VERSION "dbc-export 1 2025.20.8"

NS_ :

BS_:

BU_: ADSP APB APP APS APSB BB BMS CC CMP CMPD CP DAS DI DIF DIR DPB EPAS3P EPAS3S EPASTP EPASTS EPBL EPBR ESP EVSE FC GTW HCML HCMR HVP IBST ICR IDB LS OCS1P PARK PCS PM PMF PMR PNCD PTC RADC RCM RCM2 RCM3 RCU SCCM SCM SCS SDCR TAS TCU TPMS TRCM UI UIS UMC USM VC VCFRONT VCLEFT VCRIGHT VCSEC VEH

BO_ 259 VCRIGHT_doorStatus: 8 VCRIGHT
 SG_ VCRIGHT_doorClosureStatusFront : 0|4@1+ (1,0) [0|15] "" Vector__XXX
 SG_ VCRIGHT_doorClosureStatusRear : 4|4@1+ (1,0) [0|15] "" Vector__XXX
 SG_ VCRIGHT_frontLatchSwitch : 8|1@1+ (1,0) [0|1] "" Vector__XXX
 SG_ VCRIGHT_rearLatchSwitch : 9|1@1+ (1,0) [0|1] "" Vector__XXX
 SG_ VCRIGHT_frontHandlePulled : 10|1@1+ (1,0) [0|1] "" Vector__XXX
 SG_ VCRIGHT_rearHandlePulled : 11|1@1+ (1,0) [0|1] "" Vector__XXX
 SG_ VCRIGHT_frontRelActuatorSwitch : 12|1@1+ (1,0) [0|1] "" Vector__XXX
 SG_ VCRIGHT_rearRelActuatorSwitch : 13|1@1+ (1,0) [0|1] "" Vector__XXX
 SG_ VCRIGHT_frontLatchStatus : 14|4@1+ (1,0) [0|15] "" Vector__XXX
 SG_ VCRIGHT_rearLatchStatus : 18|4@1+ (1,0) [0|15] "" Vector__XXX
 SG_ VCRIGHT_lastDoorReqSourceFront : 22|3@1+ (1,0) [0|7] "" Vector__XXX
 SG_ VCRIGHT_lastDoorReqSourceRear : 25|3@1+ (1,0) [0|7] "" Vector__XXX
 SG_ VCRIGHT_reservedForBackCompat : 28|2@1+ (1,0) [0|3] "" Vector__XXX
 SG_ VCRIGHT_frontHandlePulledPersist : 30|1@1+ (1,0) [0|1] "" Vector__XXX
 SG_ VCRIGHT_frontIntSwitchPressed : 31|1@1+ (1,0) [0|1] "" Vector__XXX
 SG_ VCRIGHT_rearIntSwitchPressed : 32|1@1+ (1,0) [0|1] "" Vector__XXX
 SG_ VCRIGHT_mirrorTiltXPosition : 33|8@1+ (0.02,0) [0|5] "V" Vector__XXX
 SG_ VCRIGHT_mirrorTiltYPosition : 41|8@1+ (0.02,0) [0|5] "V" Vector__XXX
 SG_ VCRIGHT_mirrorState : 49|3@1+ (1,0) [0|7] "" Vector__XXX
 SG_ VCRIGHT_mirrorFoldState : 52|3@1+ (1,0) [0|7] "" Vector__XXX
 SG_ VCRIGHT_mirrorDipped : 55|1@1+ (1,0) [0|1] "" Vector__XXX
 SG_ VCRIGHT_trunkLatchStatus : 56|4@1+ (1,0) [0|15] "" Vector__XXX
 SG_ VCRIGHT_mirrorRecallState : 60|3@1+ (1,0) [0|7] "" Vector__XXX
 SG_ VCRIGHT_rearHandlePulledPersist : 63|1@1+ (1,0) [0|1] "" Vector__XXX

BO_ 2010 VCRIGHT_doorStatus2: 8 VCRIGHT
 SG_ VCRIGHT_doorStatus2Index M : 0|1@1+ (1,0) [0|1] "" Vector__XXX
 SG_ VCRIGHT_frontLatchRelDuty m1 : 8|8@1+ (1,0) [0|255] "%" Vector__XXX
 SG_ VCRIGHT_BPillarCameraHeaterState m1 : 16|3@1+ (1,0) [0|7] "" Vector__XXX
 SG_ VCRIGHT_doorLatchAjarSwitchVolta m1 : 24|8@1+ (0.02,0) [0|5] "V" Vector__XXX
 SG_ VCRIGHT_doorLatchAjarSwitch_0001 m1 : 32|8@1+ (0.02,0) [0|5] "V" Vector__XXX
 SG_ VCRIGHT_BPillarCameraHeaterCurre m1 : 40|6@1+ (0.02,0) [0|1.24] "A" Vector__XXX
 SG_ VCRIGHT_mirrorTiltXOffset m1 : 48|8@1- (0.02,0) [-2.5|2.5] "V" Vector__XXX
 SG_ VCRIGHT_mirrorTiltYOffset m1 : 56|8@1- (0.02,0) [-2.5|2.5] "V" Vector__XXX

BO_ 915 VCRIGHT_epbmDebug: 8 VCRIGHT
 SG_ VCRIGHT_epbmDebugIndex M : 0|1@1+ (1,0) [0|1] "" Vector__XXX
 SG_ VCRIGHT_epbmCaliperState m0 : 1|3@1+ (1,0) [0|7] "" Vector__XXX
 SG_ VCRIGHT_epbmMotorEnabled m0 : 4|1@1+ (1,0) [0|1] "" Vector__XXX
 SG_ VCRIGHT_epbMotorCurrent m0 : 5|11@1+ (0.01,0) [0|20.47] "A" Vector__XXX
 SG_ VCRIGHT_epbmApplyVoltage m0 : 16|11@1+ (0.01,0) [0|20.47] "A" Vector__XXX
 SG_ VCRIGHT_epbmReleaseVoltage m0 : 27|11@1+ (0.01,0) [0|20.47] "A" Vector__XXX
 SG_ VCRIGHT_summonFaultReason m0 : 40|5@1+ (1,0) [0|31] "" Vector__XXX
 SG_ VCRIGHT_epbSummonState m0 : 45|3@1+ (1,0) [0|7] "" Vector__XXX
 SG_ VCRIGHT_epbmSummonState m0 : 48|3@1+ (1,0) [0|7] "" Vector__XXX
 SG_ VCRIGHT_epbUnitStatus m0 : 51|5@1+ (1,0) [0|31] "" Vector__XXX
 SG_ VCRIGHT_epbmFaultStatus m0 : 56|2@1+ (1,0) [0|3] "" Vector__XXX
 SG_ VCRIGHT_epbFaultStatus m0 : 58|2@1+ (1,0) [0|3] "" Vector__XXX
 SG_ VCRIGHT_epbmSystemStatus m0 : 60|4@1+ (1,0) [0|15] "" Vector__XXX

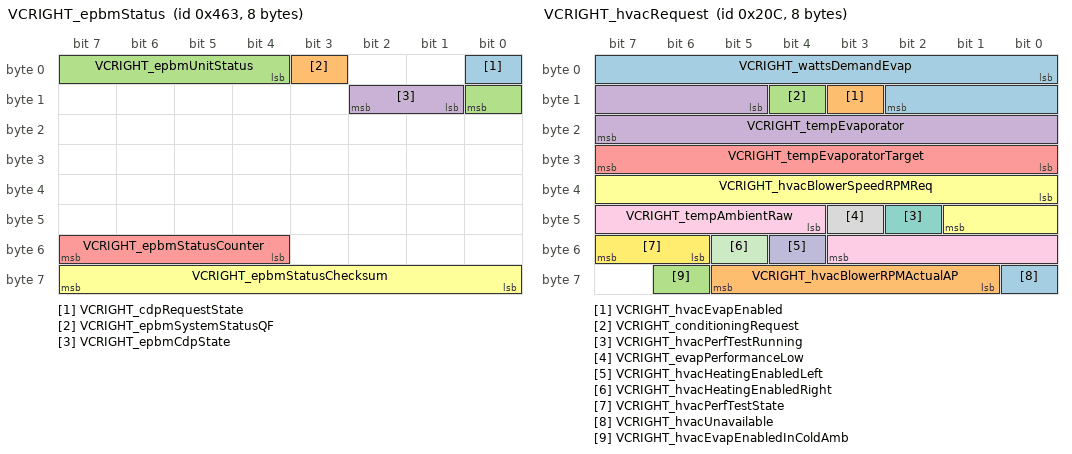
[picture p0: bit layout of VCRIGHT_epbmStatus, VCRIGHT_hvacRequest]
BO_ 1123 VCRIGHT_epbmStatus: 8 VCRIGHT
 SG_ VCRIGHT_cdpRequestState : 0|1@1+ (1,0) [0|1] "" Vector__XXX
 SG_ VCRIGHT_epbmSystemStatusQF : 3|1@1+ (1,0) [0|1] "" Vector__XXX
 SG_ VCRIGHT_epbmUnitStatus : 4|5@1+ (1,0) [0|31] "" Vector__XXX
 SG_ VCRIGHT_epbmCdpState : 9|2@1+ (1,0) [0|3] "" Vector__XXX
 SG_ VCRIGHT_epbmStatusCounter : 52|4@1+ (1,0) [0|15] "" Vector__XXX
 SG_ VCRIGHT_epbmStatusChecksum : 56|8@1+ (1,0) [0|255] "" Vector__XXX

BO_ 524 VCRIGHT_hvacRequest: 8 VCRIGHT
 SG_ VCRIGHT_wattsDemandEvap : 0|11@1+ (5,0) [0|10000] "W" Vector__XXX
 SG_ VCRIGHT_hvacEvapEnabled : 11|1@1+ (1,0) [0|1] "" Vector__XXX
 SG_ VCRIGHT_conditioningRequest : 12|1@1+ (1,0) [0|1] "" Vector__XXX
 SG_ VCRIGHT_tempEvaporator : 13|11@1+ (0.1,-40) [-40|105] "degC" Vector__XXX
 SG_ VCRIGHT_tempEvaporatorTarget : 24|8@1+ (0.2,0) [0|50] "degC" Vector__XXX
 SG_ VCRIGHT_hvacBlowerSpeedRPMReq : 32|10@1+ (5,0) [0|5115] "RPM" Vector__XXX
 SG_ VCRIGHT_hvacPerfTestRunning : 42|1@1+ (1,0) [0|1] "" Vector__XXX
 SG_ VCRIGHT_evapPerformanceLow : 43|1@1+ (1,0) [0|1] "" Vector__XXX
 SG_ VCRIGHT_tempAmbientRaw : 44|8@1+ (0.5,-40) [-40|80] "degC" Vector__XXX
 SG_ VCRIGHT_hvacHeatingEnabledLeft : 52|1@1+ (1,0) [0|1] "" Vector__XXX
 SG_ VCRIGHT_hvacHeatingEnabledRight : 53|1@1+ (1,0) [0|1] "" Vector__XXX
 SG_ VCRIGHT_hvacPerfTestState : 54|2@1+ (1,0) [0|3] "" Vector__XXX
 SG_ VCRIGHT_hvacUnavailable : 56|1@1+ (1,0) [0|1] "" Vector__XXX
 SG_ VCRIGHT_hvacBlowerRPMActualAP : 57|5@1+ (200,0) [0|4200] "rpm" Vector__XXX
 SG_ VCRIGHT_hvacEvapEnabledInColdAmb : 62|1@1+ (1,0) [0|1] "" Vector__XXX

BO_ 579 VCRIGHT_hvacStatus: 8 VCRIGHT
 SG_ VCRIGHT_hvacStatusIndex M : 0|3@1+ (1,0) [0|7] "" Vector__XXX
 SG_ VCRIGHT_childModeHVACState m0 : 20|2@1+ (1,0) [0|3] "" Vector__XXX
 SG_ VCRIGHT_dogModeState m0 : 22|4@1+ (1,0) [0|15] "" Vector__XXX
 SG_ VCRIGHT_hvacCabinTempEstValid m0 : 26|1@1+ (1,0) [0|1] "" Vector__XXX
 SG_ VCRIGHT_COPNotRunningReasonFilte m0 : 27|3@1+ (1,0) [0|7] "" Vector__XXX
 SG_ VCRIGHT_hvacCabinTempEst m0 : 30|11@1+ (0.1,-40) [-40|164] "degC" Vector__XXX
 SG_ VCRIGHT_hvacAirDistributionMode m0 : 41|3@1+ (1,0) [0|7] "" Vector__XXX
 SG_ VCRIGHT_hvacBlowerSegment m0 : 44|4@1+ (1,0) [0|15] "" Vector__XXX
 SG_ VCRIGHT_hvacRecirc m0 : 48|2@1+ (1,0) [0|3] "" Vector__XXX
 SG_ VCRIGHT_hvacACRunning m0 : 50|1@1+ (1,0) [0|1] "" Vector__XXX
 SG_ VCRIGHT_hvacPowerState m0 : 51|3@1+ (1,0) [0|7] "" Vector__XXX
 SG_ VCRIGHT_hvacVentStatus m0 : 54|2@1+ (1,0) [0|3] "" Vector__XXX
 SG_ VCRIGHT_hvacSecondRowState m0 : 56|3@1+ (1,0) [0|7] "" Vector__XXX
 SG_ VCRIGHT_hvacSystemNominal m0 : 59|1@1+ (1,0) [0|1] "" Vector__XXX
 SG_ VCRIGHT_hvacModelInitStatus m0 : 60|4@1+ (1,0) [0|15] "" Vector__XXX
 SG_ VCRIGHT_hvacMassflowRefrigSysRig m1 : 3|7@1+ (1,0) [0|125] "g/s" Vector__XXX
 SG_ VCRIGHT_hvacRecircDoorPercent m1 : 10|6@1+ (1.6,0) [0|100] "%" Vector__XXX
 SG_ VCRIGHT_tempDuctLeft m1 : 16|8@1+ (0.5,-22) [-22|105] "degC" Vector__XXX
 SG_ VCRIGHT_hvacMassflowRefrigSystem m1 : 24|8@1+ (1,0) [0|250] "g/s" Vector__XXX
 SG_ VCRIGHT_tempDuctRight m1 : 32|8@1+ (0.5,-22) [-22|105] "degC" Vector__XXX
 SG_ VCRIGHT_hvacMassflowRefrigSysLef m1 : 40|7@1+ (1,0) [0|125] "g/s" Vector__XXX
 SG_ VCRIGHT_hvacDuctTargetLeft m1 : 48|8@1+ (0.5,-40) [-40|80] "degC" Vector__XXX
 SG_ VCRIGHT_hvacDuctTargetRight m1 : 56|8@1+ (0.5,-40) [-40|80] "degC" Vector__XXX
 SG_ VCRIGHT_enableTripleCameraFanPow m2 : 9|1@1+ (1,0) [0|1] "" Vector__XXX
 SG_ VCRIGHT_tempDuctRightUpper m2 : 10|8@1+ (0.5,-22) [-22|105] "degC" Vector__XXX
 SG_ VCRIGHT_hpSplitTempsEnabled m2 : 18|1@1+ (1,0) [0|1] "" Vector__XXX
 SG_ VCRIGHT_hvacEvapInletTempEstimat m2 : 19|10@1+ (0.13,-40) [-40|90] "degC" Vector__XXX
 SG_ VCRIGHT_tempMonitorNotNominal m2 : 29|1@1+ (1,0) [0|1] "" Vector__XXX
 SG_ VCRIGHT_hvacCabinAtTempTarget m2 : 30|1@1+ (1,0) [0|1] "" Vector__XXX
 SG_ VCRIGHT_hvacReqSecondRow m2 : 31|1@1+ (1,0) [0|1] "" Vector__XXX
 SG_ VCRIGHT_hvacAirflowReason m2 : 32|5@1+ (1,0) [0|31] "" Vector__XXX
 SG_ VCRIGHT_autoHvacBlowerShouldLimi m2 : 37|1@1+ (1,0) [0|1] "" Vector__XXX
 SG_ VCRIGHT_solarLoadOnVehicle m2 : 40|8@1+ (4,0) [0|1020] "W/m2" Vector__XXX
 SG_ VCRIGHT_refrigDistCommanded m2 : 48|1@1+ (1,0) [0|1] "" Vector__XXX
 SG_ VCRIGHT_hvacFrontRightSeatFanSta m2 : 49|2@1+ (1,0) [0|3] "" Vector__XXX
 SG_ VCRIGHT_hvacFrontLeftSeatFanStat m2 : 51|2@1+ (1,0) [0|3] "" Vector__XXX
 SG_ VCRIGHT_hvacFrontRightSeatHeatSt m3 : 4|2@1+ (1,0) [0|3] "" Vector__XXX
 SG_ VCRIGHT_hvacSeatFrontLeftTempTar m3 : 6|8@1+ (0.5,-40) [-40|80] "degC" Vector__XXX
 SG_ VCRIGHT_hvacManualToAutoNotify m3 : 14|3@1+ (1,0) [0|7] "" Vector__XXX
 SG_ VCRIGHT_hvacRequestsFullAuto m3 : 17|3@1+ (1,0) [0|7] "" Vector__XXX
 SG_ VCRIGHT_passengerPresentHvacCycl m3 : 21|1@1+ (1,0) [0|1] "" Vector__XXX
 SG_ VCRIGHT_hvacRequestsAutoIntake m3 : 22|1@1+ (1,0) [0|1] "" Vector__XXX
 SG_ VCRIGHT_steeringWheelHeatStatus m3 : 24|2@1+ (1,0) [0|3] "" Vector__XXX
 SG_ VCRIGHT_autoDefogStatus m3 : 26|2@1+ (1,0) [0|3] "" Vector__XXX
 SG_ VCRIGHT_solarElevation m3 : 31|9@1- (0.5,0) [-127.5|127.5] "deg" Vector__XXX
 SG_ VCRIGHT_minsToSunrise m3 : 40|8@1+ (10,0) [0|2540] "min" Vector__XXX
 SG_ VCRIGHT_minsToSunset m3 : 48|8@1+ (10,0) [0|2540] "min" Vector__XXX
 SG_ VCRIGHT_hvacLimitedReasonRight m3 : 56|3@1+ (1,0) [0|7] "" Vector__XXX
 SG_ VCRIGHT_hvacLimitedReasonLeft m3 : 59|3@1+ (1,0) [0|7] "" Vector__XXX
 SG_ VCRIGHT_hvacOverheatProtActive m3 : 63|1@1+ (1,0) [0|1] "" Vector__XXX
 SG_ VCRIGHT_tempDuctLeftUpper m4 : 10|8@1+ (0.5,-22) [-22|105] "degC" Vector__XXX
 SG_ VCRIGHT_hvacFrontLeftSeatHeatSta m4 : 18|2@1+ (1,0) [0|3] "" Vector__XXX
 SG_ VCRIGHT_hvacQdotLeft m4 : 20|14@1+ (1,-8191) [-8191|8191] "W" Vector__XXX
 SG_ VCRIGHT_hvacQdotRight m4 : 34|14@1+ (1,-8191) [-8191|8191] "W" Vector__XXX
 SG_ VCRIGHT_tempDuctLeftLower m4 : 48|8@1+ (0.5,-22) [-22|105] "degC" Vector__XXX
 SG_ VCRIGHT_tempDuctRightLower m4 : 56|8@1+ (0.5,-22) [-22|105] "degC" Vector__XXX
 SG_ VCRIGHT_modeledCabinPressure m5 : 24|8@1+ (1,0) [0|255] "Pa" Vector__XXX
 SG_ VCRIGHT_blowerTorqueIndex m5 : 32|7@1+ (1,0) [0|127] "%" Vector__XXX
 SG_ VCRIGHT_autoSwingLeftPosX m5 : 39|8@1+ (0.4,0) [0|100] "%" Vector__XXX
 SG_ VCRIGHT_autoSwingRightPositionX m5 : 48|8@1+ (0.4,0) [0|100] "%" Vector__XXX
 SG_ VCRIGHT_autoSwingAvailable m5 : 56|1@1+ (1,0) [0|1] "" Vector__XXX

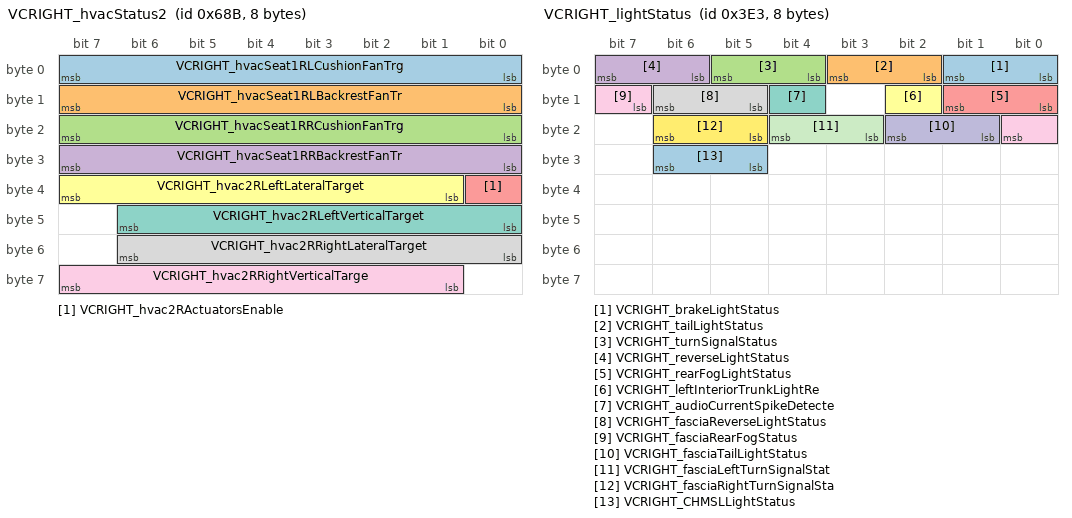
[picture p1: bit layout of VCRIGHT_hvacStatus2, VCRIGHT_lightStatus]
BO_ 1675 VCRIGHT_hvacStatus2: 8 VCRIGHT
 SG_ VCRIGHT_hvacSeat1RLCushionFanTrg : 0|8@1+ (0.5,0) [0|100] "%" Vector__XXX
 SG_ VCRIGHT_hvacSeat1RLBackrestFanTr : 8|8@1+ (0.5,0) [0|100] "%" Vector__XXX
 SG_ VCRIGHT_hvacSeat1RRCushionFanTrg : 16|8@1+ (0.5,0) [0|100] "%" Vector__XXX
 SG_ VCRIGHT_hvacSeat1RRBackrestFanTr : 24|8@1+ (0.5,0) [0|100] "%" Vector__XXX
 SG_ VCRIGHT_hvac2RActuatorsEnable : 32|1@1+ (1,0) [0|1] "" Vector__XXX
 SG_ VCRIGHT_hvac2RLeftLateralTarget : 33|7@1+ (1,0) [0|100] "%" Vector__XXX
 SG_ VCRIGHT_hvac2RLeftVerticalTarget : 40|7@1+ (1,0) [0|100] "%" Vector__XXX
 SG_ VCRIGHT_hvac2RRightLateralTarget : 48|7@1+ (1,0) [0|100] "%" Vector__XXX
 SG_ VCRIGHT_hvac2RRightVerticalTarge : 57|7@1+ (1,0) [0|100] "%" Vector__XXX

BO_ 774 VCRIGHT_info: 8 VCRIGHT
 SG_ VCRIGHT_infoIndex M : 0|8@1+ (1,0) [0|255] "" Vector__XXX
 SG_ VCRIGHT_infoBuildType m10 : 8|3@1+ (1,0) [0|7] "" Vector__XXX
 SG_ VCRIGHT_infoBuildConfigId m10 : 16|16@1+ (1,0) [0|65535] "" Vector__XXX
 SG_ VCRIGHT_infoHardwareId m10 : 32|16@1+ (1,0) [0|65535] "" Vector__XXX
 SG_ VCRIGHT_infoComponentId m10 : 48|16@1+ (1,0) [0|65535] "" Vector__XXX
 SG_ VCRIGHT_infoPcbaId m11 : 8|8@1+ (1,0) [0|255] "" Vector__XXX
 SG_ VCRIGHT_infoAssemblyId m11 : 16|8@1+ (1,0) [0|255] "" Vector__XXX
 SG_ VCRIGHT_infoUsageId m11 : 24|16@1+ (1,0) [0|65535] "" Vector__XXX
 SG_ VCRIGHT_infoSubUsageId m11 : 40|16@1+ (1,0) [0|65535] "" Vector__XXX
 SG_ VCRIGHT_infoAppCrc m13 : 8|32@1+ (1,0) [0|4294967295] "" Vector__XXX
 SG_ VCRIGHT_infoAppGitHash m17 : 8|56@1+ (1,0) [0|7.20575940379e+16] "" Vector__XXX
 SG_ VCRIGHT_infoBootGitHash m18 : 8|56@1+ (1,0) [0|7.20575940379e+16] "" Vector__XXX
 SG_ VCRIGHT_infoPlatformType m19 : 8|8@1+ (1,0) [0|255] "" Vector__XXX
 SG_ VCRIGHT_infoBootUdsProtoVersion m20 : 8|16@1+ (1,0) [0|65535] "" Vector__XXX
 SG_ VCRIGHT_infoBootCrc m20 : 24|32@1+ (1,0) [0|4294967295] "" Vector__XXX

BO_ 995 VCRIGHT_lightStatus: 8 VCRIGHT
 SG_ VCRIGHT_brakeLightStatus : 0|2@1+ (1,0) [0|3] "" Vector__XXX
 SG_ VCRIGHT_tailLightStatus : 2|2@1+ (1,0) [0|3] "" Vector__XXX
 SG_ VCRIGHT_turnSignalStatus : 4|2@1+ (1,0) [0|3] "" Vector__XXX
 SG_ VCRIGHT_reverseLightStatus : 6|2@1+ (1,0) [0|3] "" Vector__XXX
 SG_ VCRIGHT_rearFogLightStatus : 8|2@1+ (1,0) [0|3] "" Vector__XXX
 SG_ VCRIGHT_leftInteriorTrunkLightRe : 10|1@1+ (1,0) [0|1] "" Vector__XXX
 SG_ VCRIGHT_audioCurrentSpikeDetecte : 12|1@1+ (1,0) [0|1] "" Vector__XXX
 SG_ VCRIGHT_fasciaReverseLightStatus : 13|2@1+ (1,0) [0|3] "" Vector__XXX
 SG_ VCRIGHT_fasciaRearFogStatus : 15|2@1+ (1,0) [0|3] "" Vector__XXX
 SG_ VCRIGHT_fasciaTailLightStatus : 17|2@1+ (1,0) [0|3] "" Vector__XXX
 SG_ VCRIGHT_fasciaLeftTurnSignalStat : 19|2@1+ (1,0) [0|3] "" Vector__XXX
 SG_ VCRIGHT_fasciaRightTurnSignalSta : 21|2@1+ (1,0) [0|3] "" Vector__XXX
 SG_ VCRIGHT_CHMSLLightStatus : 29|2@1+ (1,0) [0|3] "" Vector__XXX

BO_ 1803 VCRIGHT_logging0point1Hz: 8 VCRIGHT
 SG_ VCRIGHT_logging0point1HzIndex M : 0|4@1+ (1,0) [0|15] "" Vector__XXX
 SG_ VCRIGHT_cabinAirFilterLifeRemain m2 : 8|7@1+ (1,0) [0|127] "%" Vector__XXX
 SG_ VCRIGHT_HEPAAirFilterLifeRemaini m2 : 16|7@1+ (1,0) [0|127] "%" Vector__XXX
 SG_ VCRIGHT_leftPTCCompromisedRod m2 : 24|3@1+ (1,0) [0|7] "" Vector__XXX
 SG_ VCRIGHT_rightPTCCompromisedRod m2 : 27|3@1+ (1,0) [0|7] "" Vector__XXX
 SG_ VCRIGHT_hepaFilterHealthScore m2 : 32|7@1+ (1,0) [0|127] "%" Vector__XXX
 SG_ VCRIGHT_cabinFilterHealthScore m2 : 40|7@1+ (1,0) [0|127] "%" Vector__XXX
 SG_ VCRIGHT_cabinTempBreathLevelFOff m2 : 47|8@1+ (0.5,-40) [-40|80] "degC" Vector__XXX
 SG_ VCRIGHT_airDistributionModeAdjus m2 : 55|9@1+ (0.001,1) [1|1.5] "-" Vector__XXX
 SG_ VCRIGHT_hvacLHBleedEndStop m3 : 8|8@1+ (0.02,0) [0|5] "V" Vector__XXX
 SG_ VCRIGHT_hvacRHBleedEndStop m3 : 16|8@1+ (0.02,0) [0|5] "V" Vector__XXX
 SG_ VCRIGHT_hvacLHVaneEndStop m3 : 24|8@1+ (0.02,0) [0|5] "V" Vector__XXX
 SG_ VCRIGHT_hvacRHVaneEndStop m3 : 32|8@1+ (0.02,0) [0|5] "V" Vector__XXX
 SG_ VCRIGHT_hvacUpperModeEndStop m3 : 40|8@1+ (0.02,0) [0|5] "V" Vector__XXX
 SG_ VCRIGHT_hvacLowerModeEndStop m3 : 48|8@1+ (0.02,0) [0|5] "V" Vector__XXX
 SG_ VCRIGHT_hvacIntakeEndStop m3 : 56|8@1+ (0.02,0) [0|5] "V" Vector__XXX
 SG_ VCRIGHT_hvacLHBleedZeroStop m4 : 8|8@1+ (0.02,0) [0|5] "V" Vector__XXX
 SG_ VCRIGHT_hvacRHBleedZeroStop m4 : 16|8@1+ (0.02,0) [0|5] "V" Vector__XXX
 SG_ VCRIGHT_hvacLHVaneZeroStop m4 : 24|8@1+ (0.02,0) [0|5] "V" Vector__XXX
 SG_ VCRIGHT_hvacRHVaneZeroStop m4 : 32|8@1+ (0.02,0) [0|5] "V" Vector__XXX
 SG_ VCRIGHT_hvacUpperModeZeroStop m4 : 40|8@1+ (0.02,0) [0|5] "V" Vector__XXX
 SG_ VCRIGHT_hvacLowerModeZeroStop m4 : 48|8@1+ (0.02,0) [0|5] "V" Vector__XXX
 SG_ VCRIGHT_hvacIntakeZeroStop m4 : 56|8@1+ (0.02,0) [0|5] "V" Vector__XXX
 SG_ VCRIGHT_ambientTempLimp m6 : 8|8@1+ (0.5,-40) [-40|80] "degC" Vector__XXX
 SG_ VCRIGHT_cabinProbeTempLimp m6 : 16|8@1+ (0.5,-40) [-40|80] "degC" Vector__XXX
 SG_ VCRIGHT_thsTempLimp m6 : 24|8@1+ (0.5,-40) [-40|80] "degC" Vector__XXX
 SG_ VCRIGHT_thsCabinWaterMassLimp m6 : 32|8@1+ (0.5,0) [0|124] "g/kg" Vector__XXX
 SG_ VCRIGHT_thsSolarIrradianceLimp m6 : 40|8@1+ (5,0) [0|1270] "W/m2" Vector__XXX
 SG_ VCRIGHT_silentWakeRecordCount m6 : 48|5@1+ (1,0) [0|31] "" Vector__XXX
 SG_ VCRIGHT_evapCondensateMass m7 : 8|8@1+ (2,0) [0|500] "g" Vector__XXX
 SG_ VCRIGHT_airwaveRightLateralTotal m7 : 16|16@1+ (6100,0) [0|399763500] "deg" Vector__XXX
 SG_ VCRIGHT_airwaveLeftLateralTotalT m7 : 32|16@1+ (6100,0) [0|399763500] "deg" Vector__XXX

BO_ 611 VCRIGHT_logging10Hz: 8 VCRIGHT
 SG_ VCRIGHT_logging10HzIndex M : 0|3@1+ (1,0) [0|7] "" Vector__XXX
 SG_ VCRIGHT_hvacLHBleedTarget m0 : 8|8@1+ (0.4,0) [0|100] "%" Vector__XXX
 SG_ VCRIGHT_hvacRHBleedTarget m0 : 16|8@1+ (0.4,0) [0|100] "%" Vector__XXX
 SG_ VCRIGHT_hvacLHVaneTarget m0 : 24|8@1+ (0.4,0) [0|100] "%" Vector__XXX
 SG_ VCRIGHT_hvacRHVaneTarget m0 : 32|8@1+ (0.4,0) [0|100] "%" Vector__XXX
 SG_ VCRIGHT_hvacUpperModeTarget m0 : 40|8@1+ (0.4,0) [0|100] "%" Vector__XXX
 SG_ VCRIGHT_hvacLowerModeTarget m0 : 48|8@1+ (0.4,0) [0|100] "%" Vector__XXX
 SG_ VCRIGHT_hvacIntakeTarget m0 : 56|8@1+ (0.4,0) [0|100] "%" Vector__XXX
 SG_ VCRIGHT_hvacLHBleedPosition m1 : 8|8@1+ (0.4,0) [0|100] "%" Vector__XXX
 SG_ VCRIGHT_hvacRHBleedPosition m1 : 16|8@1+ (0.4,0) [0|100] "%" Vector__XXX
 SG_ VCRIGHT_hvacLHVanePosition m1 : 24|8@1+ (0.4,0) [0|100] "%" Vector__XXX
 SG_ VCRIGHT_hvacRHVanePosition m1 : 32|8@1+ (0.4,0) [0|100] "%" Vector__XXX
 SG_ VCRIGHT_hvacUpperModePosition m1 : 40|8@1+ (0.4,0) [0|100] "%" Vector__XXX
 SG_ VCRIGHT_hvacLowerModePosition m1 : 48|8@1+ (0.4,0) [0|100] "%" Vector__XXX
 SG_ VCRIGHT_hvacIntakePosition m1 : 56|8@1+ (0.4,0) [0|100] "%" Vector__XXX
 SG_ VCRIGHT_hvacLHBleedActuatorState m2 : 3|2@1+ (1,0) [0|3] "" Vector__XXX
 SG_ VCRIGHT_hvacRHBleedActuatorState m2 : 5|2@1+ (1,0) [0|3] "" Vector__XXX
 SG_ VCRIGHT_hvacLHVaneActuatorState m2 : 8|2@1+ (1,0) [0|3] "" Vector__XXX
 SG_ VCRIGHT_hvacRHVaneActuatorState m2 : 10|2@1+ (1,0) [0|3] "" Vector__XXX
 SG_ VCRIGHT_hvacUpperModeActState m2 : 12|2@1+ (1,0) [0|3] "" Vector__XXX
 SG_ VCRIGHT_hvacLowerModeActState m2 : 14|2@1+ (1,0) [0|3] "" Vector__XXX
 SG_ VCRIGHT_hvacIntakeActuatorState m2 : 16|2@1+ (1,0) [0|3] "" Vector__XXX
 SG_ VCRIGHT_EvapPulldownBiasActive m2 : 20|1@1+ (1,0) [0|1] "" Vector__XXX
 SG_ VCRIGHT_tempDatLeftEst m2 : 21|9@1+ (0.5,-22) [-22|200] "degC" Vector__XXX
 SG_ VCRIGHT_tempDatRightEst m2 : 30|9@1+ (0.5,-22) [-22|200] "degC" Vector__XXX
 SG_ VCRIGHT_tempDuctLeftEst m2 : 40|8@1+ (0.5,-22) [-22|105] "degC" Vector__XXX
 SG_ VCRIGHT_tempDuctRightEst m2 : 48|8@1+ (0.5,-22) [-22|105] "degC" Vector__XXX
 SG_ VCRIGHT_ptcHeaterBadRodDetection m2 : 56|4@1+ (1,0) [0|15] "" Vector__XXX
 SG_ VCRIGHT_leftVerticalActuatorDuty m4 : 8|6@1- (4,0) [-100|100] "%" Vector__XXX
 SG_ VCRIGHT_leftLateralActuatorDuty m4 : 16|6@1- (4,0) [-100|100] "%" Vector__XXX
 SG_ VCRIGHT_rightVerticalActuatorDut m4 : 24|6@1- (4,0) [-100|100] "%" Vector__XXX
 SG_ VCRIGHT_rightLateralActuatorDuty m4 : 30|6@1- (4,0) [-100|100] "%" Vector__XXX
 SG_ VCRIGHT_frontLeftSeatTempTargetQ m4 : 36|6@1+ (0.75,20) [20|60] "degC" Vector__XXX
 SG_ VCRIGHT_frontRightSeatTempTarget m4 : 42|6@1+ (1,20) [20|60] "degC" Vector__XXX

BO_ 691 VCRIGHT_logging1Hz: 8 VCRIGHT
 SG_ VCRIGHT_logging1HzIndex M : 0|5@1+ (1,0) [0|31] "" Vector__XXX
 SG_ VCRIGHT_tempIncarCabinProbe m0 : 8|8@1+ (0.5,-40) [-40|85] "degC" Vector__XXX
 SG_ VCRIGHT_tempIncarCabinDeep m0 : 16|8@1+ (0.5,-40) [-40|85] "degC" Vector__XXX
 SG_ VCRIGHT_cabinTempInteriorL2 m0 : 24|8@1+ (0.5,-40) [-40|80] "degC" Vector__XXX
 SG_ VCRIGHT_tempIncarCabinMid m0 : 32|8@1+ (0.5,-40) [-40|85] "degC" Vector__XXX
 SG_ VCRIGHT_cabinTempInteriorSunnyL2 m0 : 40|8@1+ (0.6,-40) [-40|100] "degC" Vector__XXX
 SG_ VCRIGHT_cabinTempInteriorL3 m0 : 48|8@1+ (0.5,-40) [-40|80] "degC" Vector__XXX
 SG_ VCRIGHT_cabinTempInteriorSunnyL3 m0 : 56|8@1+ (0.6,-40) [-40|100] "degC" Vector__XXX
 SG_ VCRIGHT_cabinTempGlassRoof m1 : 8|8@1+ (0.5,-40) [-40|80] "degC" Vector__XXX
 SG_ VCRIGHT_cabinTempWindshield m1 : 16|8@1+ (0.5,-40) [-40|80] "degC" Vector__XXX
 SG_ VCRIGHT_cabinTempInterior m1 : 24|8@1+ (0.5,-40) [-40|80] "degC" Vector__XXX
 SG_ VCRIGHT_cabinTempInteriorSunny m1 : 32|8@1+ (0.6,-40) [-40|100] "degC" Vector__XXX
 SG_ VCRIGHT_cabinTempSideGlassLeft m1 : 40|8@1+ (0.5,-40) [-40|80] "degC" Vector__XXX
 SG_ VCRIGHT_cabinTempSideGlassRight m1 : 48|8@1+ (0.5,-40) [-40|80] "degC" Vector__XXX
 SG_ VCRIGHT_cabinTempBreathLevel m1 : 56|8@1+ (0.5,-40) [-40|80] "degC" Vector__XXX
 SG_ VCRIGHT_pcbaTemperature m2 : 5|11@1+ (0.125,-40) [-40|150] "degC" Vector__XXX
 SG_ VCRIGHT_wattsHeaterLeftTotal m2 : 16|10@1+ (5,0) [0|4000] "W" Vector__XXX
 SG_ VCRIGHT_wattsHeaterRightTotal m2 : 26|10@1+ (5,0) [0|4000] "W" Vector__XXX
 SG_ VCRIGHT_qdotLeftFFUnsat m2 : 36|9@1- (10,0) [-1500|1500] "W" Vector__XXX
 SG_ VCRIGHT_qdotRightFFUnsat m2 : 45|9@1- (10,0) [-1500|1500] "W" Vector__XXX
 SG_ VCRIGHT_nvhLevelDb m2 : 54|9@1+ (0.1,30) [30|80] "dB" Vector__XXX
 SG_ VCRIGHT_hvacSetTempActualLeft m3 : 8|8@1+ (0.1,15) [15|28] "degC" Vector__XXX
 SG_ VCRIGHT_hvacSetTempActualRight m3 : 16|8@1+ (0.1,15) [15|28] "degC" Vector__XXX
 SG_ VCRIGHT_hvacAutoTransitionReason m3 : 24|5@1+ (1,0) [0|31] "" Vector__XXX
 SG_ VCRIGHT_hvacMassflowTarget m3 : 29|8@1+ (1,0) [0|200] "g/s" Vector__XXX
 SG_ VCRIGHT_hvacQdotLimitedLeft m3 : 37|1@1+ (1,0) [0|1] "" Vector__XXX
 SG_ VCRIGHT_hvacQdotLimitedRight m3 : 38|1@1+ (1,0) [0|1] "" Vector__XXX
 SG_ VCRIGHT_LHPanelAirflowBlocked m3 : 39|1@1+ (1,0) [0|1] "" Vector__XXX
 SG_ VCRIGHT_RHPanelAirflowBlocked m3 : 40|1@1+ (1,0) [0|1] "" Vector__XXX
 SG_ VCRIGHT_floorAirflowBlocked m3 : 41|1@1+ (1,0) [0|1] "" Vector__XXX
 SG_ VCRIGHT_defrostAirflowBlocked m3 : 42|1@1+ (1,0) [0|1] "" Vector__XXX
 SG_ VCRIGHT_hvacFilterLifeDetectActi m3 : 43|1@1+ (1,0) [0|1] "" Vector__XXX
 SG_ VCRIGHT_hvacLHBleedOperationMode m3 : 44|1@1+ (1,0) [0|1] "" Vector__XXX
 SG_ VCRIGHT_hvacRHBleedOperationMode m3 : 45|1@1+ (1,0) [0|1] "" Vector__XXX
 SG_ VCRIGHT_hvacLHVaneOperationMode m3 : 46|1@1+ (1,0) [0|1] "" Vector__XXX
 SG_ VCRIGHT_hvacRHVaneOperationMode m3 : 47|1@1+ (1,0) [0|1] "" Vector__XXX
 SG_ VCRIGHT_hvacUpperModeOpMode m3 : 48|1@1+ (1,0) [0|1] "" Vector__XXX
 SG_ VCRIGHT_hvacLowerModeOpMode m3 : 49|1@1+ (1,0) [0|1] "" Vector__XXX
 SG_ VCRIGHT_hvacIntakeOperationMode m3 : 50|1@1+ (1,0) [0|1] "" Vector__XXX
 SG_ VCRIGHT_isProbeFeedbackApplied m3 : 52|3@1+ (1,0) [0|7] "" Vector__XXX
 SG_ VCRIGHT_feedbackPullDownScalar m3 : 55|2@1+ (30,70) [70|130] "-" Vector__XXX
 SG_ VCRIGHT_feedForwardPullDownScala m3 : 57|6@1+ (1,70) [70|130] "-" Vector__XXX
 SG_ VCRIGHT_convectionTargetLeft m4 : 5|9@1+ (4,-1000) [-1000|1000] "W/m2" Vector__XXX
 SG_ VCRIGHT_convectionTargetRight m4 : 14|9@1+ (4,-1000) [-1000|1000] "W/m2" Vector__XXX
 SG_ VCRIGHT_convectionDeliveredLeft m4 : 23|9@1+ (4,-1000) [-1000|1000] "W/m2" Vector__XXX
 SG_ VCRIGHT_convectionDeliveredRight m4 : 32|9@1+ (4,-1000) [-1000|1000] "W/m2" Vector__XXX
 SG_ VCRIGHT_solarLoadRightOccupant m4 : 41|7@1+ (2,0) [0|254] "W/m2" Vector__XXX
 SG_ VCRIGHT_solarLoadLeftOccupant m4 : 48|7@1+ (2,0) [0|254] "W/m2" Vector__XXX
 SG_ VCRIGHT_ptcShutOutletMitigationA m4 : 55|1@1+ (1,0) [0|1] "" Vector__XXX
 SG_ VCRIGHT_solarLoadFromThsTemp m4 : 56|8@1+ (8,-1020) [-1020|1016] "W/m2" Vector__XXX
 SG_ VCRIGHT_ptcHeaterTempDuctHigh m5 : 5|1@1+ (1,0) [0|1] "" Vector__XXX
 SG_ VCRIGHT_ptcHeaterTempDuctFault m5 : 6|1@1+ (1,0) [0|1] "" Vector__XXX
 SG_ VCRIGHT_ptcHeaterNoAirflow m5 : 7|1@1+ (1,0) [0|1] "" Vector__XXX
 SG_ VCRIGHT_ptcHeaterHvacActNotReady m5 : 8|1@1+ (1,0) [0|1] "" Vector__XXX
 SG_ VCRIGHT_ptcHeaterNoUiRequest m5 : 9|1@1+ (1,0) [0|1] "" Vector__XXX
 SG_ VCRIGHT_ptcHeaterNoHighVoltage m5 : 10|1@1+ (1,0) [0|1] "" Vector__XXX
 SG_ VCRIGHT_ptcHeaterLAirPathBlocked m5 : 11|1@1+ (1,0) [0|1] "" Vector__XXX
 SG_ VCRIGHT_ptcHeaterRAirPathBlocked m5 : 12|1@1+ (1,0) [0|1] "" Vector__XXX
 SG_ VCRIGHT_ptcHeaterReqAirpathBlock m5 : 13|1@1+ (1,0) [0|1] "" Vector__XXX
 SG_ VCRIGHT_hvacQdotFeedforward m5 : 16|16@1+ (1,-32767) [-32767|32767] "W" Vector__XXX
 SG_ VCRIGHT_evapLoadInFresh m5 : 32|8@1+ (35,0) [0|8000] "W" Vector__XXX
 SG_ VCRIGHT_evapLoadInRecirc m5 : 40|8@1+ (35,0) [0|8000] "W" Vector__XXX
 SG_ VCRIGHT_cabinTempWshldDefog m5 : 48|8@1+ (0.5,-40) [-40|80] "degC" Vector__XXX
 SG_ VCRIGHT_cabinTempWshldDefogTop m5 : 56|8@1+ (0.5,-40) [-40|80] "degC" Vector__XXX
 SG_ VCRIGHT_hvacLHBleedVoltage m6 : 8|8@1+ (0.02,0) [0|5] "V" Vector__XXX
 SG_ VCRIGHT_hvacRHBleedVoltage m6 : 16|8@1+ (0.02,0) [0|5] "V" Vector__XXX
 SG_ VCRIGHT_hvacLHVaneVoltage m6 : 24|8@1+ (0.02,0) [0|5] "V" Vector__XXX
 SG_ VCRIGHT_hvacRHVaneVoltage m6 : 32|8@1+ (0.02,0) [0|5] "V" Vector__XXX
 SG_ VCRIGHT_hvacUpperModeVoltage m6 : 40|8@1+ (0.02,0) [0|5] "V" Vector__XXX
 SG_ VCRIGHT_hvacLowerModeVoltage m6 : 48|8@1+ (0.02,0) [0|5] "V" Vector__XXX
 SG_ VCRIGHT_hvacIntakeVoltage m6 : 56|8@1+ (0.02,0) [0|5] "V" Vector__XXX
 SG_ VCRIGHT_cabinTempBreathLevelFHea m7 : 8|8@1+ (0.5,-40) [-40|80] "degC" Vector__XXX
 SG_ VCRIGHT_cabinTempBreathLevelFCoo m7 : 16|8@1+ (0.5,-40) [-40|80] "degC" Vector__XXX
 SG_ VCRIGHT_cabinTempBreathLeve_0002 m7 : 24|8@1+ (0.5,-40) [-40|80] "degC" Vector__XXX
 SG_ VCRIGHT_cabinTempBreathLevelF5mi m7 : 32|8@1+ (0.5,-40) [-40|80] "degC" Vector__XXX
 SG_ VCRIGHT_cabinTempBreathLeve_0001 m7 : 40|8@1+ (0.5,-40) [-40|80] "degC" Vector__XXX
 SG_ VCRIGHT_cabinTempBreathLevelF10m m7 : 48|8@1+ (0.5,-40) [-40|80] "degC" Vector__XXX
 SG_ VCRIGHT_cabinTempInteriorFHeatin m7 : 56|8@1+ (0.5,-40) [-40|80] "degC" Vector__XXX
 SG_ VCRIGHT_hvacCabOvrheatProtActive m8 : 5|1@1+ (1,0) [0|1] "" Vector__XXX
 SG_ VCRIGHT_hvacCabinPurgeAllowed m8 : 6|1@1+ (1,0) [0|1] "" Vector__XXX
 SG_ VCRIGHT_hvacCabOvrheatProtAllowe m8 : 7|1@1+ (1,0) [0|1] "" Vector__XXX
 SG_ VCRIGHT_filterLifeBlowerTorque m8 : 8|10@1+ (0.006,-1.5) [-1.5|4.5] "Nm" Vector__XXX
 SG_ VCRIGHT_cabinTempFanCurrent m8 : 18|6@1+ (0.001,-0.01) [-0.01|0.05] "A" Vector__XXX
 SG_ VCRIGHT_cabinTempFanOutput m8 : 24|1@1+ (1,0) [0|1] "" Vector__XXX
 SG_ VCRIGHT_cloudinessEstimatedPct m8 : 25|7@1+ (1,0) [0|100] "%" Vector__XXX
 SG_ VCRIGHT_solarLoadOnVehFiltered m8 : 32|8@1+ (4,0) [0|1020] "W/m2" Vector__XXX
 SG_ VCRIGHT_cabinTempProbeEstimate m8 : 40|8@1+ (0.5,-40) [-40|80] "degC" Vector__XXX
 SG_ VCRIGHT_cabinTempThs m8 : 48|8@1+ (0.5,-40) [-40|80] "degC" Vector__XXX
 SG_ VCRIGHT_cabinTempThsBracket m8 : 56|8@1+ (0.5,-40) [-40|80] "degC" Vector__XXX
 SG_ VCRIGHT_leftHeatOvertempProtect m9 : 5|1@1+ (1,0) [0|1] "" Vector__XXX
 SG_ VCRIGHT_rightHeatOvertempProtect m9 : 6|1@1+ (1,0) [0|1] "" Vector__XXX
 SG_ VCRIGHT_CO2ppm m9 : 7|10@1+ (5,0) [0|4000] "-" Vector__XXX
 SG_ VCRIGHT_timeLeftToCabinModelInit m9 : 17|7@1+ (1,0) [0|127] "" Vector__XXX
 SG_ VCRIGHT_hvacEstimateWindshieldRH m9 : 24|8@1+ (1,0) [0|150] "%" Vector__XXX
 SG_ VCRIGHT_hvacFoggingRiskLevel m9 : 32|7@1+ (1,0) [0|100] "%" Vector__XXX
 SG_ VCRIGHT_hvacCabinHumidityLevel m9 : 39|7@1+ (1,0) [0|100] "%" Vector__XXX
 SG_ VCRIGHT_hvacFlashFoggingDetected m9 : 47|1@1+ (1,0) [0|1] "" Vector__XXX
 SG_ VCRIGHT_solarSensitivityInfr m9 : 48|7@1+ (1,0) [0|100] "-" Vector__XXX
 SG_ VCRIGHT_solarSensitivityInfrCorr m9 : 55|7@1+ (1,0) [0|100] "-" Vector__XXX
 SG_ VCRIGHT_lumbarCurrent m10 : 5|4@1+ (0.2,0) [0|3] "A" Vector__XXX
 SG_ VCRIGHT_ocsCurrent m10 : 9|3@1+ (0.01,0) [0|0.07] "A" Vector__XXX
 SG_ VCRIGHT_rcmCurrent m10 : 12|5@1+ (0.1,0) [0|3.1] "A" Vector__XXX
 SG_ VCRIGHT_radioTunerCurrent m10 : 17|4@1+ (0.1,0) [0|1.5] "A" Vector__XXX
 SG_ VCRIGHT_rearOilPumpCurrent m10 : 21|5@1+ (0.5,0) [0|15.5] "A" Vector__XXX
 SG_ VCRIGHT_rearDefrostCurrent m10 : 26|5@1+ (2,0) [0|62] "A" Vector__XXX
 SG_ VCRIGHT_tailLightCurrent m10 : 31|4@1+ (0.1,0) [0|1.5] "A" Vector__XXX
 SG_ VCRIGHT_turnTailStopLightCurrent m10 : 35|4@1+ (0.1,0) [0|1.5] "A" Vector__XXX
 SG_ VCRIGHT_reverseFogLightsCurrent m10 : 39|4@1+ (0.1,0) [0|1.4] "A" Vector__XXX
 SG_ VCRIGHT_stopReverseTurnLightCurr m10 : 43|4@1+ (0.1,0) [0|1.5] "A" Vector__XXX
 SG_ VCRIGHT_sideMirrorCurrent m10 : 47|5@1+ (0.2,0) [0|6.2] "A" Vector__XXX
 SG_ VCRIGHT_sideMirrorHeaterCurrent m10 : 52|5@1+ (0.2,0) [0|6] "A" Vector__XXX
 SG_ VCRIGHT_frontSeatHeatCushionPwr m10 : 57|7@1+ (1,0) [0|127] "W" Vector__XXX
 SG_ VCRIGHT_trunkInteriorLEDCurrent m11 : 8|4@1+ (5,0) [0|70] "mA" Vector__XXX
 SG_ VCRIGHT_mapPocketLEDsCurrent m11 : 12|4@1+ (5,0) [0|70] "mA" Vector__XXX
 SG_ VCRIGHT_miscEFuseCurrent m11 : 16|5@1+ (0.05,0) [0|1.5] "A" Vector__XXX
 SG_ VCRIGHT_interiorHandleLEDCurrent m11 : 21|4@1+ (2,0) [0|30] "mA" Vector__XXX
 SG_ VCRIGHT_miscInteriorLightsCurren m11 : 25|3@1+ (5,0) [0|30] "mA" Vector__XXX
 SG_ VCRIGHT_frontPuddleLEDCurrent m11 : 28|3@1+ (0.05,0) [0|0.3] "A" Vector__XXX
 SG_ VCRIGHT_rearPuddleLEDCurrent m11 : 31|3@1+ (0.05,0) [0|0.3] "A" Vector__XXX
 SG_ VCRIGHT_liftgateShutfaceLEDCurre m11 : 34|3@1+ (5,0) [0|30] "mA" Vector__XXX
 SG_ VCRIGHT_3rSeatTOSCurrent m11 : 37|4@1+ (5,0) [0|70] "mA" Vector__XXX
 SG_ VCRIGHT_vbatFusedCurrent m11 : 41|4@1+ (0.1,0) [0|1.4] "A" Vector__XXX
 SG_ VCRIGHT_cabinTempGlassGridHeater m11 : 45|8@1+ (0.5,-40) [-40|80] "degC" Vector__XXX
 SG_ VCRIGHT_hvacAirflowReasonRight m11 : 53|5@1+ (1,0) [0|31] "" Vector__XXX
 SG_ VCRIGHT_hvacAirflowReasonLeft m11 : 58|5@1+ (1,0) [0|31] "" Vector__XXX
 SG_ VCRIGHT_hvacMassflowTargetLeft m12 : 5|8@1+ (1,0) [0|200] "g/s" Vector__XXX
 SG_ VCRIGHT_hvacMassflowTargetRight m12 : 13|8@1+ (1,0) [0|200] "g/s" Vector__XXX
 SG_ VCRIGHT_solarLoadLeftOccupantFil m12 : 21|7@1+ (2,0) [0|254] "W/m2" Vector__XXX
 SG_ VCRIGHT_solarLoadRightOccupantFi m12 : 28|7@1+ (2,0) [0|254] "W/m2" Vector__XXX
 SG_ VCRIGHT_windshieldRHCapped m12 : 35|8@1+ (1,0) [0|150] "%" Vector__XXX
 SG_ VCRIGHT_feedbackWarmUpScalar m12 : 43|2@1+ (16,84) [84|116] "-" Vector__XXX
 SG_ VCRIGHT_maxMassflowScalarWarmUp m12 : 45|5@1+ (1,74) [74|100] "-" Vector__XXX
 SG_ VCRIGHT_feedforwardWarmUpScalar m12 : 50|6@1+ (1,80) [80|120] "-" Vector__XXX
 SG_ VCRIGHT_frontSeatHeatBackrestPwr m12 : 56|7@1+ (1,0) [0|127] "W" Vector__XXX
 SG_ VCRIGHT_maxMassflowScalar m13 : 5|6@1+ (1,60) [60|100] "-" Vector__XXX
 SG_ VCRIGHT_massflowTargetAutoInManu m13 : 11|8@1+ (1,0) [0|250] "g/s" Vector__XXX
 SG_ VCRIGHT_airflowReasonAutoInManua m13 : 19|5@1+ (1,0) [0|31] "" Vector__XXX
 SG_ VCRIGHT_airflowReasonAutoIn_0001 m13 : 24|5@1+ (1,0) [0|31] "" Vector__XXX
 SG_ VCRIGHT_airflowReasonAutoIn_0002 m13 : 29|5@1+ (1,0) [0|31] "" Vector__XXX
 SG_ VCRIGHT_cabinTempInteriorFCoolin m13 : 34|8@1+ (0.5,-40) [-40|80] "degC" Vector__XXX
 SG_ VCRIGHT_averageDuctTempFHeating m13 : 42|8@1+ (0.5,-40) [-40|80] "degC" Vector__XXX
 SG_ VCRIGHT_averageDuctTempFCooling m13 : 50|8@1+ (0.5,-40) [-40|80] "degC" Vector__XXX
 SG_ VCRIGHT_hvacBiLevelWhsldRhEst m13 : 58|6@1+ (2,20) [20|120] "%" Vector__XXX
 SG_ VCRIGHT_steeringWheelSurfaceTemp m14 : 5|10@1+ (0.1,-35) [-35|65] "degC" Vector__XXX
 SG_ VCRIGHT_steeringWheelSurfac_0001 m14 : 16|10@1+ (0.1,-35) [-35|65] "degC" Vector__XXX
 SG_ VCRIGHT_timeToComfortHeating m14 : 26|6@1+ (15,-15) [-15|930] "s" Vector__XXX
 SG_ VCRIGHT_timeToComfortCooling m14 : 32|6@1+ (15,-15) [-15|930] "s" Vector__XXX
 SG_ VCRIGHT_cabinWaterMassRaw m14 : 40|8@1+ (0.1,0) [0|25] "g/kg" Vector__XXX
 SG_ VCRIGHT_massflowSingleZoneSplit m14 : 48|7@1+ (1,0) [0|100] "-" Vector__XXX
 SG_ VCRIGHT_VOCPurgeState m14 : 56|3@1+ (1,0) [0|7] "" Vector__XXX
 SG_ VCRIGHT_cameraFoggingMonitorStat m14 : 59|3@1+ (1,0) [0|7] "" Vector__XXX
 SG_ VCRIGHT_cabinOverheatProtectNotR m15 : 5|14@1+ (1,0) [0|16383] "" Vector__XXX
 SG_ VCRIGHT_hvacIntakeReason m15 : 19|5@1+ (1,0) [0|31] "" Vector__XXX
 SG_ VCRIGHT_hvacCabinPurgeActive m15 : 24|1@1+ (1,0) [0|1] "" Vector__XXX
 SG_ VCRIGHT_solarAzimuthCarRef m15 : 25|11@1- (0.5,0) [-511|511.5] "deg" Vector__XXX
 SG_ VCRIGHT_massflowPulldownBias m15 : 36|4@1+ (7,0) [0|100] "%" Vector__XXX
 SG_ VCRIGHT_evapPulldownBias m15 : 40|4@1+ (7,0) [0|100] "%" Vector__XXX
 SG_ VCRIGHT_modeledMassflowFresh m15 : 44|8@1+ (1,0) [0|255] "g/s" Vector__XXX
 SG_ VCRIGHT_modeledMassflowRecirc m15 : 52|8@1+ (1,0) [0|255] "g/s" Vector__XXX
 SG_ VCRIGHT_hvacLimpModeStatus m15 : 60|3@1+ (1,0) [0|7] "" Vector__XXX
 SG_ VCRIGHT_hvacEstimatedCameraWinds m16 : 8|8@1+ (1,0) [0|150] "%" Vector__XXX

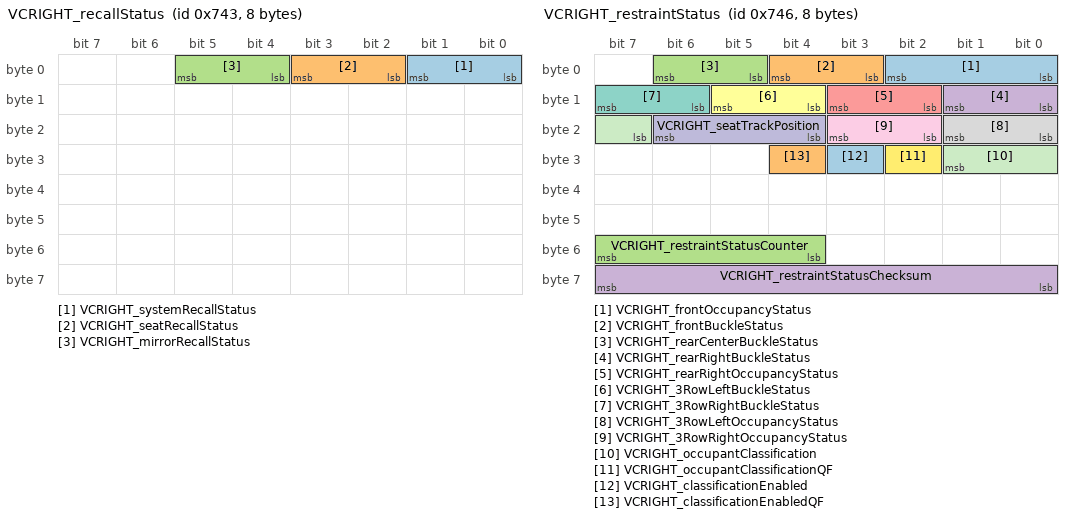
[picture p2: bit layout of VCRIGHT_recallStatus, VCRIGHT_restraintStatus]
BO_ 1859 VCRIGHT_recallStatus: 8 VCRIGHT
 SG_ VCRIGHT_systemRecallStatus : 0|2@1+ (1,0) [0|3] "" Vector__XXX
 SG_ VCRIGHT_seatRecallStatus : 2|2@1+ (1,0) [0|3] "" Vector__XXX
 SG_ VCRIGHT_mirrorRecallStatus : 4|2@1+ (1,0) [0|3] "" Vector__XXX

BO_ 1862 VCRIGHT_restraintStatus: 8 VCRIGHT
 SG_ VCRIGHT_frontOccupancyStatus : 0|3@1+ (1,0) [0|7] "" Vector__XXX
 SG_ VCRIGHT_frontBuckleStatus : 3|2@1+ (1,0) [0|3] "" Vector__XXX
 SG_ VCRIGHT_rearCenterBuckleStatus : 5|2@1+ (1,0) [0|3] "" Vector__XXX
 SG_ VCRIGHT_rearRightBuckleStatus : 8|2@1+ (1,0) [0|3] "" Vector__XXX
 SG_ VCRIGHT_rearRightOccupancyStatus : 10|2@1+ (1,0) [0|3] "" Vector__XXX
 SG_ VCRIGHT_3RowLeftBuckleStatus : 12|2@1+ (1,0) [0|3] "" Vector__XXX
 SG_ VCRIGHT_3RowRightBuckleStatus : 14|2@1+ (1,0) [0|3] "" Vector__XXX
 SG_ VCRIGHT_3RowLeftOccupancyStatus : 16|2@1+ (1,0) [0|3] "" Vector__XXX
 SG_ VCRIGHT_3RowRightOccupancyStatus : 18|2@1+ (1,0) [0|3] "" Vector__XXX
 SG_ VCRIGHT_seatTrackPosition : 20|3@1+ (1,0) [0|7] "" Vector__XXX
 SG_ VCRIGHT_occupantClassification : 23|3@1+ (1,0) [0|7] "" Vector__XXX
 SG_ VCRIGHT_occupantClassificationQF : 26|1@1+ (1,0) [0|1] "" Vector__XXX
 SG_ VCRIGHT_classificationEnabled : 27|1@1+ (1,0) [0|1] "" Vector__XXX
 SG_ VCRIGHT_classificationEnabledQF : 28|1@1+ (1,0) [0|1] "" Vector__XXX
 SG_ VCRIGHT_restraintStatusCounter : 52|4@1+ (1,0) [0|15] "" Vector__XXX
 SG_ VCRIGHT_restraintStatusChecksum : 56|8@1+ (1,0) [0|255] "" Vector__XXX

BO_ 1251 VCRIGHT_seatStatus: 8 VCRIGHT
 SG_ VCRIGHT_seatStatusIndex M : 0|3@1+ (1,0) [0|7] "" Vector__XXX
 SG_ VCRIGHT_frontSeatTrackPos m0 : 8|16@1- (1,0) [-32768|32767] "" Vector__XXX
 SG_ VCRIGHT_frontSeatTrackCurrent m0 : 24|12@1- (0.01,0) [-20.48|20.47] "A" Vector__XXX
 SG_ VCRIGHT_frontSeatTrackDuty m0 : 36|12@1- (0.1,0) [-204.8|204.7] "%" Vector__XXX
 SG_ VCRIGHT_frontSeatTrackState m0 : 48|3@1+ (1,0) [0|7] "" Vector__XXX
 SG_ VCRIGHT_frontSeatTrackCalibrated m0 : 51|1@1+ (1,0) [0|1] "" Vector__XXX
 SG_ VCRIGHT_frontSeatTrackLog m0 : 52|1@1+ (1,0) [0|1] "" Vector__XXX
 SG_ VCRIGHT_frontSeatTrackBridgeSt m0 : 53|2@1+ (1,0) [0|3] "" Vector__XXX
 SG_ VCRIGHT_frontSeatBackPos m1 : 8|16@1- (1,0) [-32768|32767] "" Vector__XXX
 SG_ VCRIGHT_frontSeatBackCurrent m1 : 24|12@1- (0.01,0) [-20.48|20.47] "A" Vector__XXX
 SG_ VCRIGHT_frontSeatBackDuty m1 : 36|12@1- (0.1,0) [-204.8|204.7] "%" Vector__XXX
 SG_ VCRIGHT_frontSeatBackState m1 : 48|3@1+ (1,0) [0|7] "" Vector__XXX
 SG_ VCRIGHT_frontSeatBackCalibrated m1 : 51|1@1+ (1,0) [0|1] "" Vector__XXX
 SG_ VCRIGHT_frontSeatBackLog m1 : 52|1@1+ (1,0) [0|1] "" Vector__XXX
 SG_ VCRIGHT_frontSeatBackBridgeSt m1 : 53|2@1+ (1,0) [0|3] "" Vector__XXX
 SG_ VCRIGHT_frontSeatLiftPos m2 : 8|16@1- (1,0) [-32768|32767] "" Vector__XXX
 SG_ VCRIGHT_frontSeatLiftCurrent m2 : 24|12@1- (0.01,0) [-20.48|20.47] "A" Vector__XXX
 SG_ VCRIGHT_frontSeatLiftDuty m2 : 36|12@1- (0.1,0) [-204.8|204.7] "%" Vector__XXX
 SG_ VCRIGHT_frontSeatLiftState m2 : 48|3@1+ (1,0) [0|7] "" Vector__XXX
 SG_ VCRIGHT_frontSeatLiftCalibrated m2 : 51|1@1+ (1,0) [0|1] "" Vector__XXX
 SG_ VCRIGHT_frontSeatLiftLog m2 : 52|1@1+ (1,0) [0|1] "" Vector__XXX
 SG_ VCRIGHT_frontSeatLiftBridgeSt m2 : 53|2@1+ (1,0) [0|3] "" Vector__XXX
 SG_ VCRIGHT_frontSeatTiltPos m3 : 8|16@1- (1,0) [-32768|32767] "" Vector__XXX
 SG_ VCRIGHT_frontSeatTiltCurrent m3 : 24|12@1- (0.01,0) [-20.48|20.47] "A" Vector__XXX
 SG_ VCRIGHT_frontSeatTiltDuty m3 : 36|12@1- (0.1,0) [-204.8|204.7] "%" Vector__XXX
 SG_ VCRIGHT_frontSeatTiltState m3 : 48|3@1+ (1,0) [0|7] "" Vector__XXX
 SG_ VCRIGHT_frontSeatTiltCalibrated m3 : 51|1@1+ (1,0) [0|1] "" Vector__XXX
 SG_ VCRIGHT_frontSeatTiltLog m3 : 52|1@1+ (1,0) [0|1] "" Vector__XXX
 SG_ VCRIGHT_frontSeatTiltBridgeSt m3 : 53|2@1+ (1,0) [0|3] "" Vector__XXX
 SG_ VCRIGHT_lumbarAState m4 : 3|3@1+ (1,0) [0|7] "" Vector__XXX
 SG_ VCRIGHT_lumbarBState m4 : 6|3@1+ (1,0) [0|7] "" Vector__XXX
 SG_ VCRIGHT_lumbarAPressureHpa m4 : 9|12@1+ (1,0) [0|4095] "" Vector__XXX
 SG_ VCRIGHT_lumbarAPressureHpaFilt m4 : 21|10@1+ (1,0) [0|1023] "" Vector__XXX
 SG_ VCRIGHT_lumbarBPressureHpa m4 : 31|12@1+ (1,0) [0|4095] "" Vector__XXX
 SG_ VCRIGHT_lumbarBPressureHpaFilt m4 : 43|10@1+ (1,0) [0|1023] "" Vector__XXX
 SG_ VCRIGHT_lumbarActiveTooLongErr m4 : 53|1@1+ (1,0) [0|1] "" Vector__XXX
 SG_ VCRIGHT_lumbarMaxPErr m4 : 54|1@1+ (1,0) [0|1] "" Vector__XXX
 SG_ VCRIGHT_lumbarOvercurrentErr m4 : 55|1@1+ (1,0) [0|1] "" Vector__XXX
 SG_ VCRIGHT_lumbarMaxOperatingPErr m4 : 56|1@1+ (1,0) [0|1] "" Vector__XXX
 SG_ VCRIGHT_lumbarMinPErr m4 : 57|1@1+ (1,0) [0|1] "" Vector__XXX
 SG_ VCRIGHT_lumbarGeneralErr m4 : 58|1@1+ (1,0) [0|1] "" Vector__XXX
 SG_ VCRIGHT_lumbarDevMaxPumpPressA m4 : 59|1@1+ (1,0) [0|1] "" Vector__XXX
 SG_ VCRIGHT_lumbarDevMaxPumpPressB m4 : 60|1@1+ (1,0) [0|1] "" Vector__XXX
 SG_ VCRIGHT_frontSeatTrackPosReal m5 : 3|12@1- (1,0) [-2048|2047] "mm" Vector__XXX
 SG_ VCRIGHT_frontSeatBackPosReal m5 : 16|12@1- (0.1,0) [-204.8|204.7] "deg" Vector__XXX
 SG_ VCRIGHT_frontSeatLiftPosReal m5 : 28|12@1- (1,0) [-2048|2047] "mm" Vector__XXX
 SG_ VCRIGHT_frontSeatTiltPosReal m5 : 40|12@1- (0.1,0) [-204.8|204.7] "deg" Vector__XXX
 SG_ VCRIGHT_frontSeatTrackPosOffset m6 : 3|12@1- (1,0) [-2048|2047] "mm" Vector__XXX
 SG_ VCRIGHT_frontSeatBackPosOffset m6 : 16|12@1- (0.1,0) [-204.8|204.7] "deg" Vector__XXX
 SG_ VCRIGHT_frontSeatLiftPosOffset m6 : 28|12@1- (1,0) [-2048|2047] "mm" Vector__XXX
 SG_ VCRIGHT_frontSeatTiltPosOffset m6 : 40|12@1- (0.1,0) [-204.8|204.7] "deg" Vector__XXX

BO_ 739 VCRIGHT_seatStatus2: 8 VCRIGHT
 SG_ VCRIGHT_seatStatus2Index M : 0|4@1+ (1,0) [0|15] "" Vector__XXX
 SG_ VCRIGHT_frontSeatHeatCurrent m0 : 4|12@1+ (0.01,0) [0|40.95] "A" Vector__XXX
 SG_ VCRIGHT_frontSeatHeatDuty m0 : 16|8@1+ (1,0) [0|255] "%" Vector__XXX
 SG_ VCRIGHT_frontSeatHeatTmp m0 : 24|12@1- (0.05,0) [-40|80] "degC" Vector__XXX
 SG_ VCRIGHT_frontSeatHeatTmpTarget m0 : 36|8@1- (0.5,0) [0|60] "degC" Vector__XXX
 SG_ VCRIGHT_frontSeatHeatInhibited m0 : 44|1@1+ (1,0) [0|1] "" Vector__XXX
 SG_ VCRIGHT_frontSeatHeatPowered m0 : 45|1@1+ (1,0) [0|1] "" Vector__XXX
 SG_ VCRIGHT_rearLSeatHeatCurrent m1 : 4|12@1+ (0.01,0) [0|40.95] "A" Vector__XXX
 SG_ VCRIGHT_rearLSeatHeatDuty m1 : 16|8@1+ (1,0) [0|255] "%" Vector__XXX
 SG_ VCRIGHT_rearLSeatHeatTmp m1 : 24|12@1- (0.05,0) [-40|80] "degC" Vector__XXX
 SG_ VCRIGHT_rearLSeatHeatTmpTarget m1 : 36|8@1- (0.5,0) [0|60] "degC" Vector__XXX
 SG_ VCRIGHT_rearLSeatHeatInhibited m1 : 44|1@1+ (1,0) [0|1] "" Vector__XXX
 SG_ VCRIGHT_rearLSeatHeatPowered m1 : 45|1@1+ (1,0) [0|1] "" Vector__XXX
 SG_ VCRIGHT_rearCSeatHeatCurrent m2 : 4|12@1+ (0.01,0) [0|40.95] "A" Vector__XXX
 SG_ VCRIGHT_rearCSeatHeatDuty m2 : 16|8@1+ (1,0) [0|255] "%" Vector__XXX
 SG_ VCRIGHT_rearCSeatHeatTmp m2 : 24|12@1- (0.05,0) [-40|80] "degC" Vector__XXX
 SG_ VCRIGHT_rearCSeatHeatTmpTarget m2 : 36|8@1- (0.5,0) [0|60] "degC" Vector__XXX
 SG_ VCRIGHT_rearCSeatHeatInhibited m2 : 44|1@1+ (1,0) [0|1] "" Vector__XXX
 SG_ VCRIGHT_rearCSeatHeatPowered m2 : 45|1@1+ (1,0) [0|1] "" Vector__XXX
 SG_ VCRIGHT_rearRSeatHeatCurrent m3 : 4|12@1+ (0.01,0) [0|40.95] "A" Vector__XXX
 SG_ VCRIGHT_rearRSeatHeatDuty m3 : 16|8@1+ (1,0) [0|255] "%" Vector__XXX
 SG_ VCRIGHT_rearRSeatHeatTmp m3 : 24|12@1- (0.05,0) [-40|80] "degC" Vector__XXX
 SG_ VCRIGHT_rearRSeatHeatTmpTarget m3 : 36|8@1- (0.5,0) [0|60] "degC" Vector__XXX
 SG_ VCRIGHT_rearRSeatHeatInhibited m3 : 44|1@1+ (1,0) [0|1] "" Vector__XXX
 SG_ VCRIGHT_rearRSeatHeatPowered m3 : 45|1@1+ (1,0) [0|1] "" Vector__XXX
 SG_ VCRIGHT_2RowSeatReclineState m11 : 4|4@1+ (1,0) [0|15] "" Vector__XXX
 SG_ VCRIGHT_2RowSeatReclineDuty m11 : 8|8@1- (1,0) [-100|100] "%" Vector__XXX
 SG_ VCRIGHT_2RowSeatReclineCurrent m11 : 16|12@1- (0.05,0) [-100|100] "A" Vector__XXX
 SG_ VCRIGHT_2RowSeatReclineCalibrate m11 : 28|1@1+ (1,0) [0|1] "" Vector__XXX
 SG_ VCRIGHT_2RowSeatReclinePositionR m11 : 29|12@1- (1,0) [-2048|2047] "" Vector__XXX
 SG_ VCRIGHT_2RowSeatReclineAngle m11 : 41|12@1- (0.1,0) [-204.8|204.7] "deg" Vector__XXX
 SG_ VCRIGHT_2RowSeatReclineAbsPosSwi m11 : 53|2@1+ (1,0) [0|3] "" Vector__XXX
 SG_ VCRIGHT_2RowSeatReclinePositionS m12 : 4|3@1+ (1,0) [0|7] "" Vector__XXX
 SG_ VCRIGHT_2RowSeatReclineAdjustmen m12 : 7|1@1+ (1,0) [0|1] "" Vector__XXX
 SG_ VCRIGHT_2RowSeatReclineFoldAllow m12 : 8|1@1+ (1,0) [0|1] "" Vector__XXX
 SG_ VCRIGHT_2RowSeatReclineUnfoldAll m12 : 9|1@1+ (1,0) [0|1] "" Vector__XXX
 SG_ VCRIGHT_2RowSeatReclineNextToggl m12 : 10|2@1+ (1,0) [0|3] "" Vector__XXX
 SG_ VCRIGHT_2RowSeatReclineChoreoBlo m12 : 12|1@1+ (1,0) [0|1] "" Vector__XXX
 SG_ VCRIGHT_2RowSeat1RClashAvoidance m12 : 13|3@1+ (1,0) [0|7] "" Vector__XXX
 SG_ VCRIGHT_2RowSeat1RClashAvoi_0001 m12 : 16|2@1+ (1,0) [0|3] "" Vector__XXX
 SG_ VCRIGHT_2RowSeatReclineAbsP_0001 m12 : 18|12@1- (0.1,0) [-204.8|204.7] "deg" Vector__XXX

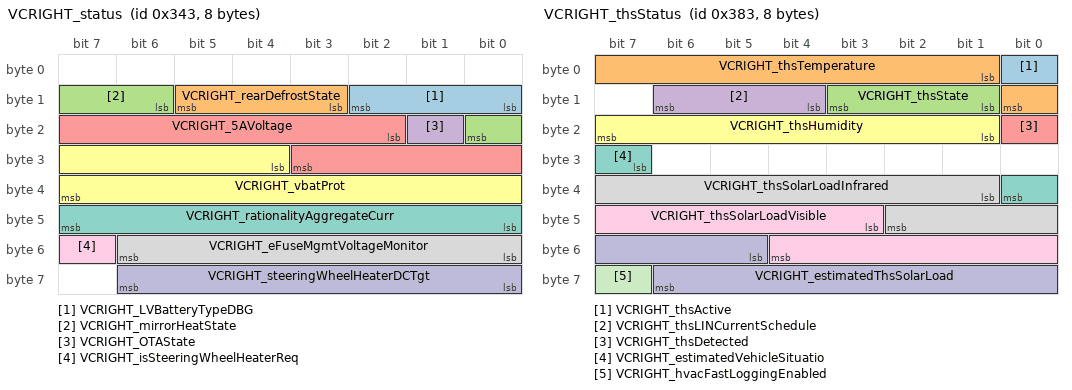
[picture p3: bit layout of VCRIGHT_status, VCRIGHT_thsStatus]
BO_ 835 VCRIGHT_status: 8 VCRIGHT
 SG_ VCRIGHT_LVBatteryTypeDBG : 8|3@1+ (1,0) [0|7] "" Vector__XXX
 SG_ VCRIGHT_rearDefrostState : 11|3@1+ (1,0) [0|7] "" Vector__XXX
 SG_ VCRIGHT_mirrorHeatState : 14|3@1+ (1,0) [0|7] "" Vector__XXX
 SG_ VCRIGHT_OTAState : 17|1@1+ (1,0) [0|1] "" Vector__XXX
 SG_ VCRIGHT_5AVoltage : 18|10@1+ (0.005443676,0) [0|5.568880548] "V" Vector__XXX
 SG_ VCRIGHT_vbatProt : 28|12@1+ (0.005443676,0) [0|22.29185322] "V" Vector__XXX
 SG_ VCRIGHT_rationalityAggregateCurr : 40|8@1+ (0.5,0) [0|127.5] "A" Vector__XXX
 SG_ VCRIGHT_eFuseMgmtVoltageMonitor : 48|7@1+ (0.125,0) [0|15.875] "V" Vector__XXX
 SG_ VCRIGHT_isSteeringWheelHeaterReq : 55|1@1+ (1,0) [0|1] "" Vector__XXX
 SG_ VCRIGHT_steeringWheelHeaterDCTgt : 56|7@1+ (0.01,0) [0|1] "-" Vector__XXX

BO_ 963 VCRIGHT_switchStatus: 8 VCRIGHT
 SG_ VCRIGHT_switchStatusIndex M : 0|1@1+ (1,0) [0|1] "" Vector__XXX
 SG_ VCRIGHT_trunkExtReleasePressedPe m1 : 1|1@1+ (1,0) [0|1] "" Vector__XXX
 SG_ VCRIGHT_frontSeatTrackBack m1 : 2|2@1+ (1,0) [0|3] "" Vector__XXX
 SG_ VCRIGHT_frontSeatTrackForward m1 : 4|2@1+ (1,0) [0|3] "" Vector__XXX
 SG_ VCRIGHT_frontSeatTiltDown m1 : 6|2@1+ (1,0) [0|3] "" Vector__XXX
 SG_ VCRIGHT_frontSeatTiltUp m1 : 8|2@1+ (1,0) [0|3] "" Vector__XXX
 SG_ VCRIGHT_frontSeatLiftDown m1 : 10|2@1+ (1,0) [0|3] "" Vector__XXX
 SG_ VCRIGHT_frontSeatLiftUp m1 : 12|2@1+ (1,0) [0|3] "" Vector__XXX
 SG_ VCRIGHT_frontSeatBackrestBack m1 : 14|2@1+ (1,0) [0|3] "" Vector__XXX
 SG_ VCRIGHT_frontSeatBackrestForward m1 : 16|2@1+ (1,0) [0|3] "" Vector__XXX
 SG_ VCRIGHT_frontSeatLumbarDown m1 : 18|2@1+ (1,0) [0|3] "" Vector__XXX
 SG_ VCRIGHT_frontSeatLumbarUp m1 : 20|2@1+ (1,0) [0|3] "" Vector__XXX
 SG_ VCRIGHT_frontSeatLumbarIn m1 : 22|2@1+ (1,0) [0|3] "" Vector__XXX
 SG_ VCRIGHT_frontSeatLumbarOut m1 : 24|2@1+ (1,0) [0|3] "" Vector__XXX
 SG_ VCRIGHT_2RowSeatReclineSwitch m1 : 26|1@1+ (1,0) [0|1] "" Vector__XXX
 SG_ VCRIGHT_2RowSeatBackrestFoldSwit m1 : 27|1@1+ (1,0) [0|1] "" Vector__XXX
 SG_ VCRIGHT_frontHandlePWM m1 : 32|7@1+ (1,0) [0|100] "%" Vector__XXX
 SG_ VCRIGHT_rearHandlePWM m1 : 40|7@1+ (1,0) [0|100] "%" Vector__XXX
 SG_ VCRIGHT_gloveboxLightCurrent m1 : 47|5@1+ (2,0) [0|62] "mA" Vector__XXX
 SG_ VCRIGHT_frontSeatALR m1 : 52|2@1+ (1,0) [0|3] "" Vector__XXX
 SG_ VCRIGHT_frontSeatResistiveOccupa m1 : 54|2@1+ (1,0) [0|3] "" Vector__XXX
 SG_ VCRIGHT_2RowSeatReclineSwitchpac m1 : 56|3@1+ (1,0) [0|7] "" Vector__XXX

BO_ 899 VCRIGHT_thsStatus: 8 VCRIGHT
 SG_ VCRIGHT_thsActive : 0|1@1+ (1,0) [0|1] "" Vector__XXX
 SG_ VCRIGHT_thsTemperature : 1|8@1+ (1,-40) [-40|150] "degC" Vector__XXX
 SG_ VCRIGHT_thsState : 9|3@1+ (1,0) [0|7] "" Vector__XXX
 SG_ VCRIGHT_thsLINCurrentSchedule : 12|3@1+ (1,0) [0|7] "" Vector__XXX
 SG_ VCRIGHT_thsDetected : 16|1@1+ (1,0) [0|1] "" Vector__XXX
 SG_ VCRIGHT_thsHumidity : 17|7@1+ (1,0) [0|100] "%" Vector__XXX
 SG_ VCRIGHT_estimatedVehicleSituatio : 31|2@1+ (1,0) [0|3] "" Vector__XXX
 SG_ VCRIGHT_thsSolarLoadInfrared : 33|10@1+ (2,0) [0|2044] "W/m2" Vector__XXX
 SG_ VCRIGHT_thsSolarLoadVisible : 43|10@1+ (2,0) [0|2044] "W/m2" Vector__XXX
 SG_ VCRIGHT_estimatedThsSolarLoad : 53|10@1+ (1,0) [0|1022] "W/m2" Vector__XXX
 SG_ VCRIGHT_hvacFastLoggingEnabled : 63|1@1+ (1,0) [0|1] "" Vector__XXX

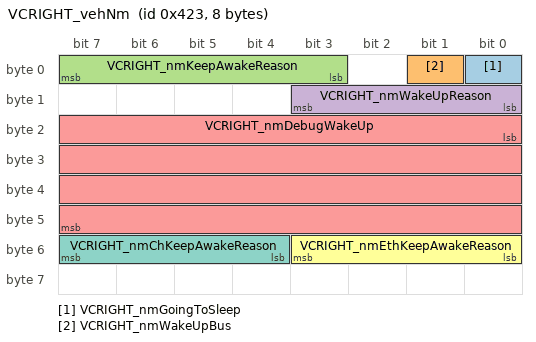
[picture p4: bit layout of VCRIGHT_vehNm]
BO_ 1059 VCRIGHT_vehNm: 8 VCRIGHT
 SG_ VCRIGHT_nmGoingToSleep : 0|1@1+ (1,0) [0|1] "" Vector__XXX
 SG_ VCRIGHT_nmWakeUpBus : 1|1@1+ (1,0) [0|1] "" Vector__XXX
 SG_ VCRIGHT_nmKeepAwakeReason : 3|5@1+ (1,0) [0|31] "" Vector__XXX
 SG_ VCRIGHT_nmWakeUpReason : 8|4@1+ (1,0) [0|15] "" Vector__XXX
 SG_ VCRIGHT_nmDebugWakeUp : 16|32@1+ (1,0) [0|4294967295] "" Vector__XXX
 SG_ VCRIGHT_nmEthKeepAwakeReason : 48|4@1+ (1,0) [0|15] "" Vector__XXX
 SG_ VCRIGHT_nmChKeepAwakeReason : 52|4@1+ (1,0) [0|15] "" Vector__XXX

BO_ 707 VCRIGHT_windowStatus: 8 VCRIGHT
 SG_ VCRIGHT_windowStatusIndex M : 0|1@1+ (1,0) [0|1] "" Vector__XXX
 SG_ VCRIGHT_windowStateRF m0 : 1|4@1+ (1,0) [0|15] "" Vector__XXX
 SG_ VCRIGHT_windowTrimClearMoveReque m0 : 5|2@1+ (1,0) [0|3] "" Vector__XXX
 SG_ VCRIGHT_windowDutyRF m0 : 8|6@1- (5,0) [-100|100] "%" Vector__XXX
 SG_ VCRIGHT_windowTrimClearActiveReq m0 : 14|2@1+ (1,0) [0|3] "" Vector__XXX
 SG_ VCRIGHT_windowCurrentRF m0 : 16|6@1- (0.5,0) [-15|15] "A" Vector__XXX
 SG_ VCRIGHT_windowPositionRF m0 : 22|9@1- (1.25,265) [-50|580] "mm" Vector__XXX
 SG_ VCRIGHT_windowCalibratedRF m0 : 32|1@1+ (1,0) [0|1] "" Vector__XXX
 SG_ VCRIGHT_windowStateRR m0 : 33|4@1+ (1,0) [0|15] "" Vector__XXX
 SG_ VCRIGHT_windowDutyRR m0 : 40|6@1- (5,0) [-100|100] "%" Vector__XXX
 SG_ VCRIGHT_windowCurrentRR m0 : 48|6@1- (0.5,0) [-15|15] "A" Vector__XXX
 SG_ VCRIGHT_windowPositionRR m0 : 54|9@1- (1.25,265) [-50|580] "mm" Vector__XXX
 SG_ VCRIGHT_windowCalibratedRR m0 : 63|1@1+ (1,0) [0|1] "" Vector__XXX
 SG_ VCRIGHT_windowThermalTCRF m1 : 1|8@1+ (1,0) [0|255] "s" Vector__XXX
 SG_ VCRIGHT_windowThermalModeRF m1 : 9|2@1+ (1,0) [0|3] "" Vector__XXX
 SG_ VCRIGHT_windowStopReasonRF m1 : 11|3@1+ (1,0) [0|7] "" Vector__XXX
 SG_ VCRIGHT_windowStopReqReasonRF m1 : 14|4@1+ (1,0) [0|15] "" Vector__XXX
 SG_ VCRIGHT_windowThermalTCRR m1 : 18|8@1+ (1,0) [0|255] "s" Vector__XXX
 SG_ VCRIGHT_windowThermalModeRR m1 : 26|2@1+ (1,0) [0|3] "" Vector__XXX
 SG_ VCRIGHT_windowStopReasonRR m1 : 28|3@1+ (1,0) [0|7] "" Vector__XXX
 SG_ VCRIGHT_windowStopReqReasonRR m1 : 31|4@1+ (1,0) [0|15] "" Vector__XXX
 SG_ VCRIGHT_windowControlStateRF m1 : 35|2@1+ (1,0) [0|3] "" Vector__XXX
 SG_ VCRIGHT_windowCtrlUnavailableRF m1 : 38|3@1+ (1,0) [0|7] "" Vector__XXX
 SG_ VCRIGHT_windowControlStateRR m1 : 42|2@1+ (1,0) [0|3] "" Vector__XXX
 SG_ VCRIGHT_windowCtrlUnavailableRR m1 : 45|3@1+ (1,0) [0|7] "" Vector__XXX
 SG_ VCRIGHT_windowPositionStateRF m1 : 49|3@1+ (1,0) [0|7] "" Vector__XXX
 SG_ VCRIGHT_windowPositionStateRR m1 : 52|3@1+ (1,0) [0|7] "" Vector__XXX
 SG_ VCRIGHT_windowVehGearStateRF m1 : 56|2@1+ (1,0) [0|3] "" Vector__XXX
 SG_ VCRIGHT_windowVehGearStateRR m1 : 58|2@1+ (1,0) [0|3] "" Vector__XXX
 SG_ VCRIGHT_windowSpeedTableStatusRF m1 : 60|2@1+ (1,0) [0|3] "" Vector__XXX
 SG_ VCRIGHT_windowSpeedTableStatusRR m1 : 62|2@1+ (1,0) [0|3] "" Vector__XXX

CM_ BO_ 259 "Right body controller message: door status";
CM_ SG_ 259 VCRIGHT_doorClosureStatusFront "Status of the door from a closures perspective";
CM_ SG_ 259 VCRIGHT_doorClosureStatusRear "Status of the door from a closures perspective";
CM_ SG_ 259 VCRIGHT_frontLatchSwitch "State of front left door latch switch representing door open/closed. 0 is open and 1 is closed";
CM_ SG_ 259 VCRIGHT_rearLatchSwitch "State of rear right door latch switch representing door open/closed. 0 is open and 1 is closed";
CM_ SG_ 259 VCRIGHT_frontHandlePulled "Right body controller: front handle pulled";
CM_ SG_ 259 VCRIGHT_rearHandlePulled "Right body controller: rear handle pulled";
CM_ SG_ 259 VCRIGHT_frontRelActuatorSwitch "State of front left door latch switch representing latch arm/unarmed. Disarms while door handle is pulled.";
CM_ SG_ 259 VCRIGHT_rearRelActuatorSwitch "State of rear right door latch switch representing latch arm/unarmed. Disarms while door handle is pulled";
CM_ SG_ 259 VCRIGHT_frontLatchStatus "Status of right front door latch";
CM_ SG_ 259 VCRIGHT_rearLatchStatus "Status of rear right door latch";
CM_ SG_ 259 VCRIGHT_lastDoorReqSourceFront "last source of front door open request";
CM_ SG_ 259 VCRIGHT_lastDoorReqSourceRear "last source of rear door open request";
CM_ SG_ 259 VCRIGHT_reservedForBackCompat "Right body controller: reserved for back compat";
CM_ SG_ 259 VCRIGHT_frontHandlePulledPersist "Right body controller: front handle pulled persist";
CM_ SG_ 259 VCRIGHT_frontIntSwitchPressed "Right body controller: front int switch pressed";
CM_ SG_ 259 VCRIGHT_rearIntSwitchPressed "Right body controller: rear int switch pressed";
CM_ SG_ 259 VCRIGHT_mirrorTiltXPosition "Value representing right side view mirror tilt horizontal position";
CM_ SG_ 259 VCRIGHT_mirrorTiltYPosition "Value representing right side view mirror tilt vertical position";
CM_ SG_ 259 VCRIGHT_mirrorState "State of the right side view mirror.";
CM_ SG_ 259 VCRIGHT_mirrorFoldState "Fold state for the right side view mirror";
CM_ SG_ 259 VCRIGHT_mirrorDipped "Reports if the side view mirrors in are in the dipped position.";
CM_ SG_ 259 VCRIGHT_trunkLatchStatus "State of the trunk latch";
CM_ SG_ 259 VCRIGHT_mirrorRecallState "State of Mirror Recall.";
CM_ SG_ 259 VCRIGHT_rearHandlePulledPersist "Right body controller: rear handle pulled persist";
CM_ BO_ 2010 "Right body controller message: door status2";
CM_ SG_ 2010 VCRIGHT_doorStatus2Index "Right body controller: door status2 index";
CM_ SG_ 2010 VCRIGHT_frontLatchRelDuty "Front left door latch motor duty cycle.";
CM_ SG_ 2010 VCRIGHT_BPillarCameraHeaterState "Indicates the state of the right b-pillar camera heater";
CM_ SG_ 2010 VCRIGHT_doorLatchAjarSwitchVolta "Door latch switch voltage feeding switch logic";
CM_ SG_ 2010 VCRIGHT_doorLatchAjarSwitch_0001 "Door latch switch voltage feeding switch logic";
CM_ SG_ 2010 VCRIGHT_BPillarCameraHeaterCurre "Current drawn by the right b-pillar camera heater";
CM_ SG_ 2010 VCRIGHT_mirrorTiltXOffset "Communicates post calibration position offset of right side view mirror tilt horizontal position";
CM_ SG_ 2010 VCRIGHT_mirrorTiltYOffset "Communicates post calibration position offset of right side view mirror tilt vertical position";
CM_ BO_ 915 "Right body controller message: epbm debug";
CM_ SG_ 915 VCRIGHT_epbmDebugIndex "Right body controller: epbm debug index";
CM_ SG_ 915 VCRIGHT_epbmCaliperState "Right body controller: epbm caliper state";
CM_ SG_ 915 VCRIGHT_epbmMotorEnabled "Right body controller: epbm motor enabled";
CM_ SG_ 915 VCRIGHT_epbMotorCurrent "Right body controller: epb motor current";
CM_ SG_ 915 VCRIGHT_epbmApplyVoltage "Right body controller: epbm apply voltage";
CM_ SG_ 915 VCRIGHT_epbmReleaseVoltage "Right body controller: epbm release voltage";
CM_ SG_ 915 VCRIGHT_summonFaultReason "Electronic Parking Brake Monitors error code associated with previous summon failure.";
CM_ SG_ 915 VCRIGHT_epbSummonState "Electronic Parking Brake Monitors reading of Electronic Parking Brake's summon state.";
CM_ SG_ 915 VCRIGHT_epbmSummonState "Electronic Parking Brake Monitors summon state.";
CM_ SG_ 915 VCRIGHT_epbUnitStatus "Electronic Parking Brake Monitors reading of Electronic Parking Brake's state.";
CM_ SG_ 915 VCRIGHT_epbmFaultStatus "Electronic Parking Brake Monitors fault state.";
CM_ SG_ 915 VCRIGHT_epbFaultStatus "Electronic Parking Brake Monitors reading of Electronic Parking Brake's fault state.";
CM_ SG_ 915 VCRIGHT_epbmSystemStatus "Electronic Parking Brake Monitors reading of Electronic Parking Brake's state.";
CM_ BO_ 1123 "Right body controller message: epbm status";
CM_ SG_ 1123 VCRIGHT_cdpRequestState "If the Electronic Parking Brake makes a Controlled Deceleration for Parking Brake request, when cdpOkayToRequest is EPB_CDP_REQUEST_INVALID, cdpRequestState shall transition to EPB_CDP_REQUEST_INVALID, untill the Electronic Parking Brake Monitor enters unitStatus PARKED. Stability Control listens to this signal to qualify Controlled Deceleration for Parking Brake requests from the Electronic Parking Brake.";
CM_ SG_ 1123 VCRIGHT_epbmSystemStatusQF "Right body controller: epbm system status QF";
CM_ SG_ 1123 VCRIGHT_epbmUnitStatus "Electronic Parking Brake Monitors state.";
CM_ SG_ 1123 VCRIGHT_epbmCdpState "Right body controller: epbm cdp state";
CM_ SG_ 1123 VCRIGHT_epbmStatusCounter "Right body controller: epbm status counter";
CM_ SG_ 1123 VCRIGHT_epbmStatusChecksum "Right body controller: epbm status checksum";
CM_ BO_ 524 "Right body controller message: hvac request";
CM_ SG_ 524 VCRIGHT_wattsDemandEvap "Right body controller: watts demand evap";
CM_ SG_ 524 VCRIGHT_hvacEvapEnabled "Right body controller: hvac evap enabled";
CM_ SG_ 524 VCRIGHT_conditioningRequest "Right body controller: conditioning request";
CM_ SG_ 524 VCRIGHT_tempEvaporator "Evaporator temperature";
CM_ SG_ 524 VCRIGHT_tempEvaporatorTarget "Evaporator temperature target";
CM_ SG_ 524 VCRIGHT_hvacBlowerSpeedRPMReq "Right body controller: hvac blower speed RPM req";
CM_ SG_ 524 VCRIGHT_hvacPerfTestRunning "Right body controller: hvac perf test running";
CM_ SG_ 524 VCRIGHT_evapPerformanceLow "Right body controller: evap performance low";
CM_ SG_ 524 VCRIGHT_tempAmbientRaw "Right body controller: temp ambient raw";
CM_ SG_ 524 VCRIGHT_hvacHeatingEnabledLeft "Right body controller: hvac heating enabled left";
CM_ SG_ 524 VCRIGHT_hvacHeatingEnabledRight "Right body controller: hvac heating enabled right";
CM_ SG_ 524 VCRIGHT_hvacPerfTestState "The HVAC performance test running state";
CM_ SG_ 524 VCRIGHT_hvacUnavailable "Right body controller: hvac unavailable";
CM_ SG_ 524 VCRIGHT_hvacBlowerRPMActualAP "Right body controller: hvac blower RPM actual AP";
CM_ SG_ 524 VCRIGHT_hvacEvapEnabledInColdAmb "Right body controller: hvac evap enabled in cold ambient";
CM_ BO_ 579 "Right body controller message: hvac status";
CM_ SG_ 579 VCRIGHT_hvacStatusIndex "Right body controller: hvac status index";
CM_ SG_ 579 VCRIGHT_childModeHVACState "Right body controller: child mode HVAC state";
CM_ SG_ 579 VCRIGHT_dogModeState "Reports the state of Dog Mode.";
CM_ SG_ 579 VCRIGHT_hvacCabinTempEstValid "Right body controller: hvac cabin temp est valid";
CM_ SG_ 579 VCRIGHT_COPNotRunningReasonFilte "Reports the reason cabin overheat protection is not running for User Interface (UI).";
CM_ SG_ 579 VCRIGHT_hvacCabinTempEst "Estimated temperature of the cabin";
CM_ SG_ 579 VCRIGHT_hvacAirDistributionMode "Cabin airflow distribution";
CM_ SG_ 579 VCRIGHT_hvacBlowerSegment "Cabin airflow blower set speed segment";
CM_ SG_ 579 VCRIGHT_hvacRecirc "UI airflow recirculation request state";
CM_ SG_ 579 VCRIGHT_hvacACRunning "Air conditioning is active";
CM_ SG_ 579 VCRIGHT_hvacPowerState "Commanded HVAC power state from UI";
CM_ SG_ 579 VCRIGHT_hvacVentStatus "HVAC vent status";
CM_ SG_ 579 VCRIGHT_hvacSecondRowState "Right body controller: hvac second row state";
CM_ SG_ 579 VCRIGHT_hvacSystemNominal "HVAC system state";
CM_ SG_ 579 VCRIGHT_hvacModelInitStatus "Right body controller: hvac model init status";
CM_ SG_ 579 VCRIGHT_hvacMassflowRefrigSysRig "Right body controller: hvac massflow refrig sys right";
CM_ SG_ 579 VCRIGHT_hvacRecircDoorPercent "Reports the HVAC air recirculation massflow fraction target.";
CM_ SG_ 579 VCRIGHT_tempDuctLeft "Fusion of upper and lower left duct temp sensor values for Heat Pump HVAC case, Raw left/right duct temp sensor value for the legacy HVAC case";
CM_ SG_ 579 VCRIGHT_hvacMassflowRefrigSystem "Right body controller: hvac massflow refrig system";
CM_ SG_ 579 VCRIGHT_tempDuctRight "Fusion of upper and lower right duct temp sensor values for Heat Pump HVAC case, Raw left/right duct temp sensor value for the legacy HVAC case";
CM_ SG_ 579 VCRIGHT_hvacMassflowRefrigSysLef "Right body controller: hvac massflow refrig sys left";
CM_ SG_ 579 VCRIGHT_hvacDuctTargetLeft "Left airflow duct temperature target";
CM_ SG_ 579 VCRIGHT_hvacDuctTargetRight "Right airflow duct temperature target";
CM_ SG_ 579 VCRIGHT_enableTripleCameraFanPow "Right body controller: enable triple camera fan power in sleep";
CM_ SG_ 579 VCRIGHT_tempDuctRightUpper "Right body controller: temp duct right upper";
CM_ SG_ 579 VCRIGHT_hpSplitTempsEnabled "Right body controller: hp split temps enabled";
CM_ SG_ 579 VCRIGHT_hvacEvapInletTempEstimat "Right body controller: hvac evap inlet temp estimate";
CM_ SG_ 579 VCRIGHT_tempMonitorNotNominal "Right body controller: temp monitor not nominal";
CM_ SG_ 579 VCRIGHT_hvacCabinAtTempTarget "Cabin has reached target temp, send signal to UI";
CM_ SG_ 579 VCRIGHT_hvacReqSecondRow "Right body controller: hvac req second row";
CM_ SG_ 579 VCRIGHT_hvacAirflowReason "Reason for cabin airflow";
CM_ SG_ 579 VCRIGHT_autoHvacBlowerShouldLimi "Cabin airflow blower auto set speed recommendation based on NVH";
CM_ SG_ 579 VCRIGHT_solarLoadOnVehicle "Right body controller: solar load on vehicle";
CM_ SG_ 579 VCRIGHT_refrigDistCommanded "The HVAC system has set its settings to run the refrigerant distribution routine";
CM_ SG_ 579 VCRIGHT_hvacFrontRightSeatFanSta "Right body controller: hvac front right seat fan status";
CM_ SG_ 579 VCRIGHT_hvacFrontLeftSeatFanStat "Right body controller: hvac front left seat fan status";
CM_ SG_ 579 VCRIGHT_hvacFrontRightSeatHeatSt "Right body controller: hvac front right seat heat status";
CM_ SG_ 579 VCRIGHT_hvacSeatFrontLeftTempTar "Front left seat heating target temperature";
CM_ SG_ 579 VCRIGHT_hvacManualToAutoNotify "Right body controller: hvac manual to auto notify";
CM_ SG_ 579 VCRIGHT_hvacRequestsFullAuto "Request that the UI go to full auto HVAC mode";
CM_ SG_ 579 VCRIGHT_passengerPresentHvacCycl "Right body controller: passenger present hvac cycle";
CM_ SG_ 579 VCRIGHT_hvacRequestsAutoIntake "Request that the UI go to auto intake HVAC mode";
CM_ SG_ 579 VCRIGHT_steeringWheelHeatStatus "Right body controller: steering wheel heat status";
CM_ SG_ 579 VCRIGHT_autoDefogStatus "Indicates defog status of auto HVAC, used for providing messaging to the user";
CM_ SG_ 579 VCRIGHT_solarElevation "Right body controller: solar elevation";
CM_ SG_ 579 VCRIGHT_minsToSunrise "Right body controller: mins to sunrise";
CM_ SG_ 579 VCRIGHT_minsToSunset "Right body controller: mins to sunset";
CM_ SG_ 579 VCRIGHT_hvacLimitedReasonRight "Right body controller: hvac limited reason right";
CM_ SG_ 579 VCRIGHT_hvacLimitedReasonLeft "Right body controller: hvac limited reason left";
CM_ SG_ 579 VCRIGHT_hvacOverheatProtActive "Status of cabin overheat protection";
CM_ SG_ 579 VCRIGHT_tempDuctLeftUpper "Right body controller: temp duct left upper";
CM_ SG_ 579 VCRIGHT_hvacFrontLeftSeatHeatSta "Right body controller: hvac front left seat heat status";
CM_ SG_ 579 VCRIGHT_hvacQdotLeft "Right body controller: hvac qdot left";
CM_ SG_ 579 VCRIGHT_hvacQdotRight "Right body controller: hvac qdot right";
CM_ SG_ 579 VCRIGHT_tempDuctLeftLower "Right body controller: temp duct left lower";
CM_ SG_ 579 VCRIGHT_tempDuctRightLower "Right body controller: temp duct right lower";
CM_ SG_ 579 VCRIGHT_modeledCabinPressure "Right body controller: modeled cabin pressure";
CM_ SG_ 579 VCRIGHT_blowerTorqueIndex "Right body controller: blower torque index";
CM_ SG_ 579 VCRIGHT_autoSwingLeftPosX "Right body controller: auto swing left pos x";
CM_ SG_ 579 VCRIGHT_autoSwingRightPositionX "Right body controller: auto swing right position x";
CM_ SG_ 579 VCRIGHT_autoSwingAvailable "Right body controller: auto swing available";
CM_ BO_ 1675 "Right body controller message: hvac status2";
CM_ SG_ 1675 VCRIGHT_hvacSeat1RLCushionFanTrg "Right body controller: hvac seat1 RL cushion fan trgt";
CM_ SG_ 1675 VCRIGHT_hvacSeat1RLBackrestFanTr "Right body controller: hvac seat1 RL backrest fan trgt";
CM_ SG_ 1675 VCRIGHT_hvacSeat1RRCushionFanTrg "Right body controller: hvac seat1 RR cushion fan trgt";
CM_ SG_ 1675 VCRIGHT_hvacSeat1RRBackrestFanTr "Right body controller: hvac seat1 RR backrest fan trgt";
CM_ SG_ 1675 VCRIGHT_hvac2RActuatorsEnable "Right body controller: hvac2 r actuators enable";
CM_ SG_ 1675 VCRIGHT_hvac2RLeftLateralTarget "Right body controller: hvac2 r left lateral target";
CM_ SG_ 1675 VCRIGHT_hvac2RLeftVerticalTarget "Right body controller: hvac2 r left vertical target";
CM_ SG_ 1675 VCRIGHT_hvac2RRightLateralTarget "Right body controller: hvac2 r right lateral target";
CM_ SG_ 1675 VCRIGHT_hvac2RRightVerticalTarge "Right body controller: hvac2 r right vertical target";
CM_ BO_ 774 "Right body controller message: info";
CM_ SG_ 774 VCRIGHT_infoIndex "Right body controller: info index";
CM_ SG_ 774 VCRIGHT_infoBuildType "Right body controller: info build type";
CM_ SG_ 774 VCRIGHT_infoBuildConfigId "Right body controller: info build config id";
CM_ SG_ 774 VCRIGHT_infoHardwareId "Right body controller: info hardware id";
CM_ SG_ 774 VCRIGHT_infoComponentId "Right body controller: info component id";
CM_ SG_ 774 VCRIGHT_infoPcbaId "Right body controller: info pcba id";
CM_ SG_ 774 VCRIGHT_infoAssemblyId "Right body controller: info assembly id";
CM_ SG_ 774 VCRIGHT_infoUsageId "Right body controller: info usage id";
CM_ SG_ 774 VCRIGHT_infoSubUsageId "Right body controller: info sub usage id";
CM_ SG_ 774 VCRIGHT_infoAppCrc "Right body controller: info app crc";
CM_ SG_ 774 VCRIGHT_infoAppGitHash "Right body controller: info app git hash";
CM_ SG_ 774 VCRIGHT_infoBootGitHash "Right body controller: info boot git hash";
CM_ SG_ 774 VCRIGHT_infoPlatformType "Right body controller: info platform type";
CM_ SG_ 774 VCRIGHT_infoBootUdsProtoVersion "Right body controller: info boot uds proto version";
CM_ SG_ 774 VCRIGHT_infoBootCrc "Right body controller: info boot crc";
CM_ BO_ 995 "Right body controller message: light status";
CM_ SG_ 995 VCRIGHT_brakeLightStatus "Status of rear right brake light source";
CM_ SG_ 995 VCRIGHT_tailLightStatus "Status of right tail (rear position) light source";
CM_ SG_ 995 VCRIGHT_turnSignalStatus "Status of rear right turn signal light source";
CM_ SG_ 995 VCRIGHT_reverseLightStatus "Status of the reverse light source(s)";
CM_ SG_ 995 VCRIGHT_rearFogLightStatus "The desired on/off state of the rear fog light source(s)";
CM_ SG_ 995 VCRIGHT_leftInteriorTrunkLightRe "Right body controller: left interior trunk light req";
CM_ SG_ 995 VCRIGHT_audioCurrentSpikeDetecte "Right body controller: audio current spike detected";
CM_ SG_ 995 VCRIGHT_fasciaReverseLightStatus "Status of fascia reverse lamp";
CM_ SG_ 995 VCRIGHT_fasciaRearFogStatus "Status of fascia rear fog lamp";
CM_ SG_ 995 VCRIGHT_fasciaTailLightStatus "Status of fascia tail lamp";
CM_ SG_ 995 VCRIGHT_fasciaLeftTurnSignalStat "Status of fascia left turn signal";
CM_ SG_ 995 VCRIGHT_fasciaRightTurnSignalSta "Status of fascia right turn signal";
CM_ SG_ 995 VCRIGHT_CHMSLLightStatus "Status of center high mount stop lamp";
CM_ BO_ 1803 "Right body controller message: logging0point1 hz";
CM_ SG_ 1803 VCRIGHT_logging0point1HzIndex "Right body controller: logging0point1 hz index";
CM_ SG_ 1803 VCRIGHT_cabinAirFilterLifeRemain "Life remaining on the cabin air filter";
CM_ SG_ 1803 VCRIGHT_HEPAAirFilterLifeRemaini "Life remaining on the cabin air filter";
CM_ SG_ 1803 VCRIGHT_leftPTCCompromisedRod "Right body controller: left PTC compromised rod";
CM_ SG_ 1803 VCRIGHT_rightPTCCompromisedRod "Right body controller: right PTC compromised rod";
CM_ SG_ 1803 VCRIGHT_hepaFilterHealthScore "Right body controller: hepa filter health score";
CM_ SG_ 1803 VCRIGHT_cabinFilterHealthScore "Right body controller: cabin filter health score";
CM_ SG_ 1803 VCRIGHT_cabinTempBreathLevelFOff "Right body controller: cabin temp breath level f off";
CM_ SG_ 1803 VCRIGHT_airDistributionModeAdjus "Right body controller: air distribution mode adjustment factor";
CM_ SG_ 1803 VCRIGHT_hvacLHBleedEndStop "Right body controller: hvac LH bleed end stop";
CM_ SG_ 1803 VCRIGHT_hvacRHBleedEndStop "Right body controller: hvac RH bleed end stop";
CM_ SG_ 1803 VCRIGHT_hvacLHVaneEndStop "Right body controller: hvac LH vane end stop";
CM_ SG_ 1803 VCRIGHT_hvacRHVaneEndStop "Right body controller: hvac RH vane end stop";
CM_ SG_ 1803 VCRIGHT_hvacUpperModeEndStop "Right body controller: hvac upper mode end stop";
CM_ SG_ 1803 VCRIGHT_hvacLowerModeEndStop "Right body controller: hvac lower mode end stop";
CM_ SG_ 1803 VCRIGHT_hvacIntakeEndStop "Right body controller: hvac intake end stop";
CM_ SG_ 1803 VCRIGHT_hvacLHBleedZeroStop "Right body controller: hvac LH bleed zero stop";
CM_ SG_ 1803 VCRIGHT_hvacRHBleedZeroStop "Right body controller: hvac RH bleed zero stop";
CM_ SG_ 1803 VCRIGHT_hvacLHVaneZeroStop "Right body controller: hvac LH vane zero stop";
CM_ SG_ 1803 VCRIGHT_hvacRHVaneZeroStop "Right body controller: hvac RH vane zero stop";
CM_ SG_ 1803 VCRIGHT_hvacUpperModeZeroStop "Right body controller: hvac upper mode zero stop";
CM_ SG_ 1803 VCRIGHT_hvacLowerModeZeroStop "Right body controller: hvac lower mode zero stop";
CM_ SG_ 1803 VCRIGHT_hvacIntakeZeroStop "Right body controller: hvac intake zero stop";
CM_ SG_ 1803 VCRIGHT_ambientTempLimp "Reports the estimated ambient temperature in limp mode.";
CM_ SG_ 1803 VCRIGHT_cabinProbeTempLimp "Reports the estimated cabin probe temperature in limp mode.";
CM_ SG_ 1803 VCRIGHT_thsTempLimp "Reports the estimated Tesla HVAC Sensor (THS) temperature in limp mode.";
CM_ SG_ 1803 VCRIGHT_thsCabinWaterMassLimp "Reports the estimated Tesla HVAC Sensor (THS) humidity cabin water mass backup in limp mode.";
CM_ SG_ 1803 VCRIGHT_thsSolarIrradianceLimp "Reports the estimated Tesla HVAC Sensor (THS) solar irradiance backup in limp mode.";
CM_ SG_ 1803 VCRIGHT_silentWakeRecordCount "Reports the number of records recorded during silent wake events.";
CM_ SG_ 1803 VCRIGHT_evapCondensateMass "Right body controller: evap condensate mass";
CM_ SG_ 1803 VCRIGHT_airwaveRightLateralTotal "Right body controller: airwave right lateral total travel";
CM_ SG_ 1803 VCRIGHT_airwaveLeftLateralTotalT "Right body controller: airwave left lateral total travel";
CM_ BO_ 611 "Right body controller message: logging10 hz";
CM_ SG_ 611 VCRIGHT_logging10HzIndex "Right body controller: logging10 hz index";
CM_ SG_ 611 VCRIGHT_hvacLHBleedTarget "Right body controller: hvac LH bleed target";
CM_ SG_ 611 VCRIGHT_hvacRHBleedTarget "Right body controller: hvac RH bleed target";
CM_ SG_ 611 VCRIGHT_hvacLHVaneTarget "Right body controller: hvac LH vane target";
CM_ SG_ 611 VCRIGHT_hvacRHVaneTarget "Right body controller: hvac RH vane target";
CM_ SG_ 611 VCRIGHT_hvacUpperModeTarget "Right body controller: hvac upper mode target";
CM_ SG_ 611 VCRIGHT_hvacLowerModeTarget "Right body controller: hvac lower mode target";
CM_ SG_ 611 VCRIGHT_hvacIntakeTarget "Right body controller: hvac intake target";
CM_ SG_ 611 VCRIGHT_hvacLHBleedPosition "Right body controller: hvac LH bleed position";
CM_ SG_ 611 VCRIGHT_hvacRHBleedPosition "Right body controller: hvac RH bleed position";
CM_ SG_ 611 VCRIGHT_hvacLHVanePosition "Right body controller: hvac LH vane position";
CM_ SG_ 611 VCRIGHT_hvacRHVanePosition "Right body controller: hvac RH vane position";
CM_ SG_ 611 VCRIGHT_hvacUpperModePosition "Right body controller: hvac upper mode position";
CM_ SG_ 611 VCRIGHT_hvacLowerModePosition "Right body controller: hvac lower mode position";
CM_ SG_ 611 VCRIGHT_hvacIntakePosition "Right body controller: hvac intake position";
CM_ SG_ 611 VCRIGHT_hvacLHBleedActuatorState "Right body controller: hvac LH bleed actuator state";
CM_ SG_ 611 VCRIGHT_hvacRHBleedActuatorState "Right body controller: hvac RH bleed actuator state";
CM_ SG_ 611 VCRIGHT_hvacLHVaneActuatorState "Right body controller: hvac LH vane actuator state";
CM_ SG_ 611 VCRIGHT_hvacRHVaneActuatorState "Right body controller: hvac RH vane actuator state";
CM_ SG_ 611 VCRIGHT_hvacUpperModeActState "Right body controller: hvac upper mode act state";
CM_ SG_ 611 VCRIGHT_hvacLowerModeActState "Right body controller: hvac lower mode act state";
CM_ SG_ 611 VCRIGHT_hvacIntakeActuatorState "Right body controller: hvac intake actuator state";
CM_ SG_ 611 VCRIGHT_EvapPulldownBiasActive "Indicates if an evap pulldown smell mitigation is active";
CM_ SG_ 611 VCRIGHT_tempDatLeftEst "Right body controller: temp dat left est";
CM_ SG_ 611 VCRIGHT_tempDatRightEst "Right body controller: temp dat right est";
CM_ SG_ 611 VCRIGHT_tempDuctLeftEst "Right body controller: temp duct left est";
CM_ SG_ 611 VCRIGHT_tempDuctRightEst "Right body controller: temp duct right est";
CM_ SG_ 611 VCRIGHT_ptcHeaterBadRodDetection "Right body controller: ptc heater bad rod detection state";
CM_ SG_ 611 VCRIGHT_leftVerticalActuatorDuty "Reports the HVAC motor duty cycle";
CM_ SG_ 611 VCRIGHT_leftLateralActuatorDuty "Reports the HVAC motor duty cycle";
CM_ SG_ 611 VCRIGHT_rightVerticalActuatorDut "Reports the HVAC motor duty cycle";
CM_ SG_ 611 VCRIGHT_rightLateralActuatorDuty "Reports the HVAC motor duty cycle";
CM_ SG_ 611 VCRIGHT_frontLeftSeatTempTargetQ "Reports the front left seat heating target temperature.";
CM_ SG_ 611 VCRIGHT_frontRightSeatTempTarget "Reports the front right seat heating target temperature.";
CM_ BO_ 691 "Right body controller message: logging1 hz";
CM_ SG_ 691 VCRIGHT_logging1HzIndex "Right body controller: logging1 hz index";
CM_ SG_ 691 VCRIGHT_tempIncarCabinProbe "Right body controller: temp incar cabin probe";
CM_ SG_ 691 VCRIGHT_tempIncarCabinDeep "Right body controller: temp incar cabin deep";
CM_ SG_ 691 VCRIGHT_cabinTempInteriorL2 "Right body controller: cabin temp interior L2";
CM_ SG_ 691 VCRIGHT_tempIncarCabinMid "Right body controller: temp incar cabin mid";
CM_ SG_ 691 VCRIGHT_cabinTempInteriorSunnyL2 "Right body controller: cabin temp interior sunny L2";
CM_ SG_ 691 VCRIGHT_cabinTempInteriorL3 "Right body controller: cabin temp interior L3";
CM_ SG_ 691 VCRIGHT_cabinTempInteriorSunnyL3 "Right body controller: cabin temp interior sunny L3";
CM_ SG_ 691 VCRIGHT_cabinTempGlassRoof "Modeled cabin temperature near the glass roof";
CM_ SG_ 691 VCRIGHT_cabinTempWindshield "Windshield temperature estimate";
CM_ SG_ 691 VCRIGHT_cabinTempInterior "Modeled interior cabin temperature";
CM_ SG_ 691 VCRIGHT_cabinTempInteriorSunny "Modeled interior surface temperature exposed to direct sunlight";
CM_ SG_ 691 VCRIGHT_cabinTempSideGlassLeft "Modeled glass temperature left";
CM_ SG_ 691 VCRIGHT_cabinTempSideGlassRight "Modeled glass temperature right";
CM_ SG_ 691 VCRIGHT_cabinTempBreathLevel "Modeled cabin temperature near occupant breathing level";
CM_ SG_ 691 VCRIGHT_pcbaTemperature "Right body controller: pcba temperature";
CM_ SG_ 691 VCRIGHT_wattsHeaterLeftTotal "Right body controller: watts heater left total";
CM_ SG_ 691 VCRIGHT_wattsHeaterRightTotal "Right body controller: watts heater right total";
CM_ SG_ 691 VCRIGHT_qdotLeftFFUnsat "Right body controller: qdot left FF unsat";
CM_ SG_ 691 VCRIGHT_qdotRightFFUnsat "Right body controller: qdot right FF unsat";
CM_ SG_ 691 VCRIGHT_nvhLevelDb "Right body controller: nvh level db";
CM_ SG_ 691 VCRIGHT_hvacSetTempActualLeft "HVAC internal left temperature set point";
CM_ SG_ 691 VCRIGHT_hvacSetTempActualRight "HVAC internal right temperature set point";
CM_ SG_ 691 VCRIGHT_hvacAutoTransitionReason "Reason for airflow mode change when system is operating in auto";
CM_ SG_ 691 VCRIGHT_hvacMassflowTarget "Right body controller: hvac massflow target";
CM_ SG_ 691 VCRIGHT_hvacQdotLimitedLeft "Right body controller: hvac qdot limited left";
CM_ SG_ 691 VCRIGHT_hvacQdotLimitedRight "Right body controller: hvac qdot limited right";
CM_ SG_ 691 VCRIGHT_LHPanelAirflowBlocked "Right body controller: LH panel airflow blocked";
CM_ SG_ 691 VCRIGHT_RHPanelAirflowBlocked "Right body controller: RH panel airflow blocked";
CM_ SG_ 691 VCRIGHT_floorAirflowBlocked "Right body controller: floor airflow blocked";
CM_ SG_ 691 VCRIGHT_defrostAirflowBlocked "Right body controller: defrost airflow blocked";
CM_ SG_ 691 VCRIGHT_hvacFilterLifeDetectActi "Indicates when filter life detection is active";
CM_ SG_ 691 VCRIGHT_hvacLHBleedOperationMode "Right body controller: hvac LH bleed operation mode";
CM_ SG_ 691 VCRIGHT_hvacRHBleedOperationMode "Right body controller: hvac RH bleed operation mode";
CM_ SG_ 691 VCRIGHT_hvacLHVaneOperationMode "Right body controller: hvac LH vane operation mode";
CM_ SG_ 691 VCRIGHT_hvacRHVaneOperationMode "Right body controller: hvac RH vane operation mode";
CM_ SG_ 691 VCRIGHT_hvacUpperModeOpMode "Right body controller: hvac upper mode op mode";
CM_ SG_ 691 VCRIGHT_hvacLowerModeOpMode "Right body controller: hvac lower mode op mode";
CM_ SG_ 691 VCRIGHT_hvacIntakeOperationMode "Right body controller: hvac intake operation mode";
CM_ SG_ 691 VCRIGHT_isProbeFeedbackApplied "Right body controller: is probe feedback applied";
CM_ SG_ 691 VCRIGHT_feedbackPullDownScalar "Right body controller: feedback pull down scalar";
CM_ SG_ 691 VCRIGHT_feedForwardPullDownScala "Right body controller: feed forward pull down scalar";
CM_ SG_ 691 VCRIGHT_convectionTargetLeft "Right body controller: convection target left";
CM_ SG_ 691 VCRIGHT_convectionTargetRight "Right body controller: convection target right";
CM_ SG_ 691 VCRIGHT_convectionDeliveredLeft "Right body controller: convection delivered left";
CM_ SG_ 691 VCRIGHT_convectionDeliveredRight "Right body controller: convection delivered right";
CM_ SG_ 691 VCRIGHT_solarLoadRightOccupant "Right body controller: solar load right occupant";
CM_ SG_ 691 VCRIGHT_solarLoadLeftOccupant "Right body controller: solar load left occupant";
CM_ SG_ 691 VCRIGHT_ptcShutOutletMitigationA "Right body controller: ptc shut outlet mitigation active";
CM_ SG_ 691 VCRIGHT_solarLoadFromThsTemp "Right body controller: solar load from ths temp";
CM_ SG_ 691 VCRIGHT_ptcHeaterTempDuctHigh "Right body controller: ptc heater temp duct high";
CM_ SG_ 691 VCRIGHT_ptcHeaterTempDuctFault "Right body controller: ptc heater temp duct fault";
CM_ SG_ 691 VCRIGHT_ptcHeaterNoAirflow "Right body controller: ptc heater no airflow";
CM_ SG_ 691 VCRIGHT_ptcHeaterHvacActNotReady "Right body controller: ptc heater hvac act not ready";
CM_ SG_ 691 VCRIGHT_ptcHeaterNoUiRequest "Right body controller: ptc heater no ui request";
CM_ SG_ 691 VCRIGHT_ptcHeaterNoHighVoltage "Right body controller: ptc heater no high voltage";
CM_ SG_ 691 VCRIGHT_ptcHeaterLAirPathBlocked "Right body controller: ptc heater l air path blocked";
CM_ SG_ 691 VCRIGHT_ptcHeaterRAirPathBlocked "Right body controller: ptc heater r air path blocked";
CM_ SG_ 691 VCRIGHT_ptcHeaterReqAirpathBlock "Right body controller: ptc heater req airpath blocked";
CM_ SG_ 691 VCRIGHT_hvacQdotFeedforward "Right body controller: hvac qdot feedforward";
CM_ SG_ 691 VCRIGHT_evapLoadInFresh "Right body controller: evap load in fresh";
CM_ SG_ 691 VCRIGHT_evapLoadInRecirc "Right body controller: evap load in recirc";
CM_ SG_ 691 VCRIGHT_cabinTempWshldDefog "Windshield temperature estimate used for defogging";
CM_ SG_ 691 VCRIGHT_cabinTempWshldDefogTop "Right body controller: cabin temp wshld defog top";
CM_ SG_ 691 VCRIGHT_hvacLHBleedVoltage "Right body controller: hvac LH bleed voltage";
CM_ SG_ 691 VCRIGHT_hvacRHBleedVoltage "Right body controller: hvac RH bleed voltage";
CM_ SG_ 691 VCRIGHT_hvacLHVaneVoltage "Right body controller: hvac LH vane voltage";
CM_ SG_ 691 VCRIGHT_hvacRHVaneVoltage "Right body controller: hvac RH vane voltage";
CM_ SG_ 691 VCRIGHT_hvacUpperModeVoltage "Right body controller: hvac upper mode voltage";
CM_ SG_ 691 VCRIGHT_hvacLowerModeVoltage "Right body controller: hvac lower mode voltage";
CM_ SG_ 691 VCRIGHT_hvacIntakeVoltage "Right body controller: hvac intake voltage";
CM_ SG_ 691 VCRIGHT_cabinTempBreathLevelFHea "Right body controller: cabin temp breath level f heating";
CM_ SG_ 691 VCRIGHT_cabinTempBreathLevelFCoo "Right body controller: cabin temp breath level f cooling";
CM_ SG_ 691 VCRIGHT_cabinTempBreathLeve_0002 "Right body controller: cabin temp breath level f5min heating";
CM_ SG_ 691 VCRIGHT_cabinTempBreathLevelF5mi "Right body controller: cabin temp breath level f5min cooling";
CM_ SG_ 691 VCRIGHT_cabinTempBreathLeve_0001 "Right body controller: cabin temp breath level f10min heating";
CM_ SG_ 691 VCRIGHT_cabinTempBreathLevelF10m "Right body controller: cabin temp breath level f10min cooling";
CM_ SG_ 691 VCRIGHT_cabinTempInteriorFHeatin "Right body controller: cabin temp interior f heating";
CM_ SG_ 691 VCRIGHT_hvacCabOvrheatProtActive "Status of cabin overheat protection";
CM_ SG_ 691 VCRIGHT_hvacCabinPurgeAllowed "Right body controller: hvac cabin purge allowed";
CM_ SG_ 691 VCRIGHT_hvacCabOvrheatProtAllowe "Cabin overheat protection is allowed to run";
CM_ SG_ 691 VCRIGHT_filterLifeBlowerTorque "Right body controller: filter life blower torque";
CM_ SG_ 691 VCRIGHT_cabinTempFanCurrent "Right body controller: cabin temp fan current";
CM_ SG_ 691 VCRIGHT_cabinTempFanOutput "Right body controller: cabin temp fan output";
CM_ SG_ 691 VCRIGHT_cloudinessEstimatedPct "Right body controller: cloudiness estimated pct";
CM_ SG_ 691 VCRIGHT_solarLoadOnVehFiltered "Right body controller: solar load on veh filtered";
CM_ SG_ 691 VCRIGHT_cabinTempProbeEstimate "Right body controller: cabin temp probe estimate";
CM_ SG_ 691 VCRIGHT_cabinTempThs "Estimated temperature from Tesla HVAC Sensor";
CM_ SG_ 691 VCRIGHT_cabinTempThsBracket "Right body controller: cabin temp ths bracket";
CM_ SG_ 691 VCRIGHT_leftHeatOvertempProtect "Right body controller: left heat overtemp protect";
CM_ SG_ 691 VCRIGHT_rightHeatOvertempProtect "Right body controller: right heat overtemp protect";
CM_ SG_ 691 VCRIGHT_CO2ppm "Right body controller: co2ppm";
CM_ SG_ 691 VCRIGHT_timeLeftToCabinModelInit "Right body controller: time left to cabin model init";
CM_ SG_ 691 VCRIGHT_hvacEstimateWindshieldRH "Estimated windshield relative humidity";
CM_ SG_ 691 VCRIGHT_hvacFoggingRiskLevel "Control signal of the windshield fogging risk controller";
CM_ SG_ 691 VCRIGHT_hvacCabinHumidityLevel "Control signal of the cabin humidity controller";
CM_ SG_ 691 VCRIGHT_hvacFlashFoggingDetected "Windshield flash fogging risk detected";
CM_ SG_ 691 VCRIGHT_solarSensitivityInfr "Right body controller: solar sensitivity infr";
CM_ SG_ 691 VCRIGHT_solarSensitivityInfrCorr "Right body controller: solar sensitivity infr corr";
CM_ SG_ 691 VCRIGHT_lumbarCurrent "Electrical current of the lumbar ECU";
CM_ SG_ 691 VCRIGHT_ocsCurrent "Electrical current of the OCS ECU";
CM_ SG_ 691 VCRIGHT_rcmCurrent "Electrical current of the RCM ECU";
CM_ SG_ 691 VCRIGHT_radioTunerCurrent "Electrical current of the Radio Tuner";
CM_ SG_ 691 VCRIGHT_rearOilPumpCurrent "Right body controller: rear oil pump current";
CM_ SG_ 691 VCRIGHT_rearDefrostCurrent "Right body controller: rear defrost current";
CM_ SG_ 691 VCRIGHT_tailLightCurrent "Electrical current of the tail and license plate lights";
CM_ SG_ 691 VCRIGHT_turnTailStopLightCurrent "Reports the electrical current of the right rear turn indicator, right rear tail light, or right rear brake light";
CM_ SG_ 691 VCRIGHT_reverseFogLightsCurrent "Electrical current of the trunk fog light";
CM_ SG_ 691 VCRIGHT_stopReverseTurnLightCurr "Reports the electrical current of the right rear brake light, right rear reverse light, or right rear turn indicator";
CM_ SG_ 691 VCRIGHT_sideMirrorCurrent "Electrical current of side mirror tilt and fold";
CM_ SG_ 691 VCRIGHT_sideMirrorHeaterCurrent "Electrical current of the mirror heater";
CM_ SG_ 691 VCRIGHT_frontSeatHeatCushionPwr "Right body controller: front seat heat cushion pwr";
CM_ SG_ 691 VCRIGHT_trunkInteriorLEDCurrent "Electrical current of the trunk interior light";
CM_ SG_ 691 VCRIGHT_mapPocketLEDsCurrent "Electrical current of the map pocket lights";
CM_ SG_ 691 VCRIGHT_miscEFuseCurrent "Right body controller: misc e fuse current";
CM_ SG_ 691 VCRIGHT_interiorHandleLEDCurrent "Electrical current of the interior handle LED";
CM_ SG_ 691 VCRIGHT_miscInteriorLightsCurren "Electrical current of the misc interior lights";
CM_ SG_ 691 VCRIGHT_frontPuddleLEDCurrent "Electrical current of the front puddle LED";
CM_ SG_ 691 VCRIGHT_rearPuddleLEDCurrent "Electrical current of the rear puddle LED";
CM_ SG_ 691 VCRIGHT_liftgateShutfaceLEDCurre "Electrical current of the liftgate shutface LED";
CM_ SG_ 691 VCRIGHT_3rSeatTOSCurrent "Electrical current of the 3R TOS";
CM_ SG_ 691 VCRIGHT_vbatFusedCurrent "Right body controller: vbat fused current";
CM_ SG_ 691 VCRIGHT_cabinTempGlassGridHeater "Right body controller: cabin temp glass grid heater";
CM_ SG_ 691 VCRIGHT_hvacAirflowReasonRight "Right body controller: hvac airflow reason right";
CM_ SG_ 691 VCRIGHT_hvacAirflowReasonLeft "Right body controller: hvac airflow reason left";
CM_ SG_ 691 VCRIGHT_hvacMassflowTargetLeft "Right body controller: hvac massflow target left";
CM_ SG_ 691 VCRIGHT_hvacMassflowTargetRight "Right body controller: hvac massflow target right";
CM_ SG_ 691 VCRIGHT_solarLoadLeftOccupantFil "Right body controller: solar load left occupant filt";
CM_ SG_ 691 VCRIGHT_solarLoadRightOccupantFi "Right body controller: solar load right occupant filt";
CM_ SG_ 691 VCRIGHT_windshieldRHCapped "Estimated windshield relative humidity";
CM_ SG_ 691 VCRIGHT_feedbackWarmUpScalar "Right body controller: feedback warm up scalar";
CM_ SG_ 691 VCRIGHT_maxMassflowScalarWarmUp "Right body controller: max massflow scalar warm up";
CM_ SG_ 691 VCRIGHT_feedforwardWarmUpScalar "Right body controller: feedforward warm up scalar";
CM_ SG_ 691 VCRIGHT_frontSeatHeatBackrestPwr "Right body controller: front seat heat backrest pwr";
CM_ SG_ 691 VCRIGHT_maxMassflowScalar "Right body controller: max massflow scalar";
CM_ SG_ 691 VCRIGHT_massflowTargetAutoInManu "Right body controller: massflow target auto in manual mode";
CM_ SG_ 691 VCRIGHT_airflowReasonAutoInManua "Right body controller: airflow reason auto in manual mode";
CM_ SG_ 691 VCRIGHT_airflowReasonAutoIn_0001 "Right body controller: airflow reason auto in manual mode left";
CM_ SG_ 691 VCRIGHT_airflowReasonAutoIn_0002 "Right body controller: airflow reason auto in manual mode right";
CM_ SG_ 691 VCRIGHT_cabinTempInteriorFCoolin "Right body controller: cabin temp interior f cooling";
CM_ SG_ 691 VCRIGHT_averageDuctTempFHeating "Estimated average duct temp temp 15 min into the drive";
CM_ SG_ 691 VCRIGHT_averageDuctTempFCooling "Estimated average duct temp temp 15 min into the drive";
CM_ SG_ 691 VCRIGHT_hvacBiLevelWhsldRhEst "Right body controller: hvac bi level whsld rh est";
CM_ SG_ 691 VCRIGHT_steeringWheelSurfaceTemp "Right body controller: steering wheel surface temp est";
CM_ SG_ 691 VCRIGHT_steeringWheelSurfac_0001 "Right body controller: steering wheel surface temp tgt";
CM_ SG_ 691 VCRIGHT_timeToComfortHeating "Right body controller: time to comfort heating";
CM_ SG_ 691 VCRIGHT_timeToComfortCooling "Right body controller: time to comfort cooling";
CM_ SG_ 691 VCRIGHT_cabinWaterMassRaw "Right body controller: cabin water mass raw";
CM_ SG_ 691 VCRIGHT_massflowSingleZoneSplit "Right body controller: massflow single zone split";
CM_ SG_ 691 VCRIGHT_VOCPurgeState "Right body controller: VOC purge state";
CM_ SG_ 691 VCRIGHT_cameraFoggingMonitorStat "Right body controller: camera fogging monitor state";
CM_ SG_ 691 VCRIGHT_cabinOverheatProtectNotR "Reports all reasons cabin overheat protection is not running.";
CM_ SG_ 691 VCRIGHT_hvacIntakeReason "Reason for current intake door position";
CM_ SG_ 691 VCRIGHT_hvacCabinPurgeActive "Indicates if cabin purge is active";
CM_ SG_ 691 VCRIGHT_solarAzimuthCarRef "Right body controller: solar azimuth car ref";
CM_ SG_ 691 VCRIGHT_massflowPulldownBias "Right body controller: massflow pulldown bias";
CM_ SG_ 691 VCRIGHT_evapPulldownBias "Right body controller: evap pulldown bias";
CM_ SG_ 691 VCRIGHT_modeledMassflowFresh "Right body controller: modeled massflow fresh";
CM_ SG_ 691 VCRIGHT_modeledMassflowRecirc "Right body controller: modeled massflow recirc";
CM_ SG_ 691 VCRIGHT_hvacLimpModeStatus "Reports the cabin model limp mode status.";
CM_ SG_ 691 VCRIGHT_hvacEstimatedCameraWinds "Right body controller: hvac estimated camera windshield RH";
CM_ BO_ 1859 "Right body controller message: recall status";
CM_ SG_ 1859 VCRIGHT_systemRecallStatus "Recall state of superset of body controls ECUs";
CM_ SG_ 1859 VCRIGHT_seatRecallStatus "Right body controller: seat recall status";
CM_ SG_ 1859 VCRIGHT_mirrorRecallStatus "Recall status for the right side view mirror";
CM_ BO_ 1862 "Right body controller message: restraint status";
CM_ SG_ 1862 VCRIGHT_frontOccupancyStatus "Right body controller: front occupancy status";
CM_ SG_ 1862 VCRIGHT_frontBuckleStatus "Status of front right seatbelt buckle";
CM_ SG_ 1862 VCRIGHT_rearCenterBuckleStatus "Right body controller: rear center buckle status";
CM_ SG_ 1862 VCRIGHT_rearRightBuckleStatus "Right body controller: rear right buckle status";
CM_ SG_ 1862 VCRIGHT_rearRightOccupancyStatus "Right body controller: rear right occupancy status";
CM_ SG_ 1862 VCRIGHT_3RowLeftBuckleStatus "Status of third row left seatbelt buckle";
CM_ SG_ 1862 VCRIGHT_3RowRightBuckleStatus "Right body controller: 3 row right buckle status";
CM_ SG_ 1862 VCRIGHT_3RowLeftOccupancyStatus "Right body controller: 3 row left occupancy status";
CM_ SG_ 1862 VCRIGHT_3RowRightOccupancyStatus "Right body controller: 3 row right occupancy status";
CM_ SG_ 1862 VCRIGHT_seatTrackPosition "Right body controller: seat track position";
CM_ SG_ 1862 VCRIGHT_occupantClassification "Right body controller: occupant classification";
CM_ SG_ 1862 VCRIGHT_occupantClassificationQF "Right body controller: occupant classification QF";
CM_ SG_ 1862 VCRIGHT_classificationEnabled "Indicates whether the RCM should consume VCRIGHT occupant classification rather than another source such as OCS1P";
CM_ SG_ 1862 VCRIGHT_classificationEnabledQF "Indicates whether the VCRIGHT_classificationEnabled signal is valid";
CM_ SG_ 1862 VCRIGHT_restraintStatusCounter "Right body controller: restraint status counter";
CM_ SG_ 1862 VCRIGHT_restraintStatusChecksum "Right body controller: restraint status checksum";
CM_ BO_ 1251 "Right body controller message: seat status";
CM_ SG_ 1251 VCRIGHT_seatStatusIndex "Right body controller: seat status index";
CM_ SG_ 1251 VCRIGHT_frontSeatTrackPos "Motor encoder value representing front left seat track position";
CM_ SG_ 1251 VCRIGHT_frontSeatTrackCurrent "Current drawn by front left seat track motor";
CM_ SG_ 1251 VCRIGHT_frontSeatTrackDuty "Front left seat track motor duty cycle";
CM_ SG_ 1251 VCRIGHT_frontSeatTrackState "State of front right seat track motor";
CM_ SG_ 1251 VCRIGHT_frontSeatTrackCalibrated "Right body controller: front seat track calibrated";
CM_ SG_ 1251 VCRIGHT_frontSeatTrackLog "Right body controller: front seat track log";
CM_ SG_ 1251 VCRIGHT_frontSeatTrackBridgeSt "Bridge state";
CM_ SG_ 1251 VCRIGHT_frontSeatBackPos "Motor encoder value representing front right seat backrest position";
CM_ SG_ 1251 VCRIGHT_frontSeatBackCurrent "Current drawn by front right seat backrest motor";
CM_ SG_ 1251 VCRIGHT_frontSeatBackDuty "Front right seat backrest motor duty cycle";
CM_ SG_ 1251 VCRIGHT_frontSeatBackState "Active state of front right seat backrest";
CM_ SG_ 1251 VCRIGHT_frontSeatBackCalibrated "Right body controller: front seat back calibrated";
CM_ SG_ 1251 VCRIGHT_frontSeatBackLog "Right body controller: front seat back log";
CM_ SG_ 1251 VCRIGHT_frontSeatBackBridgeSt "Bridge state";
CM_ SG_ 1251 VCRIGHT_frontSeatLiftPos "Motor encoder value representing front left seat lift position";
CM_ SG_ 1251 VCRIGHT_frontSeatLiftCurrent "Current drawn by front left seat lift motor";
CM_ SG_ 1251 VCRIGHT_frontSeatLiftDuty "Front left seat lift motor duty cycle";
CM_ SG_ 1251 VCRIGHT_frontSeatLiftState "Status of front left seat motor";
CM_ SG_ 1251 VCRIGHT_frontSeatLiftCalibrated "Right body controller: front seat lift calibrated";
CM_ SG_ 1251 VCRIGHT_frontSeatLiftLog "Right body controller: front seat lift log";
CM_ SG_ 1251 VCRIGHT_frontSeatLiftBridgeSt "Bridge state";
CM_ SG_ 1251 VCRIGHT_frontSeatTiltPos "Motor encoder value representing front left seat tilt position";
CM_ SG_ 1251 VCRIGHT_frontSeatTiltCurrent "Current drawn by front left seat tilt motor";
CM_ SG_ 1251 VCRIGHT_frontSeatTiltDuty "Front left seat tilt motor duty cycle";
CM_ SG_ 1251 VCRIGHT_frontSeatTiltState "State of front right seat tilt motor";
CM_ SG_ 1251 VCRIGHT_frontSeatTiltCalibrated "Right body controller: front seat tilt calibrated";
CM_ SG_ 1251 VCRIGHT_frontSeatTiltLog "Right body controller: front seat tilt log";
CM_ SG_ 1251 VCRIGHT_frontSeatTiltBridgeSt "Bridge state";
CM_ SG_ 1251 VCRIGHT_lumbarAState "State of front right seat lumbar bladder A";
CM_ SG_ 1251 VCRIGHT_lumbarBState "State of front right lumbar bladder B";
CM_ SG_ 1251 VCRIGHT_lumbarAPressureHpa "Right body controller: lumbar a pressure hpa";
CM_ SG_ 1251 VCRIGHT_lumbarAPressureHpaFilt "logs filtered pressure of right seat lumbar bladder A";
CM_ SG_ 1251 VCRIGHT_lumbarBPressureHpa "Right body controller: lumbar b pressure hpa";
CM_ SG_ 1251 VCRIGHT_lumbarBPressureHpaFilt "logs filtered pressure of right seat lumbar bladder B";
CM_ SG_ 1251 VCRIGHT_lumbarActiveTooLongErr "Error reported by lumbar ECU: Valve activated too long";
CM_ SG_ 1251 VCRIGHT_lumbarMaxPErr "Error reported by lumbar ECU: max bladder pressure reached";
CM_ SG_ 1251 VCRIGHT_lumbarOvercurrentErr "Error reported by lumbar ECU: pump overcurrent";
CM_ SG_ 1251 VCRIGHT_lumbarMaxOperatingPErr "Error reported by lumbar ECU: max bladder operating pressure reached";
CM_ SG_ 1251 VCRIGHT_lumbarMinPErr "Error reported by lumbar ECU: min bladder pressure reached";
CM_ SG_ 1251 VCRIGHT_lumbarGeneralErr "Error reported by lumbar ECU: general error";
CM_ SG_ 1251 VCRIGHT_lumbarDevMaxPumpPressA "System has reached Tesla specified maximum pressure for lumbar bladder A";
CM_ SG_ 1251 VCRIGHT_lumbarDevMaxPumpPressB "System has reached Tesla specified maximum pressure for lumbar bladder B";
CM_ SG_ 1251 VCRIGHT_frontSeatTrackPosReal "Front right seat track position in millimeters";
CM_ SG_ 1251 VCRIGHT_frontSeatBackPosReal "Front right seat backrest position in degrees";
CM_ SG_ 1251 VCRIGHT_frontSeatLiftPosReal "Front right seat lift position in millimeters";
CM_ SG_ 1251 VCRIGHT_frontSeatTiltPosReal "Front right seat tilt position in degrees";
CM_ SG_ 1251 VCRIGHT_frontSeatTrackPosOffset "Communicates post calibration position offset of front right seat track in a physical unit";
CM_ SG_ 1251 VCRIGHT_frontSeatBackPosOffset "Communicates post calibration position offset of front right seat backrest in a physical unit";
CM_ SG_ 1251 VCRIGHT_frontSeatLiftPosOffset "Communicates post calibration position offset of front right seat lift in a physical unit";
CM_ SG_ 1251 VCRIGHT_frontSeatTiltPosOffset "Communicates post calibration position offset of front right seat tilt in a physical unit";
CM_ BO_ 739 "Right body controller message: seat status2";
CM_ SG_ 739 VCRIGHT_seatStatus2Index "Right body controller: seat status2 index";
CM_ SG_ 739 VCRIGHT_frontSeatHeatCurrent "Right body controller: front seat heat current";
CM_ SG_ 739 VCRIGHT_frontSeatHeatDuty "Right body controller: front seat heat duty";
CM_ SG_ 739 VCRIGHT_frontSeatHeatTmp "Right body controller: front seat heat tmp";
CM_ SG_ 739 VCRIGHT_frontSeatHeatTmpTarget "Target temperature for front right seat heater";
CM_ SG_ 739 VCRIGHT_frontSeatHeatInhibited "Front right seat heater duty cycle";
CM_ SG_ 739 VCRIGHT_frontSeatHeatPowered "Right body controller: front seat heat powered";
CM_ SG_ 739 VCRIGHT_rearLSeatHeatCurrent "Current drawn by rear center seat heater";
CM_ SG_ 739 VCRIGHT_rearLSeatHeatDuty "Right body controller: rear l seat heat duty";
CM_ SG_ 739 VCRIGHT_rearLSeatHeatTmp "Right body controller: rear l seat heat tmp";
CM_ SG_ 739 VCRIGHT_rearLSeatHeatTmpTarget "Right body controller: rear l seat heat tmp target";
CM_ SG_ 739 VCRIGHT_rearLSeatHeatInhibited "Right body controller: rear l seat heat inhibited";
CM_ SG_ 739 VCRIGHT_rearLSeatHeatPowered "Right body controller: rear l seat heat powered";
CM_ SG_ 739 VCRIGHT_rearCSeatHeatCurrent "Right body controller: rear c seat heat current";
CM_ SG_ 739 VCRIGHT_rearCSeatHeatDuty "Right body controller: rear c seat heat duty";
CM_ SG_ 739 VCRIGHT_rearCSeatHeatTmp "Right body controller: rear c seat heat tmp";
CM_ SG_ 739 VCRIGHT_rearCSeatHeatTmpTarget "Right body controller: rear c seat heat tmp target";
CM_ SG_ 739 VCRIGHT_rearCSeatHeatInhibited "Right body controller: rear c seat heat inhibited";
CM_ SG_ 739 VCRIGHT_rearCSeatHeatPowered "Right body controller: rear c seat heat powered";
CM_ SG_ 739 VCRIGHT_rearRSeatHeatCurrent "Right body controller: rear r seat heat current";
CM_ SG_ 739 VCRIGHT_rearRSeatHeatDuty "Right body controller: rear r seat heat duty";
CM_ SG_ 739 VCRIGHT_rearRSeatHeatTmp "Right body controller: rear r seat heat tmp";
CM_ SG_ 739 VCRIGHT_rearRSeatHeatTmpTarget "Right body controller: rear r seat heat tmp target";
CM_ SG_ 739 VCRIGHT_rearRSeatHeatInhibited "Right body controller: rear r seat heat inhibited";
CM_ SG_ 739 VCRIGHT_rearRSeatHeatPowered "Right body controller: rear r seat heat powered";
CM_ SG_ 739 VCRIGHT_2RowSeatReclineState "Reports the active state of the 2nd row seat recliner";
CM_ SG_ 739 VCRIGHT_2RowSeatReclineDuty "Reports the 2nd row seat recliner motor duty cycle";
CM_ SG_ 739 VCRIGHT_2RowSeatReclineCurrent "Reports the 2nd row seat recliner motor current";
CM_ SG_ 739 VCRIGHT_2RowSeatReclineCalibrate "Reports calibration status of the 2nd row seat recliner";
CM_ SG_ 739 VCRIGHT_2RowSeatReclinePositionR "Reports the 2nd row seat recliner raw encoder count";
CM_ SG_ 739 VCRIGHT_2RowSeatReclineAngle "Reports the position of the 2nd row seat recliner in degrees";
CM_ SG_ 739 VCRIGHT_2RowSeatReclineAbsPosSwi "Reports the status of 2nd row seat recline absolute position (comfort zone) switch";
CM_ SG_ 739 VCRIGHT_2RowSeatReclinePositionS "Reports the active position state of the 2nd row seat recliner";
CM_ SG_ 739 VCRIGHT_2RowSeatReclineAdjustmen "Indicates whether adjustment requests are currently permitted for the rear seat recliner";
CM_ SG_ 739 VCRIGHT_2RowSeatReclineFoldAllow "Indicates whether auto-fold requests are currently permitted for the rear seat recliner";
CM_ SG_ 739 VCRIGHT_2RowSeatReclineUnfoldAll "Indicates whether auto-unfold requests are currently permitted for the rear seat recliner";
CM_ SG_ 739 VCRIGHT_2RowSeatReclineNextToggl "Right body controller: 2 row seat recline next toggle direction";
CM_ SG_ 739 VCRIGHT_2RowSeatReclineChoreoBlo "Right body controller: 2 row seat recline choreo blocked by occupancy";
CM_ SG_ 739 VCRIGHT_2RowSeat1RClashAvoidance "Right body controller: 2 row seat1 r clash avoidance blocked reason";
CM_ SG_ 739 VCRIGHT_2RowSeat1RClashAvoi_0001 "Right body controller: 2 row seat1 r clash avoidance state";
CM_ SG_ 739 VCRIGHT_2RowSeatReclineAbsP_0001 "Right body controller: 2 row seat recline abs pos switch trans point";
CM_ BO_ 835 "Right body controller message: status";
CM_ SG_ 835 VCRIGHT_LVBatteryTypeDBG "Right body controller: LV battery type DBG";
CM_ SG_ 835 VCRIGHT_rearDefrostState "Right body controller: rear defrost state";
CM_ SG_ 835 VCRIGHT_mirrorHeatState "Right body controller: mirror heat state";
CM_ SG_ 835 VCRIGHT_OTAState "Right body controller: OTA state";
CM_ SG_ 835 VCRIGHT_5AVoltage "Right body controller: 5 a voltage";
CM_ SG_ 835 VCRIGHT_vbatProt "Input voltage monitor to controller";
CM_ SG_ 835 VCRIGHT_rationalityAggregateCurr "Right body controller: rationality aggregate current";
CM_ SG_ 835 VCRIGHT_eFuseMgmtVoltageMonitor "Right body controller: e fuse mgmt voltage monitor";
CM_ SG_ 835 VCRIGHT_isSteeringWheelHeaterReq "Right body controller: is steering wheel heater req";
CM_ SG_ 835 VCRIGHT_steeringWheelHeaterDCTgt "Right body controller: steering wheel heater DC tgt";
CM_ BO_ 963 "Right body controller message: switch status";
CM_ SG_ 963 VCRIGHT_switchStatusIndex "Right body controller: switch status index";
CM_ SG_ 963 VCRIGHT_trunkExtReleasePressedPe "Right body controller: trunk ext release pressed persist";
CM_ SG_ 963 VCRIGHT_frontSeatTrackBack "Right body controller: front seat track back";
CM_ SG_ 963 VCRIGHT_frontSeatTrackForward "Right body controller: front seat track forward";
CM_ SG_ 963 VCRIGHT_frontSeatTiltDown "Right body controller: front seat tilt down";
CM_ SG_ 963 VCRIGHT_frontSeatTiltUp "Right body controller: front seat tilt up";
CM_ SG_ 963 VCRIGHT_frontSeatLiftDown "Right body controller: front seat lift down";
CM_ SG_ 963 VCRIGHT_frontSeatLiftUp "Right body controller: front seat lift up";
CM_ SG_ 963 VCRIGHT_frontSeatBackrestBack "Right body controller: front seat backrest back";
CM_ SG_ 963 VCRIGHT_frontSeatBackrestForward "Right body controller: front seat backrest forward";
CM_ SG_ 963 VCRIGHT_frontSeatLumbarDown "Right body controller: front seat lumbar down";
CM_ SG_ 963 VCRIGHT_frontSeatLumbarUp "Right body controller: front seat lumbar up";
CM_ SG_ 963 VCRIGHT_frontSeatLumbarIn "Right body controller: front seat lumbar in";
CM_ SG_ 963 VCRIGHT_frontSeatLumbarOut "Right body controller: front seat lumbar out";
CM_ SG_ 963 VCRIGHT_2RowSeatReclineSwitch "Second row seat recline switch";
CM_ SG_ 963 VCRIGHT_2RowSeatBackrestFoldSwit "Second row seat backrest fold switch";
CM_ SG_ 963 VCRIGHT_frontHandlePWM "Right body controller: front handle PWM";
CM_ SG_ 963 VCRIGHT_rearHandlePWM "Right body controller: rear handle PWM";
CM_ SG_ 963 VCRIGHT_gloveboxLightCurrent "Current through the glovebox LED";
CM_ SG_ 963 VCRIGHT_frontSeatALR "Front right seat automatic locking retractor switch";
CM_ SG_ 963 VCRIGHT_frontSeatResistiveOccupa "Front right seat occupancy status";
CM_ SG_ 963 VCRIGHT_2RowSeatReclineSwitchpac "State of the right second row powered recline adjustment switchpack";
CM_ BO_ 899 "Right body controller message: ths status";
CM_ SG_ 899 VCRIGHT_thsActive "Right body controller: ths active";
CM_ SG_ 899 VCRIGHT_thsTemperature "Tesla HVAC sensor temperature";
CM_ SG_ 899 VCRIGHT_thsState "Right body controller: ths state";
CM_ SG_ 899 VCRIGHT_thsLINCurrentSchedule "Right body controller: ths LIN current schedule";
CM_ SG_ 899 VCRIGHT_thsDetected "Tesla HVAC sensor connection is detected";
CM_ SG_ 899 VCRIGHT_thsHumidity "Tesla HVAC sensor humidity";
CM_ SG_ 899 VCRIGHT_estimatedVehicleSituatio "Right body controller: estimated vehicle situation";
CM_ SG_ 899 VCRIGHT_thsSolarLoadInfrared "Solar power hitting the vehicle in the infrared spectrum.";
CM_ SG_ 899 VCRIGHT_thsSolarLoadVisible "Solar power hitting the vehicle in the visible spectrum.";
CM_ SG_ 899 VCRIGHT_estimatedThsSolarLoad "Right body controller: estimated ths solar load";
CM_ SG_ 899 VCRIGHT_hvacFastLoggingEnabled "Right body controller: hvac fast logging enabled";
CM_ BO_ 1059 "Right body controller message: veh nm";
CM_ SG_ 1059 VCRIGHT_nmGoingToSleep "Right body controller: nm going to sleep";
CM_ SG_ 1059 VCRIGHT_nmWakeUpBus "Right body controller: nm wake up bus";
CM_ SG_ 1059 VCRIGHT_nmKeepAwakeReason "Reason controller is preventing the vehicle from sleeping";
CM_ SG_ 1059 VCRIGHT_nmWakeUpReason "Right body controller: nm wake up reason";
CM_ SG_ 1059 VCRIGHT_nmDebugWakeUp "Right body controller: nm debug wake up";
CM_ SG_ 1059 VCRIGHT_nmEthKeepAwakeReason "Right body controller: nm eth keep awake reason";
CM_ SG_ 1059 VCRIGHT_nmChKeepAwakeReason "Right body controller: nm ch keep awake reason";
CM_ BO_ 707 "Right body controller message: window status";
CM_ SG_ 707 VCRIGHT_windowStatusIndex "Right body controller: window status index";
CM_ SG_ 707 VCRIGHT_windowStateRF "Status of right front window motor";
CM_ SG_ 707 VCRIGHT_windowTrimClearMoveReque "Reports a request for whether windows should enter or exit trim clear mode. Signal is only valid if Vehicle Controller Left (VCLEFT) is on driver side.";
CM_ SG_ 707 VCRIGHT_windowDutyRF "Right body controller: window duty RF";
CM_ SG_ 707 VCRIGHT_windowTrimClearActiveReq "Reports whether window trim clear is active. Signal is only valid if Vehicle Controller Left (VCLEFT) is on driver side.";
CM_ SG_ 707 VCRIGHT_windowCurrentRF "Current drawn by left front window regulator";
CM_ SG_ 707 VCRIGHT_windowPositionRF "Right body controller: window position RF";
CM_ SG_ 707 VCRIGHT_windowCalibratedRF "Calibration status of right front window motor";
CM_ SG_ 707 VCRIGHT_windowStateRR "Status of right rear window motor";
CM_ SG_ 707 VCRIGHT_windowDutyRR "Right body controller: window duty RR";
CM_ SG_ 707 VCRIGHT_windowCurrentRR "Current drawn by left rear window regulator";
CM_ SG_ 707 VCRIGHT_windowPositionRR "Right body controller: window position RR";
CM_ SG_ 707 VCRIGHT_windowCalibratedRR "Calibration status of right rear window motor";
CM_ SG_ 707 VCRIGHT_windowThermalTCRF "Right body controller: window thermal TCRF";
CM_ SG_ 707 VCRIGHT_windowThermalModeRF "Right body controller: window thermal mode RF";
CM_ SG_ 707 VCRIGHT_windowStopReasonRF "Reason for right front window stopping motion";
CM_ SG_ 707 VCRIGHT_windowStopReqReasonRF "Reason for right front window stopping motion";
CM_ SG_ 707 VCRIGHT_windowThermalTCRR "Right body controller: window thermal TCRR";
CM_ SG_ 707 VCRIGHT_windowThermalModeRR "Right body controller: window thermal mode RR";
CM_ SG_ 707 VCRIGHT_windowStopReasonRR "Reason for right rear window stopping motion";
CM_ SG_ 707 VCRIGHT_windowStopReqReasonRR "Reason for right rear window stopping motion";
CM_ SG_ 707 VCRIGHT_windowControlStateRF "Window control state";
CM_ SG_ 707 VCRIGHT_windowCtrlUnavailableRF "Window control unavailable reason";
CM_ SG_ 707 VCRIGHT_windowControlStateRR "Window control state";
CM_ SG_ 707 VCRIGHT_windowCtrlUnavailableRR "Window control unavailable reason";
CM_ SG_ 707 VCRIGHT_windowPositionStateRF "Reports the window position state";
CM_ SG_ 707 VCRIGHT_windowPositionStateRR "Window position state";
CM_ SG_ 707 VCRIGHT_windowVehGearStateRF "Window's interpretation of vehicle gear state";
CM_ SG_ 707 VCRIGHT_windowVehGearStateRR "Window's interpretation of vehicle gear state";
CM_ SG_ 707 VCRIGHT_windowSpeedTableStatusRF "Speed table build status of right front window";
CM_ SG_ 707 VCRIGHT_windowSpeedTableStatusRR "Speed table build status of right rear window";
BA_DEF_ BO_ "GenMsgCycleTime" INT 0 3600000;
BA_DEF_ BO_ "GenMsgSendType" ENUM "Cyclic","NotUsed","NotUsed","NotUsed","NotUsed","NotUsed","NotUsed","IfActive","NoMsgSendType","NotUsed";
BA_DEF_ BO_ "VFrameFormat" ENUM "StandardCAN","ExtendedCAN","reserved","J1939PG","reserved","reserved","reserved","reserved","reserved","reserved","reserved","reserved","reserved","reserved","StandardCAN_FD","ExtendedCAN_FD";
BA_DEF_ BO_ "CANFD_BRS" ENUM "0","1";
BA_DEF_ SG_ "SystemSignalLongSymbol" STRING;
BA_DEF_ SG_ "Confidence" ENUM "layout-only","plausible","validated";
BA_DEF_DEF_ "GenMsgCycleTime" 0;
BA_DEF_DEF_ "GenMsgSendType" "NoMsgSendType";
BA_DEF_DEF_ "VFrameFormat" "StandardCAN";
BA_DEF_DEF_ "CANFD_BRS" "1";
BA_DEF_DEF_ "SystemSignalLongSymbol" "";
BA_DEF_DEF_ "Confidence" "layout-only";
BA_ "Confidence" SG_ 259 VCRIGHT_doorClosureStatusFront 1;
BA_ "Confidence" SG_ 259 VCRIGHT_doorClosureStatusRear 1;
BA_ "Confidence" SG_ 259 VCRIGHT_frontLatchSwitch 1;
BA_ "Confidence" SG_ 259 VCRIGHT_rearLatchSwitch 1;
BA_ "Confidence" SG_ 259 VCRIGHT_frontRelActuatorSwitch 1;
BA_ "Confidence" SG_ 259 VCRIGHT_rearRelActuatorSwitch 1;
BA_ "Confidence" SG_ 259 VCRIGHT_frontLatchStatus 1;
BA_ "Confidence" SG_ 259 VCRIGHT_rearLatchStatus 1;
BA_ "Confidence" SG_ 259 VCRIGHT_lastDoorReqSourceFront 1;
BA_ "Confidence" SG_ 259 VCRIGHT_lastDoorReqSourceRear 1;
BA_ "Confidence" SG_ 259 VCRIGHT_mirrorTiltXPosition 1;
BA_ "Confidence" SG_ 259 VCRIGHT_mirrorTiltYPosition 1;
BA_ "Confidence" SG_ 259 VCRIGHT_mirrorState 1;
BA_ "Confidence" SG_ 259 VCRIGHT_mirrorFoldState 1;
BA_ "Confidence" SG_ 259 VCRIGHT_mirrorDipped 1;
BA_ "Confidence" SG_ 259 VCRIGHT_trunkLatchStatus 1;
BA_ "Confidence" SG_ 259 VCRIGHT_mirrorRecallState 1;
BA_ "Confidence" SG_ 2010 VCRIGHT_frontLatchRelDuty 1;
BA_ "Confidence" SG_ 2010 VCRIGHT_BPillarCameraHeaterState 1;
BA_ "Confidence" SG_ 2010 VCRIGHT_doorLatchAjarSwitchVolta 1;
BA_ "SystemSignalLongSymbol" SG_ 2010 VCRIGHT_doorLatchAjarSwitchVolta "VCRIGHT_doorLatchAjarSwitchVoltageF";
BA_ "Confidence" SG_ 2010 VCRIGHT_doorLatchAjarSwitch_0001 1;
BA_ "SystemSignalLongSymbol" SG_ 2010 VCRIGHT_doorLatchAjarSwitch_0001 "VCRIGHT_doorLatchAjarSwitchVoltageR";
BA_ "Confidence" SG_ 2010 VCRIGHT_BPillarCameraHeaterCurre 1;
BA_ "SystemSignalLongSymbol" SG_ 2010 VCRIGHT_BPillarCameraHeaterCurre "VCRIGHT_BPillarCameraHeaterCurrent";
BA_ "Confidence" SG_ 2010 VCRIGHT_mirrorTiltXOffset 1;
BA_ "Confidence" SG_ 2010 VCRIGHT_mirrorTiltYOffset 1;
BA_ "Confidence" SG_ 915 VCRIGHT_epbmCaliperState 1;
BA_ "Confidence" SG_ 915 VCRIGHT_epbMotorCurrent 1;
BA_ "Confidence" SG_ 915 VCRIGHT_epbmApplyVoltage 1;
BA_ "Confidence" SG_ 915 VCRIGHT_epbmReleaseVoltage 1;
BA_ "Confidence" SG_ 915 VCRIGHT_summonFaultReason 1;
BA_ "Confidence" SG_ 915 VCRIGHT_epbSummonState 1;
BA_ "Confidence" SG_ 915 VCRIGHT_epbmSummonState 1;
BA_ "Confidence" SG_ 915 VCRIGHT_epbUnitStatus 1;
BA_ "Confidence" SG_ 915 VCRIGHT_epbmFaultStatus 1;
BA_ "Confidence" SG_ 915 VCRIGHT_epbFaultStatus 1;
BA_ "Confidence" SG_ 915 VCRIGHT_epbmSystemStatus 1;
BA_ "Confidence" SG_ 1123 VCRIGHT_cdpRequestState 1;
BA_ "Confidence" SG_ 1123 VCRIGHT_epbmSystemStatusQF 1;
BA_ "Confidence" SG_ 1123 VCRIGHT_epbmUnitStatus 1;
BA_ "Confidence" SG_ 1123 VCRIGHT_epbmCdpState 1;
BA_ "Confidence" SG_ 524 VCRIGHT_wattsDemandEvap 1;
BA_ "Confidence" SG_ 524 VCRIGHT_tempEvaporator 1;
BA_ "Confidence" SG_ 524 VCRIGHT_tempEvaporatorTarget 1;
BA_ "Confidence" SG_ 524 VCRIGHT_hvacBlowerSpeedRPMReq 1;
BA_ "Confidence" SG_ 524 VCRIGHT_tempAmbientRaw 1;
BA_ "Confidence" SG_ 524 VCRIGHT_hvacPerfTestState 1;
BA_ "Confidence" SG_ 524 VCRIGHT_hvacBlowerRPMActualAP 1;
BA_ "SystemSignalLongSymbol" SG_ 524 VCRIGHT_hvacEvapEnabledInColdAmb "VCRIGHT_hvacEvapEnabledInColdAmbient";
BA_ "Confidence" SG_ 579 VCRIGHT_childModeHVACState 1;
BA_ "Confidence" SG_ 579 VCRIGHT_dogModeState 1;
BA_ "Confidence" SG_ 579 VCRIGHT_COPNotRunningReasonFilte 1;
BA_ "SystemSignalLongSymbol" SG_ 579 VCRIGHT_COPNotRunningReasonFilte "VCRIGHT_COPNotRunningReasonFiltered";
BA_ "Confidence" SG_ 579 VCRIGHT_hvacCabinTempEst 1;
BA_ "Confidence" SG_ 579 VCRIGHT_hvacAirDistributionMode 1;
BA_ "Confidence" SG_ 579 VCRIGHT_hvacBlowerSegment 1;
BA_ "Confidence" SG_ 579 VCRIGHT_hvacRecirc 1;
BA_ "Confidence" SG_ 579 VCRIGHT_hvacACRunning 1;
BA_ "Confidence" SG_ 579 VCRIGHT_hvacPowerState 1;
BA_ "Confidence" SG_ 579 VCRIGHT_hvacVentStatus 1;
BA_ "Confidence" SG_ 579 VCRIGHT_hvacSecondRowState 1;
BA_ "Confidence" SG_ 579 VCRIGHT_hvacSystemNominal 1;
BA_ "Confidence" SG_ 579 VCRIGHT_hvacModelInitStatus 1;
BA_ "Confidence" SG_ 579 VCRIGHT_hvacMassflowRefrigSysRig 1;
BA_ "SystemSignalLongSymbol" SG_ 579 VCRIGHT_hvacMassflowRefrigSysRig "VCRIGHT_hvacMassflowRefrigSysRight";
BA_ "Confidence" SG_ 579 VCRIGHT_hvacRecircDoorPercent 1;
BA_ "Confidence" SG_ 579 VCRIGHT_tempDuctLeft 1;
BA_ "Confidence" SG_ 579 VCRIGHT_hvacMassflowRefrigSystem 1;
BA_ "Confidence" SG_ 579 VCRIGHT_tempDuctRight 1;
BA_ "Confidence" SG_ 579 VCRIGHT_hvacMassflowRefrigSysLef 1;
BA_ "SystemSignalLongSymbol" SG_ 579 VCRIGHT_hvacMassflowRefrigSysLef "VCRIGHT_hvacMassflowRefrigSysLeft";
BA_ "Confidence" SG_ 579 VCRIGHT_hvacDuctTargetLeft 1;
BA_ "Confidence" SG_ 579 VCRIGHT_hvacDuctTargetRight 1;
BA_ "SystemSignalLongSymbol" SG_ 579 VCRIGHT_enableTripleCameraFanPow "VCRIGHT_enableTripleCameraFanPowerInSleep";
BA_ "Confidence" SG_ 579 VCRIGHT_tempDuctRightUpper 1;
BA_ "Confidence" SG_ 579 VCRIGHT_hvacEvapInletTempEstimat 1;
BA_ "SystemSignalLongSymbol" SG_ 579 VCRIGHT_hvacEvapInletTempEstimat "VCRIGHT_hvacEvapInletTempEstimate";
BA_ "Confidence" SG_ 579 VCRIGHT_hvacCabinAtTempTarget 1;
BA_ "Confidence" SG_ 579 VCRIGHT_hvacAirflowReason 1;
BA_ "Confidence" SG_ 579 VCRIGHT_autoHvacBlowerShouldLimi 1;
BA_ "SystemSignalLongSymbol" SG_ 579 VCRIGHT_autoHvacBlowerShouldLimi "VCRIGHT_autoHvacBlowerShouldLimit";
BA_ "Confidence" SG_ 579 VCRIGHT_solarLoadOnVehicle 1;
BA_ "Confidence" SG_ 579 VCRIGHT_refrigDistCommanded 1;
BA_ "Confidence" SG_ 579 VCRIGHT_hvacFrontRightSeatFanSta 1;
BA_ "SystemSignalLongSymbol" SG_ 579 VCRIGHT_hvacFrontRightSeatFanSta "VCRIGHT_hvacFrontRightSeatFanStatus";
BA_ "Confidence" SG_ 579 VCRIGHT_hvacFrontLeftSeatFanStat 1;
BA_ "SystemSignalLongSymbol" SG_ 579 VCRIGHT_hvacFrontLeftSeatFanStat "VCRIGHT_hvacFrontLeftSeatFanStatus";
BA_ "Confidence" SG_ 579 VCRIGHT_hvacFrontRightSeatHeatSt 1;
BA_ "SystemSignalLongSymbol" SG_ 579 VCRIGHT_hvacFrontRightSeatHeatSt "VCRIGHT_hvacFrontRightSeatHeatStatus";
BA_ "Confidence" SG_ 579 VCRIGHT_hvacSeatFrontLeftTempTar 1;
BA_ "SystemSignalLongSymbol" SG_ 579 VCRIGHT_hvacSeatFrontLeftTempTar "VCRIGHT_hvacSeatFrontLeftTempTarget";
BA_ "Confidence" SG_ 579 VCRIGHT_hvacManualToAutoNotify 1;
BA_ "Confidence" SG_ 579 VCRIGHT_hvacRequestsFullAuto 1;
BA_ "SystemSignalLongSymbol" SG_ 579 VCRIGHT_passengerPresentHvacCycl "VCRIGHT_passengerPresentHvacCycle";
BA_ "Confidence" SG_ 579 VCRIGHT_hvacRequestsAutoIntake 1;
BA_ "Confidence" SG_ 579 VCRIGHT_steeringWheelHeatStatus 1;
BA_ "Confidence" SG_ 579 VCRIGHT_autoDefogStatus 1;
BA_ "Confidence" SG_ 579 VCRIGHT_solarElevation 1;
BA_ "Confidence" SG_ 579 VCRIGHT_minsToSunrise 1;
BA_ "Confidence" SG_ 579 VCRIGHT_minsToSunset 1;
BA_ "Confidence" SG_ 579 VCRIGHT_hvacLimitedReasonRight 1;
BA_ "Confidence" SG_ 579 VCRIGHT_hvacLimitedReasonLeft 1;
BA_ "Confidence" SG_ 579 VCRIGHT_hvacOverheatProtActive 1;
BA_ "Confidence" SG_ 579 VCRIGHT_tempDuctLeftUpper 1;
BA_ "Confidence" SG_ 579 VCRIGHT_hvacFrontLeftSeatHeatSta 1;
BA_ "SystemSignalLongSymbol" SG_ 579 VCRIGHT_hvacFrontLeftSeatHeatSta "VCRIGHT_hvacFrontLeftSeatHeatStatus";
BA_ "Confidence" SG_ 579 VCRIGHT_hvacQdotLeft 1;
BA_ "Confidence" SG_ 579 VCRIGHT_hvacQdotRight 1;
BA_ "Confidence" SG_ 579 VCRIGHT_tempDuctLeftLower 1;
BA_ "Confidence" SG_ 579 VCRIGHT_tempDuctRightLower 1;
BA_ "Confidence" SG_ 579 VCRIGHT_modeledCabinPressure 1;
BA_ "Confidence" SG_ 579 VCRIGHT_blowerTorqueIndex 1;
BA_ "Confidence" SG_ 579 VCRIGHT_autoSwingLeftPosX 1;
BA_ "Confidence" SG_ 579 VCRIGHT_autoSwingRightPositionX 1;
BA_ "Confidence" SG_ 1675 VCRIGHT_hvacSeat1RLCushionFanTrg 1;
BA_ "SystemSignalLongSymbol" SG_ 1675 VCRIGHT_hvacSeat1RLCushionFanTrg "VCRIGHT_hvacSeat1RLCushionFanTrgt";
BA_ "Confidence" SG_ 1675 VCRIGHT_hvacSeat1RLBackrestFanTr 1;
BA_ "SystemSignalLongSymbol" SG_ 1675 VCRIGHT_hvacSeat1RLBackrestFanTr "VCRIGHT_hvacSeat1RLBackrestFanTrgt";
BA_ "Confidence" SG_ 1675 VCRIGHT_hvacSeat1RRCushionFanTrg 1;
BA_ "SystemSignalLongSymbol" SG_ 1675 VCRIGHT_hvacSeat1RRCushionFanTrg "VCRIGHT_hvacSeat1RRCushionFanTrgt";
BA_ "Confidence" SG_ 1675 VCRIGHT_hvacSeat1RRBackrestFanTr 1;
BA_ "SystemSignalLongSymbol" SG_ 1675 VCRIGHT_hvacSeat1RRBackrestFanTr "VCRIGHT_hvacSeat1RRBackrestFanTrgt";
BA_ "Confidence" SG_ 1675 VCRIGHT_hvac2RLeftLateralTarget 1;
BA_ "Confidence" SG_ 1675 VCRIGHT_hvac2RLeftVerticalTarget 1;
BA_ "Confidence" SG_ 1675 VCRIGHT_hvac2RRightLateralTarget 1;
BA_ "Confidence" SG_ 1675 VCRIGHT_hvac2RRightVerticalTarge 1;
BA_ "SystemSignalLongSymbol" SG_ 1675 VCRIGHT_hvac2RRightVerticalTarge "VCRIGHT_hvac2RRightVerticalTarget";
BA_ "Confidence" SG_ 774 VCRIGHT_infoBuildType 1;
BA_ "Confidence" SG_ 995 VCRIGHT_brakeLightStatus 1;
BA_ "Confidence" SG_ 995 VCRIGHT_tailLightStatus 1;
BA_ "Confidence" SG_ 995 VCRIGHT_turnSignalStatus 1;
BA_ "Confidence" SG_ 995 VCRIGHT_reverseLightStatus 1;
BA_ "Confidence" SG_ 995 VCRIGHT_rearFogLightStatus 1;
BA_ "SystemSignalLongSymbol" SG_ 995 VCRIGHT_leftInteriorTrunkLightRe "VCRIGHT_leftInteriorTrunkLightReq";
BA_ "SystemSignalLongSymbol" SG_ 995 VCRIGHT_audioCurrentSpikeDetecte "VCRIGHT_audioCurrentSpikeDetected";
BA_ "Confidence" SG_ 995 VCRIGHT_fasciaReverseLightStatus 1;
BA_ "Confidence" SG_ 995 VCRIGHT_fasciaRearFogStatus 1;
BA_ "Confidence" SG_ 995 VCRIGHT_fasciaTailLightStatus 1;
BA_ "Confidence" SG_ 995 VCRIGHT_fasciaLeftTurnSignalStat 1;
BA_ "SystemSignalLongSymbol" SG_ 995 VCRIGHT_fasciaLeftTurnSignalStat "VCRIGHT_fasciaLeftTurnSignalStatus";
BA_ "Confidence" SG_ 995 VCRIGHT_fasciaRightTurnSignalSta 1;
BA_ "SystemSignalLongSymbol" SG_ 995 VCRIGHT_fasciaRightTurnSignalSta "VCRIGHT_fasciaRightTurnSignalStatus";
BA_ "Confidence" SG_ 995 VCRIGHT_CHMSLLightStatus 1;
BA_ "Confidence" SG_ 1803 VCRIGHT_cabinAirFilterLifeRemain 1;
BA_ "SystemSignalLongSymbol" SG_ 1803 VCRIGHT_cabinAirFilterLifeRemain "VCRIGHT_cabinAirFilterLifeRemaining";
BA_ "Confidence" SG_ 1803 VCRIGHT_HEPAAirFilterLifeRemaini 1;
BA_ "SystemSignalLongSymbol" SG_ 1803 VCRIGHT_HEPAAirFilterLifeRemaini "VCRIGHT_HEPAAirFilterLifeRemaining";
BA_ "Confidence" SG_ 1803 VCRIGHT_leftPTCCompromisedRod 1;
BA_ "Confidence" SG_ 1803 VCRIGHT_rightPTCCompromisedRod 1;
BA_ "Confidence" SG_ 1803 VCRIGHT_hepaFilterHealthScore 1;
BA_ "Confidence" SG_ 1803 VCRIGHT_cabinFilterHealthScore 1;
BA_ "Confidence" SG_ 1803 VCRIGHT_cabinTempBreathLevelFOff 1;
BA_ "Confidence" SG_ 1803 VCRIGHT_airDistributionModeAdjus 1;
BA_ "SystemSignalLongSymbol" SG_ 1803 VCRIGHT_airDistributionModeAdjus "VCRIGHT_airDistributionModeAdjustmentFactor";
BA_ "Confidence" SG_ 1803 VCRIGHT_hvacLHBleedEndStop 1;
BA_ "Confidence" SG_ 1803 VCRIGHT_hvacRHBleedEndStop 1;
BA_ "Confidence" SG_ 1803 VCRIGHT_hvacLHVaneEndStop 1;
BA_ "Confidence" SG_ 1803 VCRIGHT_hvacRHVaneEndStop 1;
BA_ "Confidence" SG_ 1803 VCRIGHT_hvacUpperModeEndStop 1;
BA_ "Confidence" SG_ 1803 VCRIGHT_hvacLowerModeEndStop 1;
BA_ "Confidence" SG_ 1803 VCRIGHT_hvacIntakeEndStop 1;
BA_ "Confidence" SG_ 1803 VCRIGHT_hvacLHBleedZeroStop 1;
BA_ "Confidence" SG_ 1803 VCRIGHT_hvacRHBleedZeroStop 1;
BA_ "Confidence" SG_ 1803 VCRIGHT_hvacLHVaneZeroStop 1;
BA_ "Confidence" SG_ 1803 VCRIGHT_hvacRHVaneZeroStop 1;
BA_ "Confidence" SG_ 1803 VCRIGHT_hvacUpperModeZeroStop 1;
BA_ "Confidence" SG_ 1803 VCRIGHT_hvacLowerModeZeroStop 1;
BA_ "Confidence" SG_ 1803 VCRIGHT_hvacIntakeZeroStop 1;
BA_ "Confidence" SG_ 1803 VCRIGHT_ambientTempLimp 1;
BA_ "Confidence" SG_ 1803 VCRIGHT_cabinProbeTempLimp 1;
BA_ "Confidence" SG_ 1803 VCRIGHT_thsTempLimp 1;
BA_ "Confidence" SG_ 1803 VCRIGHT_thsCabinWaterMassLimp 1;
BA_ "Confidence" SG_ 1803 VCRIGHT_thsSolarIrradianceLimp 1;
BA_ "Confidence" SG_ 1803 VCRIGHT_silentWakeRecordCount 1;
BA_ "Confidence" SG_ 1803 VCRIGHT_evapCondensateMass 1;
BA_ "Confidence" SG_ 1803 VCRIGHT_airwaveRightLateralTotal 1;
BA_ "SystemSignalLongSymbol" SG_ 1803 VCRIGHT_airwaveRightLateralTotal "VCRIGHT_airwaveRightLateralTotalTravel";
BA_ "Confidence" SG_ 1803 VCRIGHT_airwaveLeftLateralTotalT 1;
BA_ "SystemSignalLongSymbol" SG_ 1803 VCRIGHT_airwaveLeftLateralTotalT "VCRIGHT_airwaveLeftLateralTotalTravel";
BA_ "Confidence" SG_ 611 VCRIGHT_hvacLHBleedTarget 1;
BA_ "Confidence" SG_ 611 VCRIGHT_hvacRHBleedTarget 1;
BA_ "Confidence" SG_ 611 VCRIGHT_hvacLHVaneTarget 1;
BA_ "Confidence" SG_ 611 VCRIGHT_hvacRHVaneTarget 1;
BA_ "Confidence" SG_ 611 VCRIGHT_hvacUpperModeTarget 1;
BA_ "Confidence" SG_ 611 VCRIGHT_hvacLowerModeTarget 1;
BA_ "Confidence" SG_ 611 VCRIGHT_hvacIntakeTarget 1;
BA_ "Confidence" SG_ 611 VCRIGHT_hvacLHBleedPosition 1;
BA_ "Confidence" SG_ 611 VCRIGHT_hvacRHBleedPosition 1;
BA_ "Confidence" SG_ 611 VCRIGHT_hvacLHVanePosition 1;
BA_ "Confidence" SG_ 611 VCRIGHT_hvacRHVanePosition 1;
BA_ "Confidence" SG_ 611 VCRIGHT_hvacUpperModePosition 1;
BA_ "Confidence" SG_ 611 VCRIGHT_hvacLowerModePosition 1;
BA_ "Confidence" SG_ 611 VCRIGHT_hvacIntakePosition 1;
BA_ "Confidence" SG_ 611 VCRIGHT_hvacLHBleedActuatorState 1;
BA_ "Confidence" SG_ 611 VCRIGHT_hvacRHBleedActuatorState 1;
BA_ "Confidence" SG_ 611 VCRIGHT_hvacLHVaneActuatorState 1;
BA_ "Confidence" SG_ 611 VCRIGHT_hvacRHVaneActuatorState 1;
BA_ "Confidence" SG_ 611 VCRIGHT_hvacUpperModeActState 1;
BA_ "Confidence" SG_ 611 VCRIGHT_hvacLowerModeActState 1;
BA_ "Confidence" SG_ 611 VCRIGHT_hvacIntakeActuatorState 1;
BA_ "Confidence" SG_ 611 VCRIGHT_EvapPulldownBiasActive 1;
BA_ "Confidence" SG_ 611 VCRIGHT_tempDatLeftEst 1;
BA_ "Confidence" SG_ 611 VCRIGHT_tempDatRightEst 1;
BA_ "Confidence" SG_ 611 VCRIGHT_tempDuctLeftEst 1;
BA_ "Confidence" SG_ 611 VCRIGHT_tempDuctRightEst 1;
BA_ "Confidence" SG_ 611 VCRIGHT_ptcHeaterBadRodDetection 1;
BA_ "SystemSignalLongSymbol" SG_ 611 VCRIGHT_ptcHeaterBadRodDetection "VCRIGHT_ptcHeaterBadRodDetectionState";
BA_ "Confidence" SG_ 611 VCRIGHT_leftVerticalActuatorDuty 1;
BA_ "Confidence" SG_ 611 VCRIGHT_leftLateralActuatorDuty 1;
BA_ "Confidence" SG_ 611 VCRIGHT_rightVerticalActuatorDut 1;
BA_ "SystemSignalLongSymbol" SG_ 611 VCRIGHT_rightVerticalActuatorDut "VCRIGHT_rightVerticalActuatorDuty";
BA_ "Confidence" SG_ 611 VCRIGHT_rightLateralActuatorDuty 1;
BA_ "Confidence" SG_ 611 VCRIGHT_frontLeftSeatTempTargetQ 1;
BA_ "SystemSignalLongSymbol" SG_ 611 VCRIGHT_frontLeftSeatTempTargetQ "VCRIGHT_frontLeftSeatTempTargetQuasiSS";
BA_ "Confidence" SG_ 611 VCRIGHT_frontRightSeatTempTarget 1;
BA_ "SystemSignalLongSymbol" SG_ 611 VCRIGHT_frontRightSeatTempTarget "VCRIGHT_frontRightSeatTempTargetQuasiSS";
BA_ "Confidence" SG_ 691 VCRIGHT_tempIncarCabinProbe 1;
BA_ "Confidence" SG_ 691 VCRIGHT_tempIncarCabinDeep 1;
BA_ "Confidence" SG_ 691 VCRIGHT_cabinTempInteriorL2 1;
BA_ "Confidence" SG_ 691 VCRIGHT_tempIncarCabinMid 1;
BA_ "Confidence" SG_ 691 VCRIGHT_cabinTempInteriorSunnyL2 1;
BA_ "Confidence" SG_ 691 VCRIGHT_cabinTempInteriorL3 1;
BA_ "Confidence" SG_ 691 VCRIGHT_cabinTempInteriorSunnyL3 1;
BA_ "Confidence" SG_ 691 VCRIGHT_cabinTempGlassRoof 1;
BA_ "Confidence" SG_ 691 VCRIGHT_cabinTempWindshield 1;
BA_ "Confidence" SG_ 691 VCRIGHT_cabinTempInterior 1;
BA_ "Confidence" SG_ 691 VCRIGHT_cabinTempInteriorSunny 1;
BA_ "Confidence" SG_ 691 VCRIGHT_cabinTempSideGlassLeft 1;
BA_ "Confidence" SG_ 691 VCRIGHT_cabinTempSideGlassRight 1;
BA_ "Confidence" SG_ 691 VCRIGHT_cabinTempBreathLevel 1;
BA_ "Confidence" SG_ 691 VCRIGHT_pcbaTemperature 1;
BA_ "Confidence" SG_ 691 VCRIGHT_wattsHeaterLeftTotal 1;
BA_ "Confidence" SG_ 691 VCRIGHT_wattsHeaterRightTotal 1;
BA_ "Confidence" SG_ 691 VCRIGHT_qdotLeftFFUnsat 1;
BA_ "Confidence" SG_ 691 VCRIGHT_qdotRightFFUnsat 1;
BA_ "Confidence" SG_ 691 VCRIGHT_nvhLevelDb 1;
BA_ "Confidence" SG_ 691 VCRIGHT_hvacSetTempActualLeft 1;
BA_ "Confidence" SG_ 691 VCRIGHT_hvacSetTempActualRight 1;
BA_ "Confidence" SG_ 691 VCRIGHT_hvacAutoTransitionReason 1;
BA_ "Confidence" SG_ 691 VCRIGHT_hvacMassflowTarget 1;
BA_ "Confidence" SG_ 691 VCRIGHT_hvacFilterLifeDetectActi 1;
BA_ "SystemSignalLongSymbol" SG_ 691 VCRIGHT_hvacFilterLifeDetectActi "VCRIGHT_hvacFilterLifeDetectActive";
BA_ "Confidence" SG_ 691 VCRIGHT_hvacLHBleedOperationMode 1;
BA_ "Confidence" SG_ 691 VCRIGHT_hvacRHBleedOperationMode 1;
BA_ "Confidence" SG_ 691 VCRIGHT_hvacLHVaneOperationMode 1;
BA_ "Confidence" SG_ 691 VCRIGHT_hvacRHVaneOperationMode 1;
BA_ "Confidence" SG_ 691 VCRIGHT_hvacUpperModeOpMode 1;
BA_ "Confidence" SG_ 691 VCRIGHT_hvacLowerModeOpMode 1;
BA_ "Confidence" SG_ 691 VCRIGHT_hvacIntakeOperationMode 1;
BA_ "Confidence" SG_ 691 VCRIGHT_isProbeFeedbackApplied 1;
BA_ "Confidence" SG_ 691 VCRIGHT_feedbackPullDownScalar 1;
BA_ "Confidence" SG_ 691 VCRIGHT_feedForwardPullDownScala 1;
BA_ "SystemSignalLongSymbol" SG_ 691 VCRIGHT_feedForwardPullDownScala "VCRIGHT_feedForwardPullDownScalar";
BA_ "Confidence" SG_ 691 VCRIGHT_convectionTargetLeft 1;
BA_ "Confidence" SG_ 691 VCRIGHT_convectionTargetRight 1;
BA_ "Confidence" SG_ 691 VCRIGHT_convectionDeliveredLeft 1;
BA_ "Confidence" SG_ 691 VCRIGHT_convectionDeliveredRight 1;
BA_ "Confidence" SG_ 691 VCRIGHT_solarLoadRightOccupant 1;
BA_ "Confidence" SG_ 691 VCRIGHT_solarLoadLeftOccupant 1;
BA_ "SystemSignalLongSymbol" SG_ 691 VCRIGHT_ptcShutOutletMitigationA "VCRIGHT_ptcShutOutletMitigationActive";
BA_ "Confidence" SG_ 691 VCRIGHT_solarLoadFromThsTemp 1;
BA_ "SystemSignalLongSymbol" SG_ 691 VCRIGHT_ptcHeaterReqAirpathBlock "VCRIGHT_ptcHeaterReqAirpathBlocked";
BA_ "Confidence" SG_ 691 VCRIGHT_hvacQdotFeedforward 1;
BA_ "Confidence" SG_ 691 VCRIGHT_evapLoadInFresh 1;
BA_ "Confidence" SG_ 691 VCRIGHT_evapLoadInRecirc 1;
BA_ "Confidence" SG_ 691 VCRIGHT_cabinTempWshldDefog 1;
BA_ "Confidence" SG_ 691 VCRIGHT_cabinTempWshldDefogTop 1;
BA_ "Confidence" SG_ 691 VCRIGHT_hvacLHBleedVoltage 1;
BA_ "Confidence" SG_ 691 VCRIGHT_hvacRHBleedVoltage 1;
BA_ "Confidence" SG_ 691 VCRIGHT_hvacLHVaneVoltage 1;
BA_ "Confidence" SG_ 691 VCRIGHT_hvacRHVaneVoltage 1;
BA_ "Confidence" SG_ 691 VCRIGHT_hvacUpperModeVoltage 1;
BA_ "Confidence" SG_ 691 VCRIGHT_hvacLowerModeVoltage 1;
BA_ "Confidence" SG_ 691 VCRIGHT_hvacIntakeVoltage 1;
BA_ "Confidence" SG_ 691 VCRIGHT_cabinTempBreathLevelFHea 1;
BA_ "SystemSignalLongSymbol" SG_ 691 VCRIGHT_cabinTempBreathLevelFHea "VCRIGHT_cabinTempBreathLevelFHeating";
BA_ "Confidence" SG_ 691 VCRIGHT_cabinTempBreathLevelFCoo 1;
BA_ "SystemSignalLongSymbol" SG_ 691 VCRIGHT_cabinTempBreathLevelFCoo "VCRIGHT_cabinTempBreathLevelFCooling";
BA_ "Confidence" SG_ 691 VCRIGHT_cabinTempBreathLeve_0002 1;
BA_ "SystemSignalLongSymbol" SG_ 691 VCRIGHT_cabinTempBreathLeve_0002 "VCRIGHT_cabinTempBreathLevelF5minHeating";
BA_ "Confidence" SG_ 691 VCRIGHT_cabinTempBreathLevelF5mi 1;
BA_ "SystemSignalLongSymbol" SG_ 691 VCRIGHT_cabinTempBreathLevelF5mi "VCRIGHT_cabinTempBreathLevelF5minCooling";
BA_ "Confidence" SG_ 691 VCRIGHT_cabinTempBreathLeve_0001 1;
BA_ "SystemSignalLongSymbol" SG_ 691 VCRIGHT_cabinTempBreathLeve_0001 "VCRIGHT_cabinTempBreathLevelF10minHeating";
BA_ "Confidence" SG_ 691 VCRIGHT_cabinTempBreathLevelF10m 1;
BA_ "SystemSignalLongSymbol" SG_ 691 VCRIGHT_cabinTempBreathLevelF10m "VCRIGHT_cabinTempBreathLevelF10minCooling";
BA_ "Confidence" SG_ 691 VCRIGHT_cabinTempInteriorFHeatin 1;
BA_ "SystemSignalLongSymbol" SG_ 691 VCRIGHT_cabinTempInteriorFHeatin "VCRIGHT_cabinTempInteriorFHeating";
BA_ "Confidence" SG_ 691 VCRIGHT_hvacCabOvrheatProtActive 1;
BA_ "Confidence" SG_ 691 VCRIGHT_hvacCabOvrheatProtAllowe 1;
BA_ "SystemSignalLongSymbol" SG_ 691 VCRIGHT_hvacCabOvrheatProtAllowe "VCRIGHT_hvacCabOvrheatProtAllowed";
BA_ "Confidence" SG_ 691 VCRIGHT_filterLifeBlowerTorque 1;
BA_ "Confidence" SG_ 691 VCRIGHT_cabinTempFanCurrent 1;
BA_ "Confidence" SG_ 691 VCRIGHT_cloudinessEstimatedPct 1;
BA_ "Confidence" SG_ 691 VCRIGHT_solarLoadOnVehFiltered 1;
BA_ "Confidence" SG_ 691 VCRIGHT_cabinTempProbeEstimate 1;
BA_ "Confidence" SG_ 691 VCRIGHT_cabinTempThs 1;
BA_ "Confidence" SG_ 691 VCRIGHT_cabinTempThsBracket 1;
BA_ "Confidence" SG_ 691 VCRIGHT_CO2ppm 1;
BA_ "Confidence" SG_ 691 VCRIGHT_hvacEstimateWindshieldRH 1;
BA_ "Confidence" SG_ 691 VCRIGHT_hvacFoggingRiskLevel 1;
BA_ "Confidence" SG_ 691 VCRIGHT_hvacCabinHumidityLevel 1;
BA_ "Confidence" SG_ 691 VCRIGHT_hvacFlashFoggingDetected 1;
BA_ "Confidence" SG_ 691 VCRIGHT_solarSensitivityInfr 1;
BA_ "Confidence" SG_ 691 VCRIGHT_solarSensitivityInfrCorr 1;
BA_ "Confidence" SG_ 691 VCRIGHT_lumbarCurrent 1;
BA_ "Confidence" SG_ 691 VCRIGHT_ocsCurrent 1;
BA_ "Confidence" SG_ 691 VCRIGHT_rcmCurrent 1;
BA_ "Confidence" SG_ 691 VCRIGHT_radioTunerCurrent 1;
BA_ "Confidence" SG_ 691 VCRIGHT_rearOilPumpCurrent 1;
BA_ "Confidence" SG_ 691 VCRIGHT_rearDefrostCurrent 1;
BA_ "Confidence" SG_ 691 VCRIGHT_tailLightCurrent 1;
BA_ "Confidence" SG_ 691 VCRIGHT_turnTailStopLightCurrent 1;
BA_ "Confidence" SG_ 691 VCRIGHT_reverseFogLightsCurrent 1;
BA_ "Confidence" SG_ 691 VCRIGHT_stopReverseTurnLightCurr 1;
BA_ "SystemSignalLongSymbol" SG_ 691 VCRIGHT_stopReverseTurnLightCurr "VCRIGHT_stopReverseTurnLightCurrent";
BA_ "Confidence" SG_ 691 VCRIGHT_sideMirrorCurrent 1;
BA_ "Confidence" SG_ 691 VCRIGHT_sideMirrorHeaterCurrent 1;
BA_ "Confidence" SG_ 691 VCRIGHT_frontSeatHeatCushionPwr 1;
BA_ "Confidence" SG_ 691 VCRIGHT_trunkInteriorLEDCurrent 1;
BA_ "Confidence" SG_ 691 VCRIGHT_mapPocketLEDsCurrent 1;
BA_ "Confidence" SG_ 691 VCRIGHT_miscEFuseCurrent 1;
BA_ "Confidence" SG_ 691 VCRIGHT_interiorHandleLEDCurrent 1;
BA_ "Confidence" SG_ 691 VCRIGHT_miscInteriorLightsCurren 1;
BA_ "SystemSignalLongSymbol" SG_ 691 VCRIGHT_miscInteriorLightsCurren "VCRIGHT_miscInteriorLightsCurrent";
BA_ "Confidence" SG_ 691 VCRIGHT_frontPuddleLEDCurrent 1;
BA_ "Confidence" SG_ 691 VCRIGHT_rearPuddleLEDCurrent 1;
BA_ "Confidence" SG_ 691 VCRIGHT_liftgateShutfaceLEDCurre 1;
BA_ "SystemSignalLongSymbol" SG_ 691 VCRIGHT_liftgateShutfaceLEDCurre "VCRIGHT_liftgateShutfaceLEDCurrent";
BA_ "Confidence" SG_ 691 VCRIGHT_3rSeatTOSCurrent 1;
BA_ "Confidence" SG_ 691 VCRIGHT_vbatFusedCurrent 1;
BA_ "Confidence" SG_ 691 VCRIGHT_cabinTempGlassGridHeater 1;
BA_ "Confidence" SG_ 691 VCRIGHT_hvacAirflowReasonRight 1;
BA_ "Confidence" SG_ 691 VCRIGHT_hvacAirflowReasonLeft 1;
BA_ "Confidence" SG_ 691 VCRIGHT_hvacMassflowTargetLeft 1;
BA_ "Confidence" SG_ 691 VCRIGHT_hvacMassflowTargetRight 1;
BA_ "Confidence" SG_ 691 VCRIGHT_solarLoadLeftOccupantFil 1;
BA_ "SystemSignalLongSymbol" SG_ 691 VCRIGHT_solarLoadLeftOccupantFil "VCRIGHT_solarLoadLeftOccupantFilt";
BA_ "Confidence" SG_ 691 VCRIGHT_solarLoadRightOccupantFi 1;
BA_ "SystemSignalLongSymbol" SG_ 691 VCRIGHT_solarLoadRightOccupantFi "VCRIGHT_solarLoadRightOccupantFilt";
BA_ "Confidence" SG_ 691 VCRIGHT_windshieldRHCapped 1;
BA_ "Confidence" SG_ 691 VCRIGHT_feedbackWarmUpScalar 1;
BA_ "Confidence" SG_ 691 VCRIGHT_maxMassflowScalarWarmUp 1;
BA_ "Confidence" SG_ 691 VCRIGHT_feedforwardWarmUpScalar 1;
BA_ "Confidence" SG_ 691 VCRIGHT_frontSeatHeatBackrestPwr 1;
BA_ "Confidence" SG_ 691 VCRIGHT_maxMassflowScalar 1;
BA_ "Confidence" SG_ 691 VCRIGHT_massflowTargetAutoInManu 1;
BA_ "SystemSignalLongSymbol" SG_ 691 VCRIGHT_massflowTargetAutoInManu "VCRIGHT_massflowTargetAutoInManualMode";
BA_ "Confidence" SG_ 691 VCRIGHT_airflowReasonAutoInManua 1;
BA_ "SystemSignalLongSymbol" SG_ 691 VCRIGHT_airflowReasonAutoInManua "VCRIGHT_airflowReasonAutoInManualMode";
BA_ "Confidence" SG_ 691 VCRIGHT_airflowReasonAutoIn_0001 1;
BA_ "SystemSignalLongSymbol" SG_ 691 VCRIGHT_airflowReasonAutoIn_0001 "VCRIGHT_airflowReasonAutoInManualModeLeft";
BA_ "Confidence" SG_ 691 VCRIGHT_airflowReasonAutoIn_0002 1;
BA_ "SystemSignalLongSymbol" SG_ 691 VCRIGHT_airflowReasonAutoIn_0002 "VCRIGHT_airflowReasonAutoInManualModeRight";
BA_ "Confidence" SG_ 691 VCRIGHT_cabinTempInteriorFCoolin 1;
BA_ "SystemSignalLongSymbol" SG_ 691 VCRIGHT_cabinTempInteriorFCoolin "VCRIGHT_cabinTempInteriorFCooling";
BA_ "Confidence" SG_ 691 VCRIGHT_averageDuctTempFHeating 1;
BA_ "Confidence" SG_ 691 VCRIGHT_averageDuctTempFCooling 1;
BA_ "Confidence" SG_ 691 VCRIGHT_hvacBiLevelWhsldRhEst 1;
BA_ "Confidence" SG_ 691 VCRIGHT_steeringWheelSurfaceTemp 1;
BA_ "SystemSignalLongSymbol" SG_ 691 VCRIGHT_steeringWheelSurfaceTemp "VCRIGHT_steeringWheelSurfaceTempEst";
BA_ "Confidence" SG_ 691 VCRIGHT_steeringWheelSurfac_0001 1;
BA_ "SystemSignalLongSymbol" SG_ 691 VCRIGHT_steeringWheelSurfac_0001 "VCRIGHT_steeringWheelSurfaceTempTgt";
BA_ "Confidence" SG_ 691 VCRIGHT_timeToComfortHeating 1;
BA_ "Confidence" SG_ 691 VCRIGHT_timeToComfortCooling 1;
BA_ "Confidence" SG_ 691 VCRIGHT_cabinWaterMassRaw 1;
BA_ "Confidence" SG_ 691 VCRIGHT_massflowSingleZoneSplit 1;
BA_ "Confidence" SG_ 691 VCRIGHT_VOCPurgeState 1;
BA_ "Confidence" SG_ 691 VCRIGHT_cameraFoggingMonitorStat 1;
BA_ "SystemSignalLongSymbol" SG_ 691 VCRIGHT_cameraFoggingMonitorStat "VCRIGHT_cameraFoggingMonitorState";
BA_ "Confidence" SG_ 691 VCRIGHT_cabinOverheatProtectNotR 1;
BA_ "SystemSignalLongSymbol" SG_ 691 VCRIGHT_cabinOverheatProtectNotR "VCRIGHT_cabinOverheatProtectNotRunningReasonRaw";
BA_ "Confidence" SG_ 691 VCRIGHT_hvacIntakeReason 1;
BA_ "Confidence" SG_ 691 VCRIGHT_hvacCabinPurgeActive 1;
BA_ "Confidence" SG_ 691 VCRIGHT_solarAzimuthCarRef 1;
BA_ "Confidence" SG_ 691 VCRIGHT_massflowPulldownBias 1;
BA_ "Confidence" SG_ 691 VCRIGHT_evapPulldownBias 1;
BA_ "Confidence" SG_ 691 VCRIGHT_modeledMassflowFresh 1;
BA_ "Confidence" SG_ 691 VCRIGHT_modeledMassflowRecirc 1;
BA_ "Confidence" SG_ 691 VCRIGHT_hvacLimpModeStatus 1;
BA_ "Confidence" SG_ 691 VCRIGHT_hvacEstimatedCameraWinds 1;
BA_ "SystemSignalLongSymbol" SG_ 691 VCRIGHT_hvacEstimatedCameraWinds "VCRIGHT_hvacEstimatedCameraWindshieldRH";
BA_ "Confidence" SG_ 1859 VCRIGHT_systemRecallStatus 1;
BA_ "Confidence" SG_ 1859 VCRIGHT_seatRecallStatus 1;
BA_ "Confidence" SG_ 1859 VCRIGHT_mirrorRecallStatus 1;
BA_ "Confidence" SG_ 1862 VCRIGHT_frontOccupancyStatus 1;
BA_ "Confidence" SG_ 1862 VCRIGHT_frontBuckleStatus 1;
BA_ "Confidence" SG_ 1862 VCRIGHT_rearCenterBuckleStatus 1;
BA_ "Confidence" SG_ 1862 VCRIGHT_rearRightBuckleStatus 1;
BA_ "Confidence" SG_ 1862 VCRIGHT_rearRightOccupancyStatus 1;
BA_ "Confidence" SG_ 1862 VCRIGHT_3RowLeftBuckleStatus 1;
BA_ "Confidence" SG_ 1862 VCRIGHT_3RowRightBuckleStatus 1;
BA_ "Confidence" SG_ 1862 VCRIGHT_3RowLeftOccupancyStatus 1;
BA_ "Confidence" SG_ 1862 VCRIGHT_3RowRightOccupancyStatus 1;
BA_ "Confidence" SG_ 1862 VCRIGHT_seatTrackPosition 1;
BA_ "Confidence" SG_ 1862 VCRIGHT_occupantClassification 1;
BA_ "Confidence" SG_ 1862 VCRIGHT_occupantClassificationQF 1;
BA_ "Confidence" SG_ 1862 VCRIGHT_classificationEnabled 1;
BA_ "Confidence" SG_ 1862 VCRIGHT_classificationEnabledQF 1;
BA_ "Confidence" SG_ 1251 VCRIGHT_frontSeatTrackPos 1;
BA_ "Confidence" SG_ 1251 VCRIGHT_frontSeatTrackCurrent 1;
BA_ "Confidence" SG_ 1251 VCRIGHT_frontSeatTrackDuty 1;
BA_ "Confidence" SG_ 1251 VCRIGHT_frontSeatTrackState 1;
BA_ "Confidence" SG_ 1251 VCRIGHT_frontSeatTrackBridgeSt 1;
BA_ "Confidence" SG_ 1251 VCRIGHT_frontSeatBackPos 1;
BA_ "Confidence" SG_ 1251 VCRIGHT_frontSeatBackCurrent 1;
BA_ "Confidence" SG_ 1251 VCRIGHT_frontSeatBackDuty 1;
BA_ "Confidence" SG_ 1251 VCRIGHT_frontSeatBackState 1;
BA_ "Confidence" SG_ 1251 VCRIGHT_frontSeatBackBridgeSt 1;
BA_ "Confidence" SG_ 1251 VCRIGHT_frontSeatLiftPos 1;
BA_ "Confidence" SG_ 1251 VCRIGHT_frontSeatLiftCurrent 1;
BA_ "Confidence" SG_ 1251 VCRIGHT_frontSeatLiftDuty 1;
BA_ "Confidence" SG_ 1251 VCRIGHT_frontSeatLiftState 1;
BA_ "Confidence" SG_ 1251 VCRIGHT_frontSeatLiftBridgeSt 1;
BA_ "Confidence" SG_ 1251 VCRIGHT_frontSeatTiltPos 1;
BA_ "Confidence" SG_ 1251 VCRIGHT_frontSeatTiltCurrent 1;
BA_ "Confidence" SG_ 1251 VCRIGHT_frontSeatTiltDuty 1;
BA_ "Confidence" SG_ 1251 VCRIGHT_frontSeatTiltState 1;
BA_ "Confidence" SG_ 1251 VCRIGHT_frontSeatTiltBridgeSt 1;
BA_ "Confidence" SG_ 1251 VCRIGHT_lumbarAState 1;
BA_ "Confidence" SG_ 1251 VCRIGHT_lumbarBState 1;
BA_ "Confidence" SG_ 1251 VCRIGHT_lumbarAPressureHpaFilt 1;
BA_ "Confidence" SG_ 1251 VCRIGHT_lumbarBPressureHpaFilt 1;
BA_ "Confidence" SG_ 1251 VCRIGHT_lumbarActiveTooLongErr 1;
BA_ "Confidence" SG_ 1251 VCRIGHT_lumbarMaxPErr 1;
BA_ "Confidence" SG_ 1251 VCRIGHT_lumbarOvercurrentErr 1;
BA_ "Confidence" SG_ 1251 VCRIGHT_lumbarMaxOperatingPErr 1;
BA_ "Confidence" SG_ 1251 VCRIGHT_lumbarMinPErr 1;
BA_ "Confidence" SG_ 1251 VCRIGHT_lumbarGeneralErr 1;
BA_ "Confidence" SG_ 1251 VCRIGHT_lumbarDevMaxPumpPressA 1;
BA_ "Confidence" SG_ 1251 VCRIGHT_lumbarDevMaxPumpPressB 1;
BA_ "Confidence" SG_ 1251 VCRIGHT_frontSeatTrackPosReal 1;
BA_ "Confidence" SG_ 1251 VCRIGHT_frontSeatBackPosReal 1;
BA_ "Confidence" SG_ 1251 VCRIGHT_frontSeatLiftPosReal 1;
BA_ "Confidence" SG_ 1251 VCRIGHT_frontSeatTiltPosReal 1;
BA_ "Confidence" SG_ 1251 VCRIGHT_frontSeatTrackPosOffset 1;
BA_ "Confidence" SG_ 1251 VCRIGHT_frontSeatBackPosOffset 1;
BA_ "Confidence" SG_ 1251 VCRIGHT_frontSeatLiftPosOffset 1;
BA_ "Confidence" SG_ 1251 VCRIGHT_frontSeatTiltPosOffset 1;
BA_ "Confidence" SG_ 739 VCRIGHT_frontSeatHeatCurrent 1;
BA_ "Confidence" SG_ 739 VCRIGHT_frontSeatHeatDuty 1;
BA_ "Confidence" SG_ 739 VCRIGHT_frontSeatHeatTmp 1;
BA_ "Confidence" SG_ 739 VCRIGHT_frontSeatHeatTmpTarget 1;
BA_ "Confidence" SG_ 739 VCRIGHT_frontSeatHeatInhibited 1;
BA_ "Confidence" SG_ 739 VCRIGHT_rearLSeatHeatCurrent 1;
BA_ "Confidence" SG_ 739 VCRIGHT_rearLSeatHeatDuty 1;
BA_ "Confidence" SG_ 739 VCRIGHT_rearLSeatHeatTmp 1;
BA_ "Confidence" SG_ 739 VCRIGHT_rearLSeatHeatTmpTarget 1;
BA_ "Confidence" SG_ 739 VCRIGHT_rearCSeatHeatCurrent 1;
BA_ "Confidence" SG_ 739 VCRIGHT_rearCSeatHeatDuty 1;
BA_ "Confidence" SG_ 739 VCRIGHT_rearCSeatHeatTmp 1;
BA_ "Confidence" SG_ 739 VCRIGHT_rearCSeatHeatTmpTarget 1;
BA_ "Confidence" SG_ 739 VCRIGHT_rearRSeatHeatCurrent 1;
BA_ "Confidence" SG_ 739 VCRIGHT_rearRSeatHeatDuty 1;
BA_ "Confidence" SG_ 739 VCRIGHT_rearRSeatHeatTmp 1;
BA_ "Confidence" SG_ 739 VCRIGHT_rearRSeatHeatTmpTarget 1;
BA_ "Confidence" SG_ 739 VCRIGHT_2RowSeatReclineState 1;
BA_ "Confidence" SG_ 739 VCRIGHT_2RowSeatReclineDuty 1;
BA_ "Confidence" SG_ 739 VCRIGHT_2RowSeatReclineCurrent 1;
BA_ "Confidence" SG_ 739 VCRIGHT_2RowSeatReclineCalibrate 1;
BA_ "SystemSignalLongSymbol" SG_ 739 VCRIGHT_2RowSeatReclineCalibrate "VCRIGHT_2RowSeatReclineCalibrated";
BA_ "Confidence" SG_ 739 VCRIGHT_2RowSeatReclinePositionR 1;
BA_ "SystemSignalLongSymbol" SG_ 739 VCRIGHT_2RowSeatReclinePositionR "VCRIGHT_2RowSeatReclinePositionRaw";
BA_ "Confidence" SG_ 739 VCRIGHT_2RowSeatReclineAngle 1;
BA_ "Confidence" SG_ 739 VCRIGHT_2RowSeatReclineAbsPosSwi 1;
BA_ "SystemSignalLongSymbol" SG_ 739 VCRIGHT_2RowSeatReclineAbsPosSwi "VCRIGHT_2RowSeatReclineAbsPosSwitchState";
BA_ "Confidence" SG_ 739 VCRIGHT_2RowSeatReclinePositionS 1;
BA_ "SystemSignalLongSymbol" SG_ 739 VCRIGHT_2RowSeatReclinePositionS "VCRIGHT_2RowSeatReclinePositionState";
BA_ "Confidence" SG_ 739 VCRIGHT_2RowSeatReclineAdjustmen 1;
BA_ "SystemSignalLongSymbol" SG_ 739 VCRIGHT_2RowSeatReclineAdjustmen "VCRIGHT_2RowSeatReclineAdjustmentAllowed";
BA_ "Confidence" SG_ 739 VCRIGHT_2RowSeatReclineFoldAllow 1;
BA_ "SystemSignalLongSymbol" SG_ 739 VCRIGHT_2RowSeatReclineFoldAllow "VCRIGHT_2RowSeatReclineFoldAllowed";
BA_ "Confidence" SG_ 739 VCRIGHT_2RowSeatReclineUnfoldAll 1;
BA_ "SystemSignalLongSymbol" SG_ 739 VCRIGHT_2RowSeatReclineUnfoldAll "VCRIGHT_2RowSeatReclineUnfoldAllowed";
BA_ "Confidence" SG_ 739 VCRIGHT_2RowSeatReclineNextToggl 1;
BA_ "SystemSignalLongSymbol" SG_ 739 VCRIGHT_2RowSeatReclineNextToggl "VCRIGHT_2RowSeatReclineNextToggleDirection";
BA_ "SystemSignalLongSymbol" SG_ 739 VCRIGHT_2RowSeatReclineChoreoBlo "VCRIGHT_2RowSeatReclineChoreoBlockedByOccupancy";
BA_ "Confidence" SG_ 739 VCRIGHT_2RowSeat1RClashAvoidance 1;
BA_ "SystemSignalLongSymbol" SG_ 739 VCRIGHT_2RowSeat1RClashAvoidance "VCRIGHT_2RowSeat1RClashAvoidanceBlockedReason";
BA_ "Confidence" SG_ 739 VCRIGHT_2RowSeat1RClashAvoi_0001 1;
BA_ "SystemSignalLongSymbol" SG_ 739 VCRIGHT_2RowSeat1RClashAvoi_0001 "VCRIGHT_2RowSeat1RClashAvoidanceState";
BA_ "Confidence" SG_ 739 VCRIGHT_2RowSeatReclineAbsP_0001 1;
BA_ "SystemSignalLongSymbol" SG_ 739 VCRIGHT_2RowSeatReclineAbsP_0001 "VCRIGHT_2RowSeatReclineAbsPosSwitchTransPoint";
BA_ "Confidence" SG_ 835 VCRIGHT_LVBatteryTypeDBG 1;
BA_ "Confidence" SG_ 835 VCRIGHT_rearDefrostState 1;
BA_ "Confidence" SG_ 835 VCRIGHT_mirrorHeatState 1;
BA_ "Confidence" SG_ 835 VCRIGHT_5AVoltage 1;
BA_ "Confidence" SG_ 835 VCRIGHT_vbatProt 1;
BA_ "Confidence" SG_ 835 VCRIGHT_rationalityAggregateCurr 1;
BA_ "SystemSignalLongSymbol" SG_ 835 VCRIGHT_rationalityAggregateCurr "VCRIGHT_rationalityAggregateCurrent";
BA_ "Confidence" SG_ 835 VCRIGHT_eFuseMgmtVoltageMonitor 1;
BA_ "Confidence" SG_ 835 VCRIGHT_steeringWheelHeaterDCTgt 1;
BA_ "SystemSignalLongSymbol" SG_ 963 VCRIGHT_trunkExtReleasePressedPe "VCRIGHT_trunkExtReleasePressedPersist";
BA_ "Confidence" SG_ 963 VCRIGHT_frontSeatTrackBack 1;
BA_ "Confidence" SG_ 963 VCRIGHT_frontSeatTrackForward 1;
BA_ "Confidence" SG_ 963 VCRIGHT_frontSeatTiltDown 1;
BA_ "Confidence" SG_ 963 VCRIGHT_frontSeatTiltUp 1;
BA_ "Confidence" SG_ 963 VCRIGHT_frontSeatLiftDown 1;
BA_ "Confidence" SG_ 963 VCRIGHT_frontSeatLiftUp 1;
BA_ "Confidence" SG_ 963 VCRIGHT_frontSeatBackrestBack 1;
BA_ "Confidence" SG_ 963 VCRIGHT_frontSeatBackrestForward 1;
BA_ "Confidence" SG_ 963 VCRIGHT_frontSeatLumbarDown 1;
BA_ "Confidence" SG_ 963 VCRIGHT_frontSeatLumbarUp 1;
BA_ "Confidence" SG_ 963 VCRIGHT_frontSeatLumbarIn 1;
BA_ "Confidence" SG_ 963 VCRIGHT_frontSeatLumbarOut 1;
BA_ "Confidence" SG_ 963 VCRIGHT_2RowSeatReclineSwitch 1;
BA_ "Confidence" SG_ 963 VCRIGHT_2RowSeatBackrestFoldSwit 1;
BA_ "SystemSignalLongSymbol" SG_ 963 VCRIGHT_2RowSeatBackrestFoldSwit "VCRIGHT_2RowSeatBackrestFoldSwitch";
BA_ "Confidence" SG_ 963 VCRIGHT_frontHandlePWM 1;
BA_ "Confidence" SG_ 963 VCRIGHT_rearHandlePWM 1;
BA_ "Confidence" SG_ 963 VCRIGHT_gloveboxLightCurrent 1;
BA_ "Confidence" SG_ 963 VCRIGHT_frontSeatALR 1;
BA_ "Confidence" SG_ 963 VCRIGHT_frontSeatResistiveOccupa 1;
BA_ "SystemSignalLongSymbol" SG_ 963 VCRIGHT_frontSeatResistiveOccupa "VCRIGHT_frontSeatResistiveOccupancy";
BA_ "Confidence" SG_ 963 VCRIGHT_2RowSeatReclineSwitchpac 1;
BA_ "SystemSignalLongSymbol" SG_ 963 VCRIGHT_2RowSeatReclineSwitchpac "VCRIGHT_2RowSeatReclineSwitchpackState";
BA_ "Confidence" SG_ 899 VCRIGHT_thsTemperature 1;
BA_ "Confidence" SG_ 899 VCRIGHT_thsState 1;
BA_ "Confidence" SG_ 899 VCRIGHT_thsLINCurrentSchedule 1;
BA_ "Confidence" SG_ 899 VCRIGHT_thsDetected 1;
BA_ "Confidence" SG_ 899 VCRIGHT_thsHumidity 1;
BA_ "Confidence" SG_ 899 VCRIGHT_estimatedVehicleSituatio 1;
BA_ "SystemSignalLongSymbol" SG_ 899 VCRIGHT_estimatedVehicleSituatio "VCRIGHT_estimatedVehicleSituation";
BA_ "Confidence" SG_ 899 VCRIGHT_thsSolarLoadInfrared 1;
BA_ "Confidence" SG_ 899 VCRIGHT_thsSolarLoadVisible 1;
BA_ "Confidence" SG_ 899 VCRIGHT_estimatedThsSolarLoad 1;
BA_ "Confidence" SG_ 1059 VCRIGHT_nmKeepAwakeReason 1;
BA_ "Confidence" SG_ 1059 VCRIGHT_nmWakeUpReason 1;
BA_ "Confidence" SG_ 1059 VCRIGHT_nmDebugWakeUp 1;
BA_ "Confidence" SG_ 1059 VCRIGHT_nmEthKeepAwakeReason 1;
BA_ "Confidence" SG_ 1059 VCRIGHT_nmChKeepAwakeReason 1;
BA_ "Confidence" SG_ 707 VCRIGHT_windowStateRF 1;
BA_ "Confidence" SG_ 707 VCRIGHT_windowTrimClearMoveReque 1;
BA_ "SystemSignalLongSymbol" SG_ 707 VCRIGHT_windowTrimClearMoveReque "VCRIGHT_windowTrimClearMoveRequest";
BA_ "Confidence" SG_ 707 VCRIGHT_windowDutyRF 1;
BA_ "Confidence" SG_ 707 VCRIGHT_windowTrimClearActiveReq 1;
BA_ "SystemSignalLongSymbol" SG_ 707 VCRIGHT_windowTrimClearActiveReq "VCRIGHT_windowTrimClearActiveRequest";
BA_ "Confidence" SG_ 707 VCRIGHT_windowCurrentRF 1;
BA_ "Confidence" SG_ 707 VCRIGHT_windowPositionRF 1;
BA_ "Confidence" SG_ 707 VCRIGHT_windowCalibratedRF 1;
BA_ "Confidence" SG_ 707 VCRIGHT_windowStateRR 1;
BA_ "Confidence" SG_ 707 VCRIGHT_windowDutyRR 1;
BA_ "Confidence" SG_ 707 VCRIGHT_windowCurrentRR 1;
BA_ "Confidence" SG_ 707 VCRIGHT_windowPositionRR 1;
BA_ "Confidence" SG_ 707 VCRIGHT_windowCalibratedRR 1;
BA_ "Confidence" SG_ 707 VCRIGHT_windowThermalTCRF 1;
BA_ "Confidence" SG_ 707 VCRIGHT_windowThermalModeRF 1;
BA_ "Confidence" SG_ 707 VCRIGHT_windowStopReasonRF 1;
BA_ "Confidence" SG_ 707 VCRIGHT_windowStopReqReasonRF 1;
BA_ "Confidence" SG_ 707 VCRIGHT_windowThermalTCRR 1;
BA_ "Confidence" SG_ 707 VCRIGHT_windowThermalModeRR 1;
BA_ "Confidence" SG_ 707 VCRIGHT_windowStopReasonRR 1;
BA_ "Confidence" SG_ 707 VCRIGHT_windowStopReqReasonRR 1;
BA_ "Confidence" SG_ 707 VCRIGHT_windowControlStateRF 1;
BA_ "Confidence" SG_ 707 VCRIGHT_windowCtrlUnavailableRF 1;
BA_ "Confidence" SG_ 707 VCRIGHT_windowControlStateRR 1;
BA_ "Confidence" SG_ 707 VCRIGHT_windowCtrlUnavailableRR 1;
BA_ "Confidence" SG_ 707 VCRIGHT_windowPositionStateRF 1;
BA_ "Confidence" SG_ 707 VCRIGHT_windowPositionStateRR 1;
BA_ "Confidence" SG_ 707 VCRIGHT_windowVehGearStateRF 1;
BA_ "Confidence" SG_ 707 VCRIGHT_windowVehGearStateRR 1;
BA_ "Confidence" SG_ 707 VCRIGHT_windowSpeedTableStatusRF 1;
BA_ "Confidence" SG_ 707 VCRIGHT_windowSpeedTableStatusRR 1;
VAL_ 259 VCRIGHT_doorClosureStatusFront 8 "CLOSURE_STATUS_FAULT" 2 "CLOSURE_STATUS_CLOSED" 1 "CLOSURE_STATUS_OPEN" 0 "CLOSURE_STATUS_SNA" ;
VAL_ 259 VCRIGHT_doorClosureStatusRear 8 "CLOSURE_STATUS_FAULT" 2 "CLOSURE_STATUS_CLOSED" 1 "CLOSURE_STATUS_OPEN" 0 "CLOSURE_STATUS_SNA" ;
VAL_ 259 VCRIGHT_frontLatchStatus 8 "LATCH_FAULT" 7 "LATCH_DEFAULT" 6 "LATCH_TIMEOUT" 5 "LATCH_AJAR" 4 "LATCH_OPENING" 3 "LATCH_CLOSING" 2 "LATCH_CLOSED" 1 "LATCH_OPENED" 0 "LATCH_SNA" ;
VAL_ 259 VCRIGHT_rearLatchStatus 8 "LATCH_FAULT" 7 "LATCH_DEFAULT" 6 "LATCH_TIMEOUT" 5 "LATCH_AJAR" 4 "LATCH_OPENING" 3 "LATCH_CLOSING" 2 "LATCH_CLOSED" 1 "LATCH_OPENED" 0 "LATCH_SNA" ;
VAL_ 259 VCRIGHT_lastDoorReqSourceFront 4 "DOOR_REQUEST_SOURCE_ECU" 3 "DOOR_REQUEST_SOURCE_VCSEC" 2 "DOOR_REQUEST_SOURCE_EXTERIOR_HANDLE" 1 "DOOR_REQUEST_SOURCE_INTERIOR_BUTTON" 0 "DOOR_REQUEST_SOURCE_UNKNOWN" ;
VAL_ 259 VCRIGHT_lastDoorReqSourceRear 4 "DOOR_REQUEST_SOURCE_ECU" 3 "DOOR_REQUEST_SOURCE_VCSEC" 2 "DOOR_REQUEST_SOURCE_EXTERIOR_HANDLE" 1 "DOOR_REQUEST_SOURCE_INTERIOR_BUTTON" 0 "DOOR_REQUEST_SOURCE_UNKNOWN" ;
VAL_ 259 VCRIGHT_mirrorState 5 "MIRROR_STATE_CALIBRATION" 4 "MIRROR_STATE_RECALL" 3 "MIRROR_STATE_FOLD_UNFOLD" 2 "MIRROR_STATE_TILT_Y" 1 "MIRROR_STATE_TILT_X" 0 "MIRROR_STATE_IDLE" ;
VAL_ 259 VCRIGHT_mirrorFoldState 4 "MIRROR_FOLD_STATE_UNFOLDING" 3 "MIRROR_FOLD_STATE_FOLDING" 2 "MIRROR_FOLD_STATE_UNFOLDED" 1 "MIRROR_FOLD_STATE_FOLDED" 0 "MIRROR_FOLD_STATE_UNKNOWN" ;
VAL_ 259 VCRIGHT_trunkLatchStatus 8 "LATCH_FAULT" 7 "LATCH_DEFAULT" 6 "LATCH_TIMEOUT" 5 "LATCH_AJAR" 4 "LATCH_OPENING" 3 "LATCH_CLOSING" 2 "LATCH_CLOSED" 1 "LATCH_OPENED" 0 "LATCH_SNA" ;
VAL_ 259 VCRIGHT_mirrorRecallState 5 "MIRROR_RECALL_STATE_RECALLING_STOPPED" 4 "MIRROR_RECALL_STATE_RECALLING_FAILED" 3 "MIRROR_RECALL_STATE_RECALLING_COMPLETE" 2 "MIRROR_RECALL_STATE_RECALLING_AXIS_2" 1 "MIRROR_RECALL_STATE_RECALLING_AXIS_1" 0 "MIRROR_RECALL_STATE_INIT" ;
VAL_ 2010 VCRIGHT_BPillarCameraHeaterState 4 "HEATER_STATE_FAULT" 3 "HEATER_STATE_OFF_UNAVAILABLE" 2 "HEATER_STATE_OFF" 1 "HEATER_STATE_ON" 0 "HEATER_STATE_SNA" ;
VAL_ 915 VCRIGHT_epbmCaliperState 6 "EPB_SAVED_CALIPERSTATE_WINCHMODE" 5 "EPB_SAVED_CALIPERSTATE_SERVICE" 4 "EPB_SAVED_CALIPERSTATE_OPEN" 3 "EPB_SAVED_CALIPERSTATE_PARK" 2 "EPB_SAVED_CALIPERSTATE_REAPPLY" 1 "EPB_SAVED_CALIPERSTATE_UNKNOWN" 0 "EPB_SAVED_CALIPERSTATE_UNSAVED" ;
VAL_ 915 VCRIGHT_summonFaultReason 30 "EPB_SUMMONFAULT_MONITOR_TYPE_UNKNOWN" 29 "EPB_SUMMONFAULT_AP_MONITOR" 28 "EPB_SUMMONFAULT_REMOTE_DID_NOT_START" 27 "EPB_SUMMONFAULT_INVALID_REMOTE_STATE" 26 "EPB_SUMMONFAULT_START_IN_UNAVAILABLE" 25 "EPB_SUMMONFAULT_REMOTE_UNIT_FAULTED" 24 "EPB_SUMMONFAULT_LOCAL_UNIT_FAULTED" 23 "EPB_SUMMONFAULT_REMOTE_SUMMON_FAULTED" 22 "EPB_SUMMONFAULT_EPBREMOTE_MIA" 21 "EPB_SUMMONFAULT_PASSIVE_REQUEST" 20 "EPB_SUMMONFAULT_DI_STATE_INVALID" 19 "EPB_SUMMONFAULT_EPB_FAULT" 18 "EPB_SUMMONFAULT_MISMATCH" 17 "EPB_SUMMONFAULT_OOC" 16 "EPB_SUMMONFAULT_PM_REQUEST" 15 "EPB_SUMMONFAULT_PM_MIA" 14 "EPB_SUMMONFAULT_PARK_MIA" 13 "EPB_SUMMONFAULT_EXTERNAL" 12 "EPB_SUMMONFAULT_SPEED" 11 "EPB_SUMMONFAULT_EPBM_REQUEST" 10 "EPB_SUMMONFAULT_EAC_NOT_ALLOWED" 9 "EPB_SUMMONFAULT_VEH_CAN_FAULT" 8 "EPB_SUMMONFAULT_ESP_FAULT" 7 "EPB_SUMMONFAULT_DAS_FAULT" 6 "EPB_SUMMONFAULT_DI_APC_FAULT" 5 "EPB_SUMMONFAULT_DI_FAULT" 4 "EPB_SUMMONFAULT_EPBM_MIA" 3 "EPB_SUMMONFAULT_ESP_MIA" 2 "EPB_SUMMONFAULT_DAS_MIA" 1 "EPB_SUMMONFAULT_DI_MIA" 0 "EPB_SUMMONFAULT_NONE" ;
VAL_ 915 VCRIGHT_epbSummonState 6 "EPB_SUMMON_UNAVAILABLE" 5 "EPB_SUMMON_FAULT" 4 "EPB_SUMMON_COMPLETE" 3 "EPB_SUMMON_ACTIVE" 2 "EPB_SUMMON_ARMED" 1 "EPB_SUMMON_IDLE" 0 "EPB_SUMMON_INIT" ;
VAL_ 915 VCRIGHT_epbmSummonState 6 "EPB_SUMMON_UNAVAILABLE" 5 "EPB_SUMMON_FAULT" 4 "EPB_SUMMON_COMPLETE" 3 "EPB_SUMMON_ACTIVE" 2 "EPB_SUMMON_ARMED" 1 "EPB_SUMMON_IDLE" 0 "EPB_SUMMON_INIT" ;
VAL_ 915 VCRIGHT_epbUnitStatus 23 "EPB_STATUS_COUNT" 22 "EPB_STATUS_AUTONOMY_OPEN" 21 "EPB_STATUS_FREE_ROLL_MODE" 20 "EPB_STATUS_DYNAMIC_PARKING" 19 "EPB_STATUS_EXTERNAL_PARKING" 18 "EPB_STATUS_RELEASING_FOR_EXTERNAL_PARK" 17 "EPB_STATUS_EXTERNAL_DYNAMIC" 16 "EPB_STATUS_SUMMON_PARKING" 15 "EPB_STATUS_SUMMON_RELEASING" 14 "EPB_STATUS_SUMMON" 13 "EPB_STATUS_WINCHMODE_PENDING" 12 "EPB_STATUS_PARK_PENDING" 11 "EPB_STATUS_SERVICE_RELEASING" 10 "EPB_STATUS_RELEASING" 9 "EPB_STATUS_DYNAMIC_APPLYING" 8 "EPB_STATUS_PARKING" 7 "EPB_STATUS_WINCHMODE_RELEASING" 6 "EPB_STATUS_WINCHMODE" 5 "EPB_STATUS_SERVICE" 4 "EPB_STATUS_START" 3 "EPB_STATUS_PARK" 2 "EPB_STATUS_DYNAMIC" 1 "EPB_STATUS_OPEN" 0 "EPB_STATUS_UNKNOWN" ;
VAL_ 915 VCRIGHT_epbmFaultStatus 3 "EPB_STATUS_FAULT_IDLE" 2 "EPB_STATUS_FAULT" 1 "EPB_STATUS_RETRY" 0 "EPB_STATUS_NOMINAL" ;
VAL_ 915 VCRIGHT_epbFaultStatus 3 "EPB_STATUS_FAULT_IDLE" 2 "EPB_STATUS_FAULT" 1 "EPB_STATUS_RETRY" 0 "EPB_STATUS_NOMINAL" ;
VAL_ 915 VCRIGHT_epbmSystemStatus 8 "EPB_VEHICLE_STATUS_MISMATCH" 7 "EPB_VEHICLE_STATUS_FAULT_SECURE" 6 "EPB_VEHICLE_STATUS_FAULT" 5 "EPB_VEHICLE_STATUS_RELEASING" 4 "EPB_VEHICLE_STATUS_PARKING" 3 "EPB_VEHICLE_STATUS_DYNAMIC" 2 "EPB_VEHICLE_STATUS_PARKED" 1 "EPB_VEHICLE_STATUS_RELEASED" 0 "EPB_VEHICLE_STATUS_UNKNOWN" ;
VAL_ 1123 VCRIGHT_cdpRequestState 1 "EPB_CDP_REQUEST_VALID" 0 "EPB_CDP_REQUEST_INVALID" ;
VAL_ 1123 VCRIGHT_epbmSystemStatusQF 1 "EPBM_SYSTEM_STATUS_INVALID" 0 "EPBM_SYSTEM_STATUS_VALID" ;
VAL_ 1123 VCRIGHT_epbmUnitStatus 23 "EPB_STATUS_COUNT" 22 "EPB_STATUS_AUTONOMY_OPEN" 21 "EPB_STATUS_FREE_ROLL_MODE" 20 "EPB_STATUS_DYNAMIC_PARKING" 19 "EPB_STATUS_EXTERNAL_PARKING" 18 "EPB_STATUS_RELEASING_FOR_EXTERNAL_PARK" 17 "EPB_STATUS_EXTERNAL_DYNAMIC" 16 "EPB_STATUS_SUMMON_PARKING" 15 "EPB_STATUS_SUMMON_RELEASING" 14 "EPB_STATUS_SUMMON" 13 "EPB_STATUS_WINCHMODE_PENDING" 12 "EPB_STATUS_PARK_PENDING" 11 "EPB_STATUS_SERVICE_RELEASING" 10 "EPB_STATUS_RELEASING" 9 "EPB_STATUS_DYNAMIC_APPLYING" 8 "EPB_STATUS_PARKING" 7 "EPB_STATUS_WINCHMODE_RELEASING" 6 "EPB_STATUS_WINCHMODE" 5 "EPB_STATUS_SERVICE" 4 "EPB_STATUS_START" 3 "EPB_STATUS_PARK" 2 "EPB_STATUS_DYNAMIC" 1 "EPB_STATUS_OPEN" 0 "EPB_STATUS_UNKNOWN" ;
VAL_ 1123 VCRIGHT_epbmCdpState 2 "EPB_CDP_STATE_FAULT" 1 "EPB_CDP_STATE_VALID" 0 "EPB_CDP_STATE_UNKNOWN" ;
VAL_ 524 VCRIGHT_hvacPerfTestState 2 "BLOWING" 1 "WAITING" 0 "STOPPED" ;
VAL_ 579 VCRIGHT_childModeHVACState 2 "ACTIVE_COMPROMISED" 1 "ACTIVE" 0 "IDLE" ;
VAL_ 579 VCRIGHT_dogModeState 15 "DOG_MODE_INVALID" 6 "DOG_MODE_RUNNING_TEMP_MONITOR_TRIP" 5 "DOG_MODE_RUNNING_DEVICE_OR_MODEL_FAULT" 4 "DOG_MODE_RUNNING" 3 "DOG_MODE_AVAILABLE" 2 "DOG_MODE_INITIALIZING" 1 "DOG_MODE_UNAVAILABLE_CABIN_TOO_HOT" 0 "DOG_MODE_UNAVAILABLE_MODEL_DEVICE_FAULT" ;
VAL_ 579 VCRIGHT_COPNotRunningReasonFilte 7 "CABIN_BELOW_THRESHOLD" 6 "WAITING" 5 "LOW_SOLAR_LOAD" 4 "TIMEOUT" 3 "ENERGY_CONSUMPTION_LIMIT" 2 "USER_INTERACTION" 1 "DISABLED" 0 "NONE" ;
VAL_ 579 VCRIGHT_hvacAirDistributionMode 7 "DEFROST_PANEL_FLOOR" 6 "DEFROST_PANEL" 5 "DEFROST_FLOOR" 4 "DEFROST" 3 "PANEL_FLOOR" 2 "PANEL" 1 "FLOOR" 0 "NONE" ;
VAL_ 579 VCRIGHT_hvacBlowerSegment 11 "11" 10 "10" 9 "9" 8 "8" 7 "7" 6 "6" 5 "5" 4 "4" 3 "3" 2 "2" 1 "1" 0 "OFF" ;
VAL_ 579 VCRIGHT_hvacRecirc 2 "FRESH" 1 "RECIRC" 0 "AUTO" ;
VAL_ 579 VCRIGHT_hvacACRunning 1 "ON" 0 "OFF" ;
VAL_ 579 VCRIGHT_hvacPowerState 4 "OVERHEAT_PROTECT" 3 "OVERHEAT_PROTECT_FANONLY" 2 "PRECONDITION" 1 "ON" 0 "OFF" ;
VAL_ 579 VCRIGHT_hvacVentStatus 3 "OFF" 2 "RIGHT" 1 "LEFT" 0 "BOTH" ;
VAL_ 579 VCRIGHT_hvacSecondRowState 4 "HIGH" 3 "MED" 2 "LOW" 1 "OFF" 0 "AUTO" ;
VAL_ 579 VCRIGHT_hvacModelInitStatus 9 "NOT_INIT_CAMERA_POCKET_BEING_INITIALIZED" 8 "INIT_FORWARD_CALC_LIMP" 7 "INIT_FROM_SENSORS_PREDICTION_ERROR_LIMP" 6 "INIT_FROM_SENSORS_LIMP" 5 "INIT_WAITING_FOR_SENSORS" 4 "INIT_FORWARD_CALC" 3 "INIT_FROM_SENSORS_PREDICTION_ERROR" 2 "INIT_FROM_SENSORS" 1 "NOT_INIT_WAIT_FOR_GTW" 0 "NOT_INIT_WAIT_FOR_SENSORS" ;
VAL_ 579 VCRIGHT_hvacAirflowReason 21 "NONE" 20 "ODOR_ROUTINE" 19 "DRIVERLESS_SELF_TEST" 18 "VOC_PURGE" 17 "STRATIFICATION_TOP_PAD_AREA" 16 "HOT_DUCT_LOCKOUT" 15 "COLD_DUCT_LOCKOUT" 14 "BIOWEAPON_DEFENSE" 13 "EVAP_OIL_PURGE" 12 "EVAP_DRYING" 11 "SCREEN_PROTECTION" 10 "CABIN_OVERHEAT_PROTECT" 9 "CABIN_PURGE" 8 "OUTLET_TEMP_LIMIT" 7 "OCCUPANT_CONVECTION_REQUIREMENT" 6 "STRATIFICATION_INTERIOR_SURFACES" 5 "STRATIFICATION_GLASS_ROOF" 4 "MINIMUM_AUTO_AIRFLOW" 3 "CABIN_TEMPERATURE_CONTROL" 2 "UI_SHORTCUT" 1 "MANUAL_FAN_SPEED" 0 "HVAC_OFF" ;
VAL_ 579 VCRIGHT_hvacFrontRightSeatFanSta 3 "FAN_REQUEST_LEVEL3" 2 "FAN_REQUEST_LEVEL2" 1 "FAN_REQUEST_LEVEL1" 0 "FAN_REQUEST_OFF" ;
VAL_ 579 VCRIGHT_hvacFrontLeftSeatFanStat 3 "FAN_REQUEST_LEVEL3" 2 "FAN_REQUEST_LEVEL2" 1 "FAN_REQUEST_LEVEL1" 0 "FAN_REQUEST_OFF" ;
VAL_ 579 VCRIGHT_hvacFrontRightSeatHeatSt 3 "HEATER_REQUEST_LEVEL3" 2 "HEATER_REQUEST_LEVEL2" 1 "HEATER_REQUEST_LEVEL1" 0 "HEATER_REQUEST_OFF" ;
VAL_ 579 VCRIGHT_hvacManualToAutoNotify 6 "MISC3" 5 "MISC2" 4 "COMFORT_FORWARD_LOOK" 3 "FOGGING_COMFORT" 2 "FOGGING" 1 "COMFORT" 0 "OFF" ;
VAL_ 579 VCRIGHT_hvacRequestsFullAuto 7 "MISC4" 6 "MISC3" 5 "MISC2" 4 "MISC1" 3 "HVAC_OFF_FOGGING_RISK" 2 "MANUAL_HVAC_HIGH_FOGGING_RISK" 1 "HIGH_BLOWER_SPEED" 0 "NOT_ALLOWED" ;
VAL_ 579 VCRIGHT_steeringWheelHeatStatus 3 "STEERING_WHEEL_HEAT_LEVEL3" 2 "STEERING_WHEEL_HEAT_LEVEL2" 1 "STEERING_WHEEL_HEAT_LEVEL1" 0 "STEERING_WHEEL_HEAT_OFF" ;
VAL_ 579 VCRIGHT_autoDefogStatus 2 "INTERMEDIATE_DEFOG" 1 "DEFOG" 0 "NONE" ;
VAL_ 579 VCRIGHT_hvacLimitedReasonRight 7 "HVAC_LIMITING_MANUAL_BLOWER" 6 "HVAC_LIMITING_CDL_AND_QDLH" 5 "HVAC_LIMITING_HDL_AND_QDLC" 4 "HVAC_LIMITING_QDOT_LIMITED_HEATING" 3 "HVAC_LIMITING_QDOT_LIMITED_COOLING" 2 "HVAC_LIMITING_COLD_DUCT_LOCKOUT" 1 "HVAC_LIMITING_HOT_DUCT_LOCKOUT" 0 "HVAC_LIMITING_NONE" ;
VAL_ 579 VCRIGHT_hvacLimitedReasonLeft 7 "HVAC_LIMITING_MANUAL_BLOWER" 6 "HVAC_LIMITING_CDL_AND_QDLH" 5 "HVAC_LIMITING_HDL_AND_QDLC" 4 "HVAC_LIMITING_QDOT_LIMITED_HEATING" 3 "HVAC_LIMITING_QDOT_LIMITED_COOLING" 2 "HVAC_LIMITING_COLD_DUCT_LOCKOUT" 1 "HVAC_LIMITING_HOT_DUCT_LOCKOUT" 0 "HVAC_LIMITING_NONE" ;
VAL_ 579 VCRIGHT_hvacFrontLeftSeatHeatSta 3 "HEATER_REQUEST_LEVEL3" 2 "HEATER_REQUEST_LEVEL2" 1 "HEATER_REQUEST_LEVEL1" 0 "HEATER_REQUEST_OFF" ;
VAL_ 774 VCRIGHT_infoBuildType 4 "INFO_MFG_BUILD" 3 "INFO_TRACEABLE_CI_BUILD" 2 "INFO_LOCAL_BUILD" 1 "INFO_PLATFORM_BUILD" 0 "INFO_UNKNOWN_BUILD" ;
VAL_ 995 VCRIGHT_brakeLightStatus 3 "LIGHT_SNA" 2 "LIGHT_FAULT" 1 "LIGHT_ON" 0 "LIGHT_OFF" ;
VAL_ 995 VCRIGHT_tailLightStatus 3 "LIGHT_SNA" 2 "LIGHT_FAULT" 1 "LIGHT_ON" 0 "LIGHT_OFF" ;
VAL_ 995 VCRIGHT_turnSignalStatus 3 "LIGHT_SNA" 2 "LIGHT_FAULT" 1 "LIGHT_ON" 0 "LIGHT_OFF" ;
VAL_ 995 VCRIGHT_reverseLightStatus 3 "LIGHT_SNA" 2 "LIGHT_FAULT" 1 "LIGHT_ON" 0 "LIGHT_OFF" ;
VAL_ 995 VCRIGHT_rearFogLightStatus 3 "LIGHT_SNA" 2 "LIGHT_FAULT" 1 "LIGHT_ON" 0 "LIGHT_OFF" ;
VAL_ 995 VCRIGHT_fasciaReverseLightStatus 3 "LIGHT_SNA" 2 "LIGHT_FAULT" 1 "LIGHT_ON" 0 "LIGHT_OFF" ;
VAL_ 995 VCRIGHT_fasciaRearFogStatus 3 "LIGHT_SNA" 2 "LIGHT_FAULT" 1 "LIGHT_ON" 0 "LIGHT_OFF" ;
VAL_ 995 VCRIGHT_fasciaTailLightStatus 3 "LIGHT_SNA" 2 "LIGHT_FAULT" 1 "LIGHT_ON" 0 "LIGHT_OFF" ;
VAL_ 995 VCRIGHT_fasciaLeftTurnSignalStat 3 "LIGHT_SNA" 2 "LIGHT_FAULT" 1 "LIGHT_ON" 0 "LIGHT_OFF" ;
VAL_ 995 VCRIGHT_fasciaRightTurnSignalSta 3 "LIGHT_SNA" 2 "LIGHT_FAULT" 1 "LIGHT_ON" 0 "LIGHT_OFF" ;
VAL_ 995 VCRIGHT_CHMSLLightStatus 3 "LIGHT_SNA" 2 "LIGHT_FAULT" 1 "LIGHT_ON" 0 "LIGHT_OFF" ;
VAL_ 1803 VCRIGHT_leftPTCCompromisedRod 7 "CENTER_INNER" 6 "OUTER_CENTER" 5 "OUTER_INNER" 4 "OUTER" 3 "CENTER" 2 "INNER" 1 "ALL" 0 "NONE" ;
VAL_ 1803 VCRIGHT_rightPTCCompromisedRod 7 "CENTER_INNER" 6 "OUTER_CENTER" 5 "OUTER_INNER" 4 "OUTER" 3 "CENTER" 2 "INNER" 1 "ALL" 0 "NONE" ;
VAL_ 611 VCRIGHT_hvacLHBleedActuatorState 2 "HVACACTUATOR_STATE_COASTING" 1 "HVACACTUATOR_STATE_RUNNING" 0 "HVACACTUATOR_STATE_BRAKING" ;
VAL_ 611 VCRIGHT_hvacRHBleedActuatorState 2 "HVACACTUATOR_STATE_COASTING" 1 "HVACACTUATOR_STATE_RUNNING" 0 "HVACACTUATOR_STATE_BRAKING" ;
VAL_ 611 VCRIGHT_hvacLHVaneActuatorState 2 "HVACACTUATOR_STATE_COASTING" 1 "HVACACTUATOR_STATE_RUNNING" 0 "HVACACTUATOR_STATE_BRAKING" ;
VAL_ 611 VCRIGHT_hvacRHVaneActuatorState 2 "HVACACTUATOR_STATE_COASTING" 1 "HVACACTUATOR_STATE_RUNNING" 0 "HVACACTUATOR_STATE_BRAKING" ;
VAL_ 611 VCRIGHT_hvacUpperModeActState 2 "HVACACTUATOR_STATE_COASTING" 1 "HVACACTUATOR_STATE_RUNNING" 0 "HVACACTUATOR_STATE_BRAKING" ;
VAL_ 611 VCRIGHT_hvacLowerModeActState 2 "HVACACTUATOR_STATE_COASTING" 1 "HVACACTUATOR_STATE_RUNNING" 0 "HVACACTUATOR_STATE_BRAKING" ;
VAL_ 611 VCRIGHT_hvacIntakeActuatorState 2 "HVACACTUATOR_STATE_COASTING" 1 "HVACACTUATOR_STATE_RUNNING" 0 "HVACACTUATOR_STATE_BRAKING" ;
VAL_ 611 VCRIGHT_ptcHeaterBadRodDetection 11 "UNAVAILABLE" 10 "CLEAR_FAULT_RESTART" 9 "CLEAR_FAULT" 8 "CHECK_RIGHT_INNER" 7 "CHECK_RIGHT_CENTER" 6 "CHECK_RIGHT_OUTER" 5 "CHECK_LEFT_INNER" 4 "CHECK_LEFT_CENTER" 3 "CHECK_LEFT_OUTER" 2 "DETECTED" 1 "IDLE" 0 "INIT" ;
VAL_ 691 VCRIGHT_hvacAutoTransitionReason 23 "END" 22 "VOC_PURGE" 21 "RETURN_FROM_DEFOG_OVERRIDE" 20 "HVAC_AIR_HUMID" 19 "BIODEFENSE" 18 "DUCT_TARGETS_INVALID" 17 "HVAC_OFF" 16 "EVAP_OIL_PURGE" 15 "EVAP_DRYING" 14 "CABIN_PURGE" 13 "SET_TEMP_HI" 12 "SET_TEMP_LO" 11 "DEFOG_OVERRIDE" 10 "BI_LEVEL_LANDING" 9 "DUCTS_COLD" 8 "TEMP_TARGET_LOW" 7 "OCCUPANT_CONVECTION_REQUIREMENT" 6 "EXCESS_OCCUPANT_CONVECTION" 5 "TEMP_TARGET_ABOVE_THRESHOLD" 4 "TEMP_TARGET_BELOW_THRESHOLD" 3 "HUMIDITY_LOW" 2 "HUMIDITY_MODERATE" 1 "HUMIDITY_HIGH" 0 "NONE" ;
VAL_ 691 VCRIGHT_hvacLHBleedOperationMode 1 "HVACACTUATOR_OPERATION_MODE_CALIBRATION" 0 "HVACACTUATOR_OPERATION_MODE_NORMAL" ;
VAL_ 691 VCRIGHT_hvacRHBleedOperationMode 1 "HVACACTUATOR_OPERATION_MODE_CALIBRATION" 0 "HVACACTUATOR_OPERATION_MODE_NORMAL" ;
VAL_ 691 VCRIGHT_hvacLHVaneOperationMode 1 "HVACACTUATOR_OPERATION_MODE_CALIBRATION" 0 "HVACACTUATOR_OPERATION_MODE_NORMAL" ;
VAL_ 691 VCRIGHT_hvacRHVaneOperationMode 1 "HVACACTUATOR_OPERATION_MODE_CALIBRATION" 0 "HVACACTUATOR_OPERATION_MODE_NORMAL" ;
VAL_ 691 VCRIGHT_hvacUpperModeOpMode 1 "HVACACTUATOR_OPERATION_MODE_CALIBRATION" 0 "HVACACTUATOR_OPERATION_MODE_NORMAL" ;
VAL_ 691 VCRIGHT_hvacLowerModeOpMode 1 "HVACACTUATOR_OPERATION_MODE_CALIBRATION" 0 "HVACACTUATOR_OPERATION_MODE_NORMAL" ;
VAL_ 691 VCRIGHT_hvacIntakeOperationMode 1 "HVACACTUATOR_OPERATION_MODE_CALIBRATION" 0 "HVACACTUATOR_OPERATION_MODE_NORMAL" ;
VAL_ 691 VCRIGHT_isProbeFeedbackApplied 4 "NEGATIVEHIGH" 3 "POSITIVEHIGH" 2 "NEGATIVE" 1 "POSITIVE" 0 "OFF" ;
VAL_ 691 VCRIGHT_hvacAirflowReasonRight 21 "NONE" 20 "ODOR_ROUTINE" 19 "DRIVERLESS_SELF_TEST" 18 "VOC_PURGE" 17 "STRATIFICATION_TOP_PAD_AREA" 16 "HOT_DUCT_LOCKOUT" 15 "COLD_DUCT_LOCKOUT" 14 "BIOWEAPON_DEFENSE" 13 "EVAP_OIL_PURGE" 12 "EVAP_DRYING" 11 "SCREEN_PROTECTION" 10 "CABIN_OVERHEAT_PROTECT" 9 "CABIN_PURGE" 8 "OUTLET_TEMP_LIMIT" 7 "OCCUPANT_CONVECTION_REQUIREMENT" 6 "STRATIFICATION_INTERIOR_SURFACES" 5 "STRATIFICATION_GLASS_ROOF" 4 "MINIMUM_AUTO_AIRFLOW" 3 "CABIN_TEMPERATURE_CONTROL" 2 "UI_SHORTCUT" 1 "MANUAL_FAN_SPEED" 0 "HVAC_OFF" ;
VAL_ 691 VCRIGHT_hvacAirflowReasonLeft 21 "NONE" 20 "ODOR_ROUTINE" 19 "DRIVERLESS_SELF_TEST" 18 "VOC_PURGE" 17 "STRATIFICATION_TOP_PAD_AREA" 16 "HOT_DUCT_LOCKOUT" 15 "COLD_DUCT_LOCKOUT" 14 "BIOWEAPON_DEFENSE" 13 "EVAP_OIL_PURGE" 12 "EVAP_DRYING" 11 "SCREEN_PROTECTION" 10 "CABIN_OVERHEAT_PROTECT" 9 "CABIN_PURGE" 8 "OUTLET_TEMP_LIMIT" 7 "OCCUPANT_CONVECTION_REQUIREMENT" 6 "STRATIFICATION_INTERIOR_SURFACES" 5 "STRATIFICATION_GLASS_ROOF" 4 "MINIMUM_AUTO_AIRFLOW" 3 "CABIN_TEMPERATURE_CONTROL" 2 "UI_SHORTCUT" 1 "MANUAL_FAN_SPEED" 0 "HVAC_OFF" ;
VAL_ 691 VCRIGHT_airflowReasonAutoInManua 21 "NONE" 20 "ODOR_ROUTINE" 19 "DRIVERLESS_SELF_TEST" 18 "VOC_PURGE" 17 "STRATIFICATION_TOP_PAD_AREA" 16 "HOT_DUCT_LOCKOUT" 15 "COLD_DUCT_LOCKOUT" 14 "BIOWEAPON_DEFENSE" 13 "EVAP_OIL_PURGE" 12 "EVAP_DRYING" 11 "SCREEN_PROTECTION" 10 "CABIN_OVERHEAT_PROTECT" 9 "CABIN_PURGE" 8 "OUTLET_TEMP_LIMIT" 7 "OCCUPANT_CONVECTION_REQUIREMENT" 6 "STRATIFICATION_INTERIOR_SURFACES" 5 "STRATIFICATION_GLASS_ROOF" 4 "MINIMUM_AUTO_AIRFLOW" 3 "CABIN_TEMPERATURE_CONTROL" 2 "UI_SHORTCUT" 1 "MANUAL_FAN_SPEED" 0 "HVAC_OFF" ;
VAL_ 691 VCRIGHT_airflowReasonAutoIn_0001 21 "NONE" 20 "ODOR_ROUTINE" 19 "DRIVERLESS_SELF_TEST" 18 "VOC_PURGE" 17 "STRATIFICATION_TOP_PAD_AREA" 16 "HOT_DUCT_LOCKOUT" 15 "COLD_DUCT_LOCKOUT" 14 "BIOWEAPON_DEFENSE" 13 "EVAP_OIL_PURGE" 12 "EVAP_DRYING" 11 "SCREEN_PROTECTION" 10 "CABIN_OVERHEAT_PROTECT" 9 "CABIN_PURGE" 8 "OUTLET_TEMP_LIMIT" 7 "OCCUPANT_CONVECTION_REQUIREMENT" 6 "STRATIFICATION_INTERIOR_SURFACES" 5 "STRATIFICATION_GLASS_ROOF" 4 "MINIMUM_AUTO_AIRFLOW" 3 "CABIN_TEMPERATURE_CONTROL" 2 "UI_SHORTCUT" 1 "MANUAL_FAN_SPEED" 0 "HVAC_OFF" ;
VAL_ 691 VCRIGHT_airflowReasonAutoIn_0002 21 "NONE" 20 "ODOR_ROUTINE" 19 "DRIVERLESS_SELF_TEST" 18 "VOC_PURGE" 17 "STRATIFICATION_TOP_PAD_AREA" 16 "HOT_DUCT_LOCKOUT" 15 "COLD_DUCT_LOCKOUT" 14 "BIOWEAPON_DEFENSE" 13 "EVAP_OIL_PURGE" 12 "EVAP_DRYING" 11 "SCREEN_PROTECTION" 10 "CABIN_OVERHEAT_PROTECT" 9 "CABIN_PURGE" 8 "OUTLET_TEMP_LIMIT" 7 "OCCUPANT_CONVECTION_REQUIREMENT" 6 "STRATIFICATION_INTERIOR_SURFACES" 5 "STRATIFICATION_GLASS_ROOF" 4 "MINIMUM_AUTO_AIRFLOW" 3 "CABIN_TEMPERATURE_CONTROL" 2 "UI_SHORTCUT" 1 "MANUAL_FAN_SPEED" 0 "HVAC_OFF" ;
VAL_ 691 VCRIGHT_VOCPurgeState 5 "PURGING_AND_DRYING" 4 "WAITING" 3 "PURGING" 2 "IDLE" 1 "INACTIVE" 0 "INIT" ;
VAL_ 691 VCRIGHT_cameraFoggingMonitorStat 6 "PRE_RUN_PURGE" 5 "IDLE" 4 "INACTIVE" 3 "RUNNING" 2 "WAKEUP" 1 "MONITORING" 0 "INIT" ;
VAL_ 691 VCRIGHT_hvacIntakeReason 26 "INTAKE_REASON_ODOR_ROUTINE" 25 "INTAKE_REASON_HVAC_OFF_IN_MOTION" 24 "INTAKE_REASON_LIFTGATE_CLOSING" 23 "INTAKE_REASON_DRIVERLESS_SELF_TEST" 22 "INTAKE_REASON_VOC_PURGE" 21 "INTAKE_REASON_STEAMING" 20 "INTAKE_REASON_PULLDOWN_IN_FRESH" 19 "INTAKE_REASON_RECIRC_NVH" 18 "INTAKE_REASON_CO2_PURGE" 17 "INTAKE_REASON_HVAC_OFF" 16 "INTAKE_REASON_PARK_POSITION" 15 "INTAKE_REASON_EVAP_DRYING" 14 "INTAKE_REASON_OIL_PURGE" 13 "INTAKE_REASON_CABIN_PURGE" 12 "INTAKE_REASON_COP" 11 "INTAKE_REASON_ENHANCED_FILTERATION" 10 "INTAKE_REASON_CHARGE_PORT_THAW" 9 "INTAKE_REASON_PRECON_OVERRIDE" 8 "INTAKE_REASON_HUMIDITY" 7 "INTAKE_REASON_BIO_WEAPON_STEADY" 6 "INTAKE_REASON_BIO_WEAPON_INIT" 5 "INTAKE_REASON_TEMPERATURE_CONTROL" 4 "INTAKE_REASON_MANUAL_RECIRC" 3 "INTAKE_REASON_MANUAL_FRESH" 2 "INTAKE_REASON_CAR_WASH" 1 "INTAKE_REASON_UDS" 0 "INTAKE_REASON_NONE" ;
VAL_ 691 VCRIGHT_hvacLimpModeStatus 4 "LIMP_MODE_FAULTED" 3 "LIMP_MODE_ACTIVE" 2 "LIMP_MODE_READY" 1 "LIMP_MODE_WAITING_FOR_SENSORS" 0 "LIMP_MODE_NOT_NEEDED" ;
VAL_ 1859 VCRIGHT_systemRecallStatus 3 "RECALL_INTERRUPTED" 2 "RECALL_COMPLETE" 1 "RECALL_IN_PROGRESS" 0 "RECALL_SNA" ;
VAL_ 1859 VCRIGHT_seatRecallStatus 3 "RECALL_INTERRUPTED" 2 "RECALL_COMPLETE" 1 "RECALL_IN_PROGRESS" 0 "RECALL_SNA" ;
VAL_ 1859 VCRIGHT_mirrorRecallStatus 3 "RECALL_INTERRUPTED" 2 "RECALL_COMPLETE" 1 "RECALL_IN_PROGRESS" 0 "RECALL_SNA" ;
VAL_ 1862 VCRIGHT_frontOccupancyStatus 7 "SEAT_OCCUPANCY_SNA" 3 "SEAT_NOT_CONFIGURED" 2 "SEAT_OCCUPANCY_FAULTED" 1 "SEAT_OCCUPIED" 0 "SEAT_UNOCCUPIED" ;
VAL_ 1862 VCRIGHT_frontBuckleStatus 3 "SEAT_BELT_BUCKLE_NOT_CONFIGURED" 2 "SEAT_BELT_BUCKLE_STATUS_FAULTED" 1 "SEAT_BELT_BUCKLE_STATUS_LATCHED" 0 "SEAT_BELT_BUCKLE_STATUS_UNLATCHED" ;
VAL_ 1862 VCRIGHT_rearCenterBuckleStatus 3 "SEAT_BELT_BUCKLE_NOT_CONFIGURED" 2 "SEAT_BELT_BUCKLE_STATUS_FAULTED" 1 "SEAT_BELT_BUCKLE_STATUS_LATCHED" 0 "SEAT_BELT_BUCKLE_STATUS_UNLATCHED" ;
VAL_ 1862 VCRIGHT_rearRightBuckleStatus 3 "SEAT_BELT_BUCKLE_NOT_CONFIGURED" 2 "SEAT_BELT_BUCKLE_STATUS_FAULTED" 1 "SEAT_BELT_BUCKLE_STATUS_LATCHED" 0 "SEAT_BELT_BUCKLE_STATUS_UNLATCHED" ;
VAL_ 1862 VCRIGHT_rearRightOccupancyStatus 3 "SEAT_NOT_CONFIGURED" 2 "SEAT_OCCUPANCY_FAULTED" 1 "SEAT_OCCUPIED" 0 "SEAT_UNOCCUPIED" ;
VAL_ 1862 VCRIGHT_3RowLeftBuckleStatus 3 "SEAT_BELT_BUCKLE_NOT_CONFIGURED" 2 "SEAT_BELT_BUCKLE_STATUS_FAULTED" 1 "SEAT_BELT_BUCKLE_STATUS_LATCHED" 0 "SEAT_BELT_BUCKLE_STATUS_UNLATCHED" ;
VAL_ 1862 VCRIGHT_3RowRightBuckleStatus 3 "SEAT_BELT_BUCKLE_NOT_CONFIGURED" 2 "SEAT_BELT_BUCKLE_STATUS_FAULTED" 1 "SEAT_BELT_BUCKLE_STATUS_LATCHED" 0 "SEAT_BELT_BUCKLE_STATUS_UNLATCHED" ;
VAL_ 1862 VCRIGHT_3RowLeftOccupancyStatus 3 "SEAT_NOT_CONFIGURED" 2 "SEAT_OCCUPANCY_FAULTED" 1 "SEAT_OCCUPIED" 0 "SEAT_UNOCCUPIED" ;
VAL_ 1862 VCRIGHT_3RowRightOccupancyStatus 3 "SEAT_NOT_CONFIGURED" 2 "SEAT_OCCUPANCY_FAULTED" 1 "SEAT_OCCUPIED" 0 "SEAT_UNOCCUPIED" ;
VAL_ 1862 VCRIGHT_seatTrackPosition 7 "SEAT_TRACK_POSITION_SNA" 3 "SEAT_TRACK_POSITION_FAULTED" 2 "SEAT_TRACK_POSITION_NOT_CONFIGURED" 1 "SEAT_TRACK_POSITION_REARWARD" 0 "SEAT_TRACK_POSITION_FORWARD" ;
VAL_ 1862 VCRIGHT_occupantClassification 7 "SEAT_OCCUPANT_CLASSIFICATON_SNA" 6 "SEAT_OCCUPANT_CLASSIFICATON_OUT_OF_POSITION" 5 "SEAT_OCCUPANT_CLASSIFICATON_NOT_CONFIGURED" 4 "SEAT_OCCUPANT_CLASSIFICATON_INIT" 3 "SEAT_OCCUPANT_CLASSIFICATON_LARGE" 2 "SEAT_OCCUPANT_CLASSIFICATON_SMALL" 1 "SEAT_OCCUPANT_CLASSIFICATON_INHIBIT" 0 "SEAT_OCCUPANT_CLASSIFICATON_EMPTY" ;
VAL_ 1862 VCRIGHT_occupantClassificationQF 1 "SEAT_OCCUPANT_CLASSIFICATON_NOT_FAULTED" 0 "SEAT_OCCUPANT_CLASSIFICATON_FAULTED" ;
VAL_ 1862 VCRIGHT_classificationEnabled 1 "VCRIGHT_CLASSIFICATION_SOURCE" 0 "OCS1P_CLASSIFICATION_SOURCE" ;
VAL_ 1862 VCRIGHT_classificationEnabledQF 1 "CLASSIFICATION_ENABLED_NOT_FAULTED" 0 "CLASSIFICATION_ENABLED_FAULTED" ;
VAL_ 1251 VCRIGHT_frontSeatTrackState 5 "SEAT_STATE_UNDEFINED" 4 "SEAT_STATE_CALIBRATING" 3 "SEAT_STATE_RECALLING" 2 "SEAT_STATE_MOVING_DOWN" 1 "SEAT_STATE_MOVING_UP" 0 "SEAT_STATE_STOPPED" ;
VAL_ 1251 VCRIGHT_frontSeatTrackBridgeSt 3 "IO_BRIDGE_STATE_COAST" 2 "IO_BRIDGE_STATE_BRAKE" 1 "IO_BRIDGE_STATE_ENABLED" 0 "IO_BRIDGE_STATE_DISABLED" ;
VAL_ 1251 VCRIGHT_frontSeatBackState 5 "SEAT_STATE_UNDEFINED" 4 "SEAT_STATE_CALIBRATING" 3 "SEAT_STATE_RECALLING" 2 "SEAT_STATE_MOVING_DOWN" 1 "SEAT_STATE_MOVING_UP" 0 "SEAT_STATE_STOPPED" ;
VAL_ 1251 VCRIGHT_frontSeatBackBridgeSt 3 "IO_BRIDGE_STATE_COAST" 2 "IO_BRIDGE_STATE_BRAKE" 1 "IO_BRIDGE_STATE_ENABLED" 0 "IO_BRIDGE_STATE_DISABLED" ;
VAL_ 1251 VCRIGHT_frontSeatLiftState 5 "SEAT_STATE_UNDEFINED" 4 "SEAT_STATE_CALIBRATING" 3 "SEAT_STATE_RECALLING" 2 "SEAT_STATE_MOVING_DOWN" 1 "SEAT_STATE_MOVING_UP" 0 "SEAT_STATE_STOPPED" ;
VAL_ 1251 VCRIGHT_frontSeatLiftBridgeSt 3 "IO_BRIDGE_STATE_COAST" 2 "IO_BRIDGE_STATE_BRAKE" 1 "IO_BRIDGE_STATE_ENABLED" 0 "IO_BRIDGE_STATE_DISABLED" ;
VAL_ 1251 VCRIGHT_frontSeatTiltState 5 "SEAT_STATE_UNDEFINED" 4 "SEAT_STATE_CALIBRATING" 3 "SEAT_STATE_RECALLING" 2 "SEAT_STATE_MOVING_DOWN" 1 "SEAT_STATE_MOVING_UP" 0 "SEAT_STATE_STOPPED" ;
VAL_ 1251 VCRIGHT_frontSeatTiltBridgeSt 3 "IO_BRIDGE_STATE_COAST" 2 "IO_BRIDGE_STATE_BRAKE" 1 "IO_BRIDGE_STATE_ENABLED" 0 "IO_BRIDGE_STATE_DISABLED" ;
VAL_ 1251 VCRIGHT_lumbarAState 5 "SEAT_STATE_UNDEFINED" 4 "SEAT_STATE_CALIBRATING" 3 "SEAT_STATE_RECALLING" 2 "SEAT_STATE_MOVING_DOWN" 1 "SEAT_STATE_MOVING_UP" 0 "SEAT_STATE_STOPPED" ;
VAL_ 1251 VCRIGHT_lumbarBState 5 "SEAT_STATE_UNDEFINED" 4 "SEAT_STATE_CALIBRATING" 3 "SEAT_STATE_RECALLING" 2 "SEAT_STATE_MOVING_DOWN" 1 "SEAT_STATE_MOVING_UP" 0 "SEAT_STATE_STOPPED" ;
VAL_ 739 VCRIGHT_2RowSeatReclineState 15 "SEAT_ADJUSTABLE_FOLD_FLAT_STATE_SNA" 12 "SEAT_ADJUSTABLE_FOLD_FLAT_STATE_CALIBRATING_ABSOLUTE_SENSOR" 11 "SEAT_ADJUSTABLE_FOLD_FLAT_STATE_CALIBRATING_ZERO_POSITION" 10 "SEAT_ADJUSTABLE_FOLD_FLAT_STATE_WAITING_TO_CLEAR_FOR_UNFOLD" 9 "SEAT_ADJUSTABLE_FOLD_FLAT_STATE_WAITING_TO_CLEAR_FOR_FOLD" 8 "SEAT_ADJUSTABLE_FOLD_FLAT_STATE_MOVING_REARWARD_TO_POSITION" 7 "SEAT_ADJUSTABLE_FOLD_FLAT_STATE_MOVING_FORWARD_TO_POSITION" 6 "SEAT_ADJUSTABLE_FOLD_FLAT_STATE_UNFOLDING" 5 "SEAT_ADJUSTABLE_FOLD_FLAT_STATE_FOLDING" 4 "SEAT_ADJUSTABLE_FOLD_FLAT_STATE_ADJUSTING_REARWARD_FAST" 3 "SEAT_ADJUSTABLE_FOLD_FLAT_STATE_ADJUSTING_FORWARD_FAST" 2 "SEAT_ADJUSTABLE_FOLD_FLAT_STATE_ADJUSTING_REARWARD_COMFORT" 1 "SEAT_ADJUSTABLE_FOLD_FLAT_STATE_ADJUSTING_FORWARD_COMFORT" 0 "SEAT_ADJUSTABLE_FOLD_FLAT_STATE_STOPPED" ;
VAL_ 739 VCRIGHT_2RowSeatReclineAbsPosSwi 3 "SWITCH_FAULT" 2 "SWITCH_ON" 1 "SWITCH_OFF" 0 "SWITCH_SNA" ;
VAL_ 739 VCRIGHT_2RowSeatReclinePositionS 4 "SEAT_ADJUSTABLE_FOLD_FLAT_POSITION_STATE_SNA" 3 "SEAT_ADJUSTABLE_FOLD_FLAT_POSITION_STATE_UNKNOWN" 2 "SEAT_ADJUSTABLE_FOLD_FLAT_POSITION_STATE_UNSAFE_INTERMEDIATE" 1 "SEAT_ADJUSTABLE_FOLD_FLAT_POSITION_STATE_UNFOLDED" 0 "SEAT_ADJUSTABLE_FOLD_FLAT_POSITION_STATE_FOLDED" ;
VAL_ 739 VCRIGHT_2RowSeatReclineNextToggl 2 "SEAT_ADJUSTABLE_FOLD_FLAT_NEXT_TOGGLE_DIRECTION_SNA" 1 "SEAT_ADJUSTABLE_FOLD_FLAT_NEXT_TOGGLE_DIRECTION_UNFOLD" 0 "SEAT_ADJUSTABLE_FOLD_FLAT_NEXT_TOGGLE_DIRECTION_FOLD" ;
VAL_ 739 VCRIGHT_2RowSeat1RClashAvoidance 6 "SEAT_FOLD_FLAT_CLASH_AVOIDANCE_REASON_FRONT_SEAT_OCCUPANCY" 5 "SEAT_FOLD_FLAT_CLASH_AVOIDANCE_REASON_FRONT_SEAT_MOVING" 4 "SEAT_FOLD_FLAT_CLASH_AVOIDANCE_REASON_FRONT_SEAT_PROFILE_RECALL" 3 "SEAT_FOLD_FLAT_CLASH_AVOIDANCE_REASON_REAR_SEAT_UNCALIBRATED" 2 "SEAT_FOLD_FLAT_CLASH_AVOIDANCE_REASON_FRONT_SEAT_UNCALIBRATED" 1 "SEAT_FOLD_FLAT_CLASH_AVOIDANCE_REASON_VEHICLE_IN_MOTION" 0 "SEAT_FOLD_FLAT_CLASH_AVOIDANCE_REASON_NONE" ;
VAL_ 739 VCRIGHT_2RowSeat1RClashAvoi_0001 3 "SEAT_FOLD_FLAT_CLASH_AVOIDANCE_STATE_RESTORING_FRONT_SEAT" 2 "SEAT_FOLD_FLAT_CLASH_AVOIDANCE_STATE_WAITING_TO_RESTORE_FRONT_SEAT" 1 "SEAT_FOLD_FLAT_CLASH_AVOIDANCE_STATE_FRONT_SEAT_CLEARING" 0 "SEAT_FOLD_FLAT_CLASH_AVOIDANCE_STATE_IDLE" ;
VAL_ 835 VCRIGHT_LVBatteryTypeDBG 5 "LV_BATTERY_TYPE_TESLA_48V_LI_ION" 4 "LV_BATTERY_TYPE_TESLA_16V_LI_ION" 3 "LV_BATTERY_TYPE_CATL_LI_ION" 2 "LV_BATTERY_TYPE_CLARIOS_B24_FLOODED" 1 "LV_BATTERY_TYPE_ATLASBX_B24_FLOODED" 0 "LV_BATTERY_TYPE_UNKNOWN" ;
VAL_ 835 VCRIGHT_rearDefrostState 4 "HEATER_STATE_FAULT" 3 "HEATER_STATE_OFF_UNAVAILABLE" 2 "HEATER_STATE_OFF" 1 "HEATER_STATE_ON" 0 "HEATER_STATE_SNA" ;
VAL_ 835 VCRIGHT_mirrorHeatState 4 "HEATER_STATE_FAULT" 3 "HEATER_STATE_OFF_UNAVAILABLE" 2 "HEATER_STATE_OFF" 1 "HEATER_STATE_ON" 0 "HEATER_STATE_SNA" ;
VAL_ 963 VCRIGHT_frontSeatTrackBack 3 "SWITCH_FAULT" 2 "SWITCH_ON" 1 "SWITCH_OFF" 0 "SWITCH_SNA" ;
VAL_ 963 VCRIGHT_frontSeatTrackForward 3 "SWITCH_FAULT" 2 "SWITCH_ON" 1 "SWITCH_OFF" 0 "SWITCH_SNA" ;
VAL_ 963 VCRIGHT_frontSeatTiltDown 3 "SWITCH_FAULT" 2 "SWITCH_ON" 1 "SWITCH_OFF" 0 "SWITCH_SNA" ;
VAL_ 963 VCRIGHT_frontSeatTiltUp 3 "SWITCH_FAULT" 2 "SWITCH_ON" 1 "SWITCH_OFF" 0 "SWITCH_SNA" ;
VAL_ 963 VCRIGHT_frontSeatLiftDown 3 "SWITCH_FAULT" 2 "SWITCH_ON" 1 "SWITCH_OFF" 0 "SWITCH_SNA" ;
VAL_ 963 VCRIGHT_frontSeatLiftUp 3 "SWITCH_FAULT" 2 "SWITCH_ON" 1 "SWITCH_OFF" 0 "SWITCH_SNA" ;
VAL_ 963 VCRIGHT_frontSeatBackrestBack 3 "SWITCH_FAULT" 2 "SWITCH_ON" 1 "SWITCH_OFF" 0 "SWITCH_SNA" ;
VAL_ 963 VCRIGHT_frontSeatBackrestForward 3 "SWITCH_FAULT" 2 "SWITCH_ON" 1 "SWITCH_OFF" 0 "SWITCH_SNA" ;
VAL_ 963 VCRIGHT_frontSeatLumbarDown 3 "SWITCH_FAULT" 2 "SWITCH_ON" 1 "SWITCH_OFF" 0 "SWITCH_SNA" ;
VAL_ 963 VCRIGHT_frontSeatLumbarUp 3 "SWITCH_FAULT" 2 "SWITCH_ON" 1 "SWITCH_OFF" 0 "SWITCH_SNA" ;
VAL_ 963 VCRIGHT_frontSeatLumbarIn 3 "SWITCH_FAULT" 2 "SWITCH_ON" 1 "SWITCH_OFF" 0 "SWITCH_SNA" ;
VAL_ 963 VCRIGHT_frontSeatLumbarOut 3 "SWITCH_FAULT" 2 "SWITCH_ON" 1 "SWITCH_OFF" 0 "SWITCH_SNA" ;
VAL_ 963 VCRIGHT_frontSeatALR 3 "SWITCH_FAULT" 2 "SWITCH_ON" 1 "SWITCH_OFF" 0 "SWITCH_SNA" ;
VAL_ 963 VCRIGHT_frontSeatResistiveOccupa 3 "SWITCH_FAULT" 2 "SWITCH_ON" 1 "SWITCH_OFF" 0 "SWITCH_SNA" ;
VAL_ 963 VCRIGHT_2RowSeatReclineSwitchpac 6 "FAULT" 5 "REARWARD_FAST" 4 "REARWARD_SLOW" 3 "FORWARD_FAST" 2 "FORWARD_SLOW" 1 "INACTIVE" 0 "DISCONNECTED" ;
VAL_ 899 VCRIGHT_thsState 4 "IDLE" 3 "WAIT_CRC_RESPONSE" 2 "WAIT_CRC_REQUEST" 1 "CONFIG" 0 "INIT" ;
VAL_ 899 VCRIGHT_thsLINCurrentSchedule 7 "OTHER" 3 "DIAGNOSTIC" 2 "CONFIG" 1 "MAIN" 0 "OFF" ;
VAL_ 899 VCRIGHT_estimatedVehicleSituatio 2 "VEHICLE_SITUATION_OUTDOOR" 1 "VEHICLE_SITUATION_INDOOR" 0 "VEHICLE_SITUATION_UNKNOWN" ;
VAL_ 1059 VCRIGHT_nmKeepAwakeReason 31 "VCRIGHT_KEEPAWAKE_REASON_MULTIPLE" 17 "VCRIGHT_KEEPAWAKE_REASON_DEFOG_CMD" 16 "VCRIGHT_KEEPAWAKE_REASON_DEFOG_CAMERA" 15 "VCRIGHT_KEEPAWAKE_REASON_VOC_PURGE" 14 "VCRIGHT_KEEPAWAKE_REASON_OTHER" 12 "VCRIGHT_KEEPAWAKE_REASON_TRUNK_SWITCH" 11 "VCRIGHT_KEEPAWAKE_REASON_HVAC_EVAP_DRYING" 10 "VCRIGHT_KEEPAWAKE_REASON_UDS_ACTIVE" 9 "VCRIGHT_KEEPAWAKE_REASON_TRUNK_LIGHT" 8 "VCRIGHT_KEEPAWAKE_REASON_SEAT" 7 "VCRIGHT_KEEPAWAKE_REASON_HANDLE" 6 "VCRIGHT_KEEPAWAKE_REASON_EPB_SUMMON_ACTIVE" 5 "VCRIGHT_KEEPAWAKE_REASON_CLOSURE_LATCH" 4 "VCRIGHT_KEEPAWAKE_REASON_HVAC_PRECONDITIONING" 3 "VCRIGHT_KEEPAWAKE_REASON_HVAC_CABIN_PURGE" 2 "VCRIGHT_KEEPAWAKE_REASON_EPB_NOT_SECURE" 1 "VCRIGHT_KEEPAWAKE_REASON_EPB_STATE_NOT_SAVED" 0 "VCRIGHT_KEEPAWAKE_REASON_NONE_SNA" ;
VAL_ 1059 VCRIGHT_nmWakeUpReason 15 "VCRIGHT_WAKEUP_REASON_UNKNOWN" 14 "VCRIGHT_WAKEUP_REASON_DEFOG_CMD" 13 "VCRIGHT_WAKEUP_REASON_DEFOG_CAMERA" 12 "VCRIGHT_WAKEUP_REASON_VOC_PURGE" 11 "VCRIGHT_WAKEUP_REASON_POWER_ON_RESET" 10 "VCRIGHT_WAKEUP_REASON_CABIN_HOT" 9 "VCRIGHT_WAKEUP_REASON_TRUNK_LATCH" 8 "VCRIGHT_WAKEUP_REASON_TRUNK_SWITCH" 7 "VCRIGHT_WAKEUP_REASON_LIN_RX" 6 "VCRIGHT_WAKEUP_REASON_EXTERIOR_HANDLE" 5 "VCRIGHT_WAKEUP_REASON_INTERIOR_HANDLE" 4 "VCRIGHT_WAKEUP_REASON_DOOR_LATCH" 3 "VCRIGHT_WAKEUP_REASON_RESET" 2 "VCRIGHT_WAKEUP_REASON_SWITCH_INPUT" 1 "VCRIGHT_WAKEUP_REASON_ECU_SPECIFIC" 0 "VCRIGHT_WAKEUP_REASON_NONE" ;
VAL_ 1059 VCRIGHT_nmDebugWakeUp 2147483648 "WKPU_31" 1073741824 "WKPU_30" 536870912 "WKPU_29" 268435456 "WKPU_28" 134217728 "WKPU_27" 67108864 "WKPU_26" 33554432 "WKPU_25" 16777216 "WKPU_24" 8388608 "WKPU_23" 4194304 "WKPU_22" 2097152 "WKPU_21" 1048576 "WKPU_20" 524288 "WKPU_19" 262144 "WKPU_18" 131072 "WKPU_17" 65536 "WKPU_16" 32768 "WKPU_15" 16384 "WKPU_14" 8192 "WKPU_13" 4096 "WKPU_12" 2048 "WKPU_11" 1024 "WKPU_10" 512 "WKPU_9" 256 "WKPU_8" 128 "WKPU_7" 64 "WKPU_6" 32 "WKPU_5" 16 "WKPU_4" 8 "WKPU_3" 4 "WKPU_2" 2 "WKPU_1" 1 "WKPU_0" 0 "WKPU_NONE" ;
VAL_ 1059 VCRIGHT_nmEthKeepAwakeReason 15 "VCRIGHT_ETH_KEEPAWAKE_REASON_MULTIPLE" 14 "VCRIGHT_ETH_KEEPAWAKE_REASON_OTHER" 6 "VCRIGHT_ETH_KEEPAWAKE_REASON_TEMP_SENSE_COP_VARIANT_ACTIVE" 5 "VCRIGHT_ETH_KEEPAWAKE_REASON_TEMP_SENSE_POLL" 4 "VCRIGHT_ETH_KEEPAWAKE_REASON_TEMP_SENSE_VCSEC_WAKE" 3 "VCRIGHT_ETH_KEEPAWAKE_REASON_TEMP_SENSE_DWELL_TIME_END" 2 "VCRIGHT_ETH_KEEPAWAKE_REASON_TEMP_SENSE_TRANSITION_FROM_OFF" 1 "VCRIGHT_ETH_KEEPAWAKE_REASON_TEMP_SENSE_TRANSITION_FROM_ACC" 0 "VCRIGHT_ETH_KEEPAWAKE_REASON_NONE_SNA" ;
VAL_ 1059 VCRIGHT_nmChKeepAwakeReason 15 "VCRIGHT_CH_KEEPAWAKE_REASON_MULTIPLE" 14 "VCRIGHT_CH_KEEPAWAKE_REASON_OTHER" 2 "VCRIGHT_CH_KEEPAWAKE_REASON_DEFOG_CMD" 1 "VCRIGHT_CH_KEEPAWAKE_REASON_DEFOG_CAMERA" 0 "VCRIGHT_CH_KEEPAWAKE_REASON_NONE_SNA" ;
VAL_ 707 VCRIGHT_windowStateRF 10 "WINDOW_STATE_SHORT_RISE_REVERSE" 9 "WINDOW_STATE_SHORT_RISE" 8 "WINDOW_STATE_BACKDRIVE" 7 "WINDOW_STATE_MOVING_AUTO_DOWN" 6 "WINDOW_STATE_MOVING_AUTO_UP" 5 "WINDOW_STATE_SHORT_DROP_REVERSE" 4 "WINDOW_STATE_SHORT_DROP" 3 "WINDOW_STATE_BACKOFF" 2 "WINDOW_STATE_MOVING_DOWN" 1 "WINDOW_STATE_MOVING_UP" 0 "WINDOW_STATE_STOPPED" ;
VAL_ 707 VCRIGHT_windowTrimClearMoveReque 3 "WINDOW_TRIM_CLEAR_MOVE_REQUEST_BACKDRIVE" 2 "WINDOW_TRIM_CLEAR_MOVE_REQUEST_RESEAL" 1 "WINDOW_TRIM_CLEAR_MOVE_REQUEST_IDLE" 0 "WINDOW_TRIM_CLEAR_MOVE_REQUEST_SNA" ;
VAL_ 707 VCRIGHT_windowTrimClearActiveReq 2 "WINDOW_TRIM_CLEAR_ACTIVE_REQUEST_ACTIVE" 1 "WINDOW_TRIM_CLEAR_ACTIVE_REQUEST_INACTIVE" 0 "WINDOW_TRIM_CLEAR_ACTIVE_REQUEST_SNA" ;
VAL_ 707 VCRIGHT_windowStateRR 10 "WINDOW_STATE_SHORT_RISE_REVERSE" 9 "WINDOW_STATE_SHORT_RISE" 8 "WINDOW_STATE_BACKDRIVE" 7 "WINDOW_STATE_MOVING_AUTO_DOWN" 6 "WINDOW_STATE_MOVING_AUTO_UP" 5 "WINDOW_STATE_SHORT_DROP_REVERSE" 4 "WINDOW_STATE_SHORT_DROP" 3 "WINDOW_STATE_BACKOFF" 2 "WINDOW_STATE_MOVING_DOWN" 1 "WINDOW_STATE_MOVING_UP" 0 "WINDOW_STATE_STOPPED" ;
VAL_ 707 VCRIGHT_windowThermalModeRF 3 "WINDOW_THERMAL_MODE_CRITICAL" 2 "WINDOW_THERMAL_MODE_ALERT" 1 "WINDOW_THERMAL_MODE_NORMAL" 0 "WINDOW_THERMAL_MODE_SNA" ;
VAL_ 707 VCRIGHT_windowStopReasonRF 6 "WINDOW_STOP_REASON_STATE_TIMEOUT" 5 "WINDOW_STOP_REASON_FULL_OPEN_SOFT_STOP" 4 "WINDOW_STOP_REASON_STOP_REQUEST" 3 "WINDOW_STOP_REASON_TARGET_REACHED" 2 "WINDOW_STOP_REASON_NEW_REQUEST" 1 "WINDOW_STOP_REASON_DOOR_OPEN_TRIM_PROTECT" 0 "WINDOW_STOP_REASON_NONE" ;
VAL_ 707 VCRIGHT_windowStopReqReasonRF 8 "WINDOW_STOP_REQUEST_REASON_EXTERNAL_REQUEST" 7 "WINDOW_STOP_REQUEST_REASON_FULL_OPEN_SOFT_STOP" 6 "WINDOW_STOP_REQUEST_REASON_STATE_TIMEOUT" 5 "WINDOW_STOP_REQUEST_REASON_STALL" 4 "WINDOW_STOP_REQUEST_REASON_THERMAL" 3 "WINDOW_STOP_REQUEST_REASON_REAR_LOCKOUT" 2 "WINDOW_STOP_REQUEST_REASON_SWITCH_RELEASED" 1 "WINDOW_STOP_REQUEST_REASON_SWITCH_CANCEL_AUTO_MOVEMENT" 0 "WINDOW_STOP_REQUEST_REASON_NONE" ;
VAL_ 707 VCRIGHT_windowThermalModeRR 3 "WINDOW_THERMAL_MODE_CRITICAL" 2 "WINDOW_THERMAL_MODE_ALERT" 1 "WINDOW_THERMAL_MODE_NORMAL" 0 "WINDOW_THERMAL_MODE_SNA" ;
VAL_ 707 VCRIGHT_windowStopReasonRR 6 "WINDOW_STOP_REASON_STATE_TIMEOUT" 5 "WINDOW_STOP_REASON_FULL_OPEN_SOFT_STOP" 4 "WINDOW_STOP_REASON_STOP_REQUEST" 3 "WINDOW_STOP_REASON_TARGET_REACHED" 2 "WINDOW_STOP_REASON_NEW_REQUEST" 1 "WINDOW_STOP_REASON_DOOR_OPEN_TRIM_PROTECT" 0 "WINDOW_STOP_REASON_NONE" ;
VAL_ 707 VCRIGHT_windowStopReqReasonRR 8 "WINDOW_STOP_REQUEST_REASON_EXTERNAL_REQUEST" 7 "WINDOW_STOP_REQUEST_REASON_FULL_OPEN_SOFT_STOP" 6 "WINDOW_STOP_REQUEST_REASON_STATE_TIMEOUT" 5 "WINDOW_STOP_REQUEST_REASON_STALL" 4 "WINDOW_STOP_REQUEST_REASON_THERMAL" 3 "WINDOW_STOP_REQUEST_REASON_REAR_LOCKOUT" 2 "WINDOW_STOP_REQUEST_REASON_SWITCH_RELEASED" 1 "WINDOW_STOP_REQUEST_REASON_SWITCH_CANCEL_AUTO_MOVEMENT" 0 "WINDOW_STOP_REQUEST_REASON_NONE" ;
VAL_ 707 VCRIGHT_windowControlStateRF 2 "WINDOW_CONTROL_STATE_GOING_TO_POSITION" 1 "WINDOW_CONTROL_STATE_CLOSING" 0 "WINDOW_CONTROL_STATE_IDLE" ;
VAL_ 707 VCRIGHT_windowCtrlUnavailableRF 7 "WINDOW_CONTROL_UNAVAILABLE_REASON_WINDOW_MOVING" 6 "WINDOW_CONTROL_UNAVAILABLE_REASON_VEHICLE_IN_DRIVE" 5 "WINDOW_CONTROL_UNAVAILABLE_REASON_UNCALIBRATED" 4 "WINDOW_CONTROL_UNAVAILABLE_REASON_THERMAL_LIMIT" 3 "WINDOW_CONTROL_UNAVAILABLE_REASON_PINCH" 2 "WINDOW_CONTROL_UNAVAILABLE_REASON_SWITCH_PRESSED" 1 "WINDOW_CONTROL_UNAVAILABLE_REASON_UNEXPECTED" 0 "WINDOW_CONTROL_UNAVAILABLE_REASON_NONE" ;
VAL_ 707 VCRIGHT_windowControlStateRR 2 "WINDOW_CONTROL_STATE_GOING_TO_POSITION" 1 "WINDOW_CONTROL_STATE_CLOSING" 0 "WINDOW_CONTROL_STATE_IDLE" ;
VAL_ 707 VCRIGHT_windowCtrlUnavailableRR 7 "WINDOW_CONTROL_UNAVAILABLE_REASON_WINDOW_MOVING" 6 "WINDOW_CONTROL_UNAVAILABLE_REASON_VEHICLE_IN_DRIVE" 5 "WINDOW_CONTROL_UNAVAILABLE_REASON_UNCALIBRATED" 4 "WINDOW_CONTROL_UNAVAILABLE_REASON_THERMAL_LIMIT" 3 "WINDOW_CONTROL_UNAVAILABLE_REASON_PINCH" 2 "WINDOW_CONTROL_UNAVAILABLE_REASON_SWITCH_PRESSED" 1 "WINDOW_CONTROL_UNAVAILABLE_REASON_UNEXPECTED" 0 "WINDOW_CONTROL_UNAVAILABLE_REASON_NONE" ;
VAL_ 707 VCRIGHT_windowPositionStateRF 7 "WINDOW_POSITION_CLOSED_TRIM_CLEAR" 6 "WINDOW_POSITION_FULL_OPEN" 5 "WINDOW_POSITION_PARTIAL_OPEN" 4 "WINDOW_POSITION_DAS_LIMITED" 3 "WINDOW_POSITION_VENT" 2 "WINDOW_POSITION_CRACKED" 1 "WINDOW_POSITION_CLOSED" 0 "WINDOW_POSITION_UNKNOWN" ;
VAL_ 707 VCRIGHT_windowPositionStateRR 7 "WINDOW_POSITION_CLOSED_TRIM_CLEAR" 6 "WINDOW_POSITION_FULL_OPEN" 5 "WINDOW_POSITION_PARTIAL_OPEN" 4 "WINDOW_POSITION_DAS_LIMITED" 3 "WINDOW_POSITION_VENT" 2 "WINDOW_POSITION_CRACKED" 1 "WINDOW_POSITION_CLOSED" 0 "WINDOW_POSITION_UNKNOWN" ;
VAL_ 707 VCRIGHT_windowVehGearStateRF 2 "WINDOW_VEHICLE_GEAR_STATE_IN_GEAR" 1 "WINDOW_VEHICLE_GEAR_STATE_PARK" 0 "WINDOW_VEHICLE_GEAR_STATE_UNKNOWN_SNA" ;
VAL_ 707 VCRIGHT_windowVehGearStateRR 2 "WINDOW_VEHICLE_GEAR_STATE_IN_GEAR" 1 "WINDOW_VEHICLE_GEAR_STATE_PARK" 0 "WINDOW_VEHICLE_GEAR_STATE_UNKNOWN_SNA" ;
VAL_ 707 VCRIGHT_windowSpeedTableStatusRF 2 "WINDOW_SPEED_TABLE_STATUS_FULLY_BUILT" 1 "WINDOW_SPEED_TABLE_STATUS_SENSITIVE_BUILT" 0 "WINDOW_SPEED_TABLE_STATUS_EMPTY_SNA" ;
VAL_ 707 VCRIGHT_windowSpeedTableStatusRR 2 "WINDOW_SPEED_TABLE_STATUS_FULLY_BUILT" 1 "WINDOW_SPEED_TABLE_STATUS_SENSITIVE_BUILT" 0 "WINDOW_SPEED_TABLE_STATUS_EMPTY_SNA" ;
